[part 2 of 2: package /MICROSAR/Dem_swc/ComponentTypes]
AUTOSAR XML (schema 00046)
package /MICROSAR/Dem_swc/ComponentTypes  (continued)
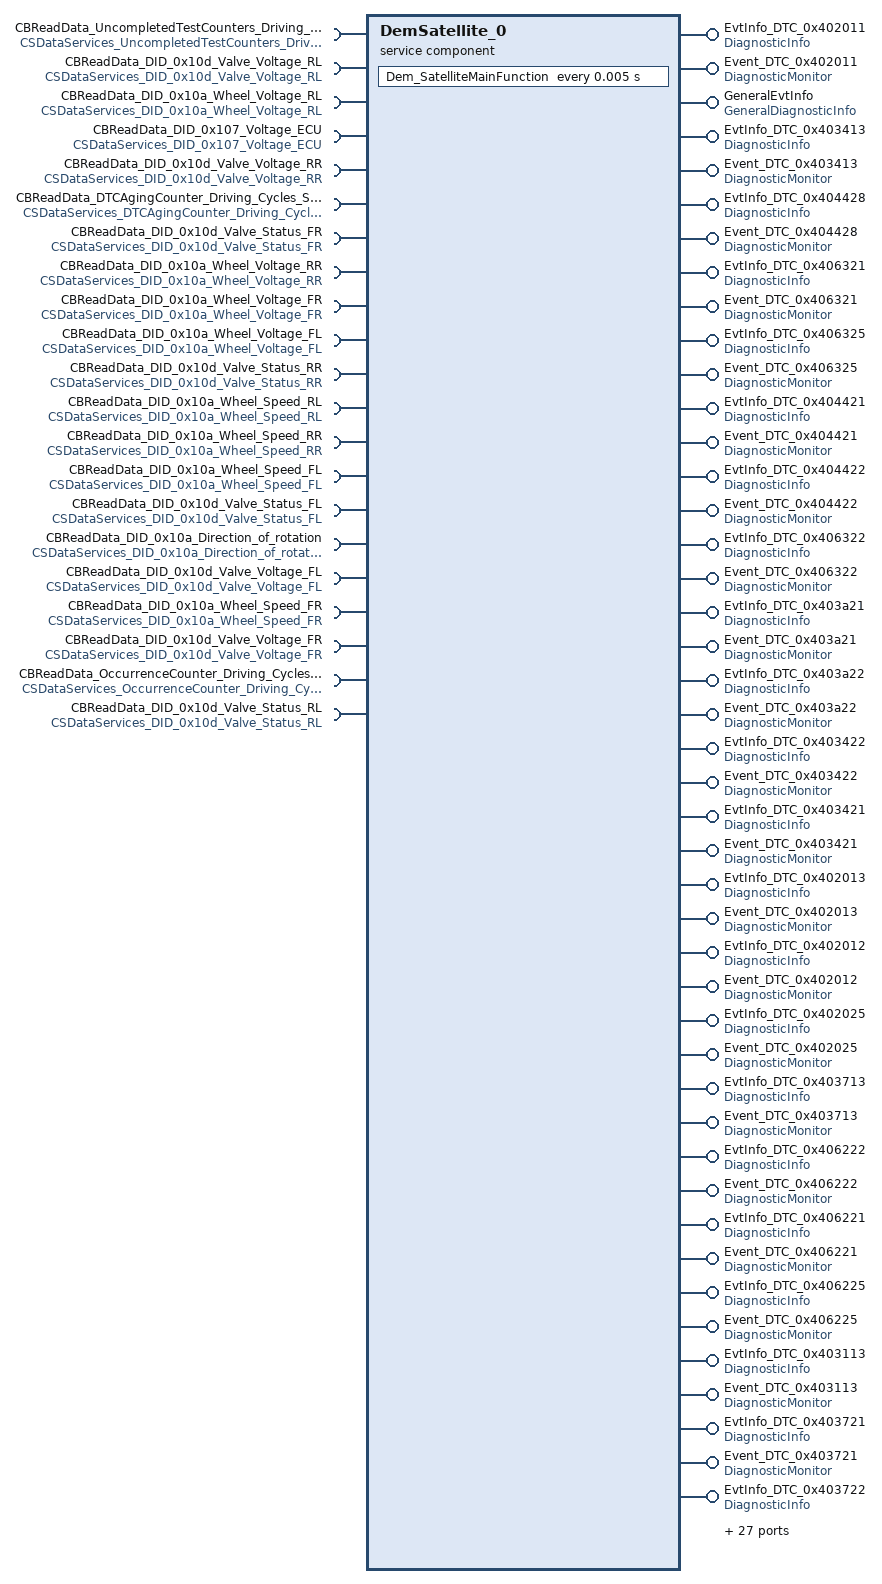
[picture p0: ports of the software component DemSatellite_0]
  service sw component type DemSatellite_0: category=SERVICE_COMPONENT
    63 x provide port:
      EvtInfo_DTC_0x402011: provided-interface=DiagnosticInfo
      Event_DTC_0x402011: provided-interface=DiagnosticMonitor
      GeneralEvtInfo: provided-interface=GeneralDiagnosticInfo
      EvtInfo_DTC_0x403413: provided-interface=DiagnosticInfo
      Event_DTC_0x403413: provided-interface=DiagnosticMonitor
      EvtInfo_DTC_0x404428: provided-interface=DiagnosticInfo
      Event_DTC_0x404428: provided-interface=DiagnosticMonitor
      EvtInfo_DTC_0x406321: provided-interface=DiagnosticInfo
      Event_DTC_0x406321: provided-interface=DiagnosticMonitor
      EvtInfo_DTC_0x406325: provided-interface=DiagnosticInfo
      Event_DTC_0x406325: provided-interface=DiagnosticMonitor
      EvtInfo_DTC_0x404421: provided-interface=DiagnosticInfo
      Event_DTC_0x404421: provided-interface=DiagnosticMonitor
      EvtInfo_DTC_0x404422: provided-interface=DiagnosticInfo
      Event_DTC_0x404422: provided-interface=DiagnosticMonitor
      EvtInfo_DTC_0x406322: provided-interface=DiagnosticInfo
      Event_DTC_0x406322: provided-interface=DiagnosticMonitor
      EvtInfo_DTC_0x403a21: provided-interface=DiagnosticInfo
      Event_DTC_0x403a21: provided-interface=DiagnosticMonitor
      EvtInfo_DTC_0x403a22: provided-interface=DiagnosticInfo
      Event_DTC_0x403a22: provided-interface=DiagnosticMonitor
      EvtInfo_DTC_0x403422: provided-interface=DiagnosticInfo
      Event_DTC_0x403422: provided-interface=DiagnosticMonitor
      EvtInfo_DTC_0x403421: provided-interface=DiagnosticInfo
      Event_DTC_0x403421: provided-interface=DiagnosticMonitor
      EvtInfo_DTC_0x402013: provided-interface=DiagnosticInfo
      Event_DTC_0x402013: provided-interface=DiagnosticMonitor
      EvtInfo_DTC_0x402012: provided-interface=DiagnosticInfo
      Event_DTC_0x402012: provided-interface=DiagnosticMonitor
      EvtInfo_DTC_0x402025: provided-interface=DiagnosticInfo
      Event_DTC_0x402025: provided-interface=DiagnosticMonitor
      EvtInfo_DTC_0x403713: provided-interface=DiagnosticInfo
      Event_DTC_0x403713: provided-interface=DiagnosticMonitor
      EvtInfo_DTC_0x406222: provided-interface=DiagnosticInfo
      Event_DTC_0x406222: provided-interface=DiagnosticMonitor
      EvtInfo_DTC_0x406221: provided-interface=DiagnosticInfo
      Event_DTC_0x406221: provided-interface=DiagnosticMonitor
      EvtInfo_DTC_0x406225: provided-interface=DiagnosticInfo
      Event_DTC_0x406225: provided-interface=DiagnosticMonitor
      EvtInfo_DTC_0x403113: provided-interface=DiagnosticInfo
      Event_DTC_0x403113: provided-interface=DiagnosticMonitor
      EvtInfo_DTC_0x403721: provided-interface=DiagnosticInfo
      Event_DTC_0x403721: provided-interface=DiagnosticMonitor
      EvtInfo_DTC_0x403722: provided-interface=DiagnosticInfo
      Event_DTC_0x403722: provided-interface=DiagnosticMonitor
      EvtInfo_DTC_0x404011: provided-interface=DiagnosticInfo
      Event_DTC_0x404011: provided-interface=DiagnosticMonitor
      EvtInfo_DTC_0x404212: provided-interface=DiagnosticInfo
      Event_DTC_0x404212: provided-interface=DiagnosticMonitor
      EvtInfo_DTC_0x404213: provided-interface=DiagnosticInfo
      Event_DTC_0x404213: provided-interface=DiagnosticMonitor
      EvtInfo_DTC_0x404012: provided-interface=DiagnosticInfo
      Event_DTC_0x404012: provided-interface=DiagnosticMonitor
      EvtInfo_DTC_0x403121: provided-interface=DiagnosticInfo
      Event_DTC_0x403121: provided-interface=DiagnosticMonitor
      EvtInfo_DTC_0x404211: provided-interface=DiagnosticInfo
      Event_DTC_0x404211: provided-interface=DiagnosticMonitor
      EvtInfo_DTC_0x404013: provided-interface=DiagnosticInfo
      Event_DTC_0x404013: provided-interface=DiagnosticMonitor
      EvtInfo_DTC_0x403122: provided-interface=DiagnosticInfo
      Event_DTC_0x403122: provided-interface=DiagnosticMonitor
      EvtInfo_DTC_0x403a13: provided-interface=DiagnosticInfo
      Event_DTC_0x403a13: provided-interface=DiagnosticMonitor
    21 x require port:
      CBReadData_UncompletedTestCounters_Driving_Cycles_Since_Last_Completed: required-interface=CSDataServices_UncompletedTestCounters_Driving_Cycles_Since_Last_Completed
      CBReadData_DID_0x10d_Valve_Voltage_RL: required-interface=CSDataServices_DID_0x10d_Valve_Voltage_RL
      CBReadData_DID_0x10a_Wheel_Voltage_RL: required-interface=CSDataServices_DID_0x10a_Wheel_Voltage_RL
      CBReadData_DID_0x107_Voltage_ECU: required-interface=CSDataServices_DID_0x107_Voltage_ECU
      CBReadData_DID_0x10d_Valve_Voltage_RR: required-interface=CSDataServices_DID_0x10d_Valve_Voltage_RR
      CBReadData_DTCAgingCounter_Driving_Cycles_Since_Last_Failed: required-interface=CSDataServices_DTCAgingCounter_Driving_Cycles_Since_Last_Failed
      CBReadData_DID_0x10d_Valve_Status_FR: required-interface=CSDataServices_DID_0x10d_Valve_Status_FR
      CBReadData_DID_0x10a_Wheel_Voltage_RR: required-interface=CSDataServices_DID_0x10a_Wheel_Voltage_RR
      CBReadData_DID_0x10a_Wheel_Voltage_FR: required-interface=CSDataServices_DID_0x10a_Wheel_Voltage_FR
      CBReadData_DID_0x10a_Wheel_Voltage_FL: required-interface=CSDataServices_DID_0x10a_Wheel_Voltage_FL
      CBReadData_DID_0x10d_Valve_Status_RR: required-interface=CSDataServices_DID_0x10d_Valve_Status_RR
      CBReadData_DID_0x10a_Wheel_Speed_RL: required-interface=CSDataServices_DID_0x10a_Wheel_Speed_RL
      CBReadData_DID_0x10a_Wheel_Speed_RR: required-interface=CSDataServices_DID_0x10a_Wheel_Speed_RR
      CBReadData_DID_0x10a_Wheel_Speed_FL: required-interface=CSDataServices_DID_0x10a_Wheel_Speed_FL
      CBReadData_DID_0x10d_Valve_Status_FL: required-interface=CSDataServices_DID_0x10d_Valve_Status_FL
      CBReadData_DID_0x10a_Direction_of_rotation: required-interface=CSDataServices_DID_0x10a_Direction_of_rotation
      CBReadData_DID_0x10d_Valve_Voltage_FL: required-interface=CSDataServices_DID_0x10d_Valve_Voltage_FL
      CBReadData_DID_0x10a_Wheel_Speed_FR: required-interface=CSDataServices_DID_0x10a_Wheel_Speed_FR
      CBReadData_DID_0x10d_Valve_Voltage_FR: required-interface=CSDataServices_DID_0x10d_Valve_Voltage_FR
      CBReadData_OccurrenceCounter_Driving_Cycles_Since_Test_Failed: required-interface=CSDataServices_OccurrenceCounter_Driving_Cycles_Since_Test_Failed
      CBReadData_DID_0x10d_Valve_Status_RL: required-interface=CSDataServices_DID_0x10d_Valve_Status_RL
    8 x provide port:
      EvtInfo_DTC_0x401003: provided-interface=DiagnosticInfo
      EvtInfo_DTC_0x401001: provided-interface=DiagnosticInfo
      Event_DTC_0x401001: provided-interface=DiagnosticMonitor
      Event_DTC_0x401003: provided-interface=DiagnosticMonitor
      EvtInfo_DTC_0x402001: provided-interface=DiagnosticInfo
      Event_DTC_0x402001: provided-interface=DiagnosticMonitor
      EvtInfo_DTC_0x403001: provided-interface=DiagnosticInfo
      Event_DTC_0x403001: provided-interface=DiagnosticMonitor
    behavior DemSatellite_0InternalBehavior: handle-termination-and-restart=NO-SUPPORT, included-data-type-set=data-type=[Dem_EventIdType, Dem_RatioIdType, Dem_EventStatusType, Dem_UdsStatusByteType, Dem_DTCFormatType, Dem_InitMonitorReasonType, Dem_OperationCycleStateType, Dem_DTCStatusMaskType, Dem_IndicatorStatusType, Dem_MaxDataValueType, Dem_DTCKindType, Dem_DTCGroupType, Dem_IumprDenomCondIdType, Dem_IumprDenomCondStatusType, Dem_DebounceResetStatusType, Dem_DebouncingStateType, Dem_IumprReadinessGroupType, Dem_DTRControlType, Dem_DTCSeverityType, Dem_MonitorStatusType]
      timing event Timer_Dem_SatelliteMainFunction: start-on-event=Dem_SatelliteMainFunction, period=0.005
      781 x operation invoked event:
        OpEventGetEventUdsStatus_GetEventUdsStatus_EvtInfo_DTC_0x402011: start-on-event=DemSatellite_0InternalBehavior/GetEventUdsStatus, operation=EvtInfo_DTC_0x402011.GetEventUdsStatus
        OpEventGetEventUdsStatus_GetEventUdsStatus_Event_DTC_0x402011: start-on-event=DemSatellite_0InternalBehavior/GetEventUdsStatus, operation=Event_DTC_0x402011.GetEventUdsStatus
        OpEventGetEventUdsStatus_GetEventUdsStatus_GeneralEvtInfo: start-on-event=DemSatellite_0InternalBehavior/GetEventUdsStatus, operation=GeneralEvtInfo.GetEventUdsStatus
        OpEventGetEventStatus_GetEventStatus_EvtInfo_DTC_0x402011: start-on-event=DemSatellite_0InternalBehavior/GetEventStatus, operation=EvtInfo_DTC_0x402011.GetEventStatus
        OpEventGetEventStatus_GetEventStatus_Event_DTC_0x402011: start-on-event=DemSatellite_0InternalBehavior/GetEventStatus, operation=Event_DTC_0x402011.GetEventStatus
        OpEventGetEventStatus_GetEventStatus_GeneralEvtInfo: start-on-event=DemSatellite_0InternalBehavior/GetEventStatus, operation=GeneralEvtInfo.GetEventStatus
        OpEventGetEventFailed_GetEventFailed_EvtInfo_DTC_0x402011: start-on-event=DemSatellite_0InternalBehavior/GetEventFailed, operation=EvtInfo_DTC_0x402011.GetEventFailed
        OpEventGetEventFailed_GetEventFailed_Event_DTC_0x402011: start-on-event=DemSatellite_0InternalBehavior/GetEventFailed, operation=Event_DTC_0x402011.GetEventFailed
        OpEventGetEventFailed_GetEventFailed_GeneralEvtInfo: start-on-event=DemSatellite_0InternalBehavior/GetEventFailed, operation=GeneralEvtInfo.GetEventFailed
        OpEventGetEventTested_GetEventTested_EvtInfo_DTC_0x402011: start-on-event=DemSatellite_0InternalBehavior/GetEventTested, operation=EvtInfo_DTC_0x402011.GetEventTested
        OpEventGetEventTested_GetEventTested_Event_DTC_0x402011: start-on-event=DemSatellite_0InternalBehavior/GetEventTested, operation=Event_DTC_0x402011.GetEventTested
        OpEventGetEventTested_GetEventTested_GeneralEvtInfo: start-on-event=DemSatellite_0InternalBehavior/GetEventTested, operation=GeneralEvtInfo.GetEventTested
        OpEventGetDTCOfEvent_GetDTCOfEvent_EvtInfo_DTC_0x402011: start-on-event=DemSatellite_0InternalBehavior/GetDTCOfEvent, operation=EvtInfo_DTC_0x402011.GetDTCOfEvent
        OpEventGetDTCOfEvent_GetDTCOfEvent_Event_DTC_0x402011: start-on-event=DemSatellite_0InternalBehavior/GetDTCOfEvent, operation=Event_DTC_0x402011.GetDTCOfEvent
        OpEventGetDTCOfEvent_GetDTCOfEvent_GeneralEvtInfo: start-on-event=DemSatellite_0InternalBehavior/GetDTCOfEvent, operation=GeneralEvtInfo.GetDTCOfEvent
        OpEventGetFaultDetectionCounter_GetFaultDetectionCounter_EvtInfo_DTC_0x402011: start-on-event=DemSatellite_0InternalBehavior/GetFaultDetectionCounter, operation=EvtInfo_DTC_0x402011.GetFaultDetectionCounter
        OpEventGetFaultDetectionCounter_GetFaultDetectionCounter_Event_DTC_0x402011: start-on-event=DemSatellite_0InternalBehavior/GetFaultDetectionCounter, operation=Event_DTC_0x402011.GetFaultDetectionCounter
        OpEventGetFaultDetectionCounter_GetFaultDetectionCounter_GeneralEvtInfo: start-on-event=DemSatellite_0InternalBehavior/GetFaultDetectionCounter, operation=GeneralEvtInfo.GetFaultDetectionCounter
        OpEventGetEventFreezeFrameDataEx_GetEventFreezeFrameDataEx_EvtInfo_DTC_0x402011: start-on-event=DemSatellite_0InternalBehavior/GetEventFreezeFrameDataEx, operation=EvtInfo_DTC_0x402011.GetEventFreezeFrameDataEx
        OpEventGetEventFreezeFrameDataEx_GetEventFreezeFrameDataEx_Event_DTC_0x402011: start-on-event=DemSatellite_0InternalBehavior/GetEventFreezeFrameDataEx, operation=Event_DTC_0x402011.GetEventFreezeFrameDataEx
        OpEventGetEventFreezeFrameDataEx_GetEventFreezeFrameDataEx_GeneralEvtInfo: start-on-event=DemSatellite_0InternalBehavior/GetEventFreezeFrameDataEx, operation=GeneralEvtInfo.GetEventFreezeFrameDataEx
        OpEventGetEventExtendedDataRecordEx_GetEventExtendedDataRecordEx_EvtInfo_DTC_0x402011: start-on-event=DemSatellite_0InternalBehavior/GetEventExtendedDataRecordEx, operation=EvtInfo_DTC_0x402011.GetEventExtendedDataRecordEx
        OpEventGetEventExtendedDataRecordEx_GetEventExtendedDataRecordEx_Event_DTC_0x402011: start-on-event=DemSatellite_0InternalBehavior/GetEventExtendedDataRecordEx, operation=Event_DTC_0x402011.GetEventExtendedDataRecordEx
        OpEventGetEventExtendedDataRecordEx_GetEventExtendedDataRecordEx_GeneralEvtInfo: start-on-event=DemSatellite_0InternalBehavior/GetEventExtendedDataRecordEx, operation=GeneralEvtInfo.GetEventExtendedDataRecordEx
        OpEventGetEventEnableCondition_GetEventEnableCondition_EvtInfo_DTC_0x402011: start-on-event=DemSatellite_0InternalBehavior/GetEventEnableCondition, operation=EvtInfo_DTC_0x402011.GetEventEnableCondition
        OpEventGetEventEnableCondition_GetEventEnableCondition_GeneralEvtInfo: start-on-event=DemSatellite_0InternalBehavior/GetEventEnableCondition, operation=GeneralEvtInfo.GetEventEnableCondition
        OpEventGetDebouncingOfEvent_GetDebouncingOfEvent_EvtInfo_DTC_0x402011: start-on-event=DemSatellite_0InternalBehavior/GetDebouncingOfEvent, operation=EvtInfo_DTC_0x402011.GetDebouncingOfEvent
        OpEventGetDebouncingOfEvent_GetDebouncingOfEvent_GeneralEvtInfo: start-on-event=DemSatellite_0InternalBehavior/GetDebouncingOfEvent, operation=GeneralEvtInfo.GetDebouncingOfEvent
        OpEventGetMonitorStatus_GetMonitorStatus_EvtInfo_DTC_0x402011: start-on-event=DemSatellite_0InternalBehavior/GetMonitorStatus, operation=EvtInfo_DTC_0x402011.GetMonitorStatus
        OpEventGetMonitorStatus_GetMonitorStatus_GeneralEvtInfo: start-on-event=DemSatellite_0InternalBehavior/GetMonitorStatus, operation=GeneralEvtInfo.GetMonitorStatus
        OpEventSetEventStatus_SetEventStatus_Event_DTC_0x402011: start-on-event=SetEventStatus, operation=Event_DTC_0x402011.SetEventStatus
        OpEventResetEventStatus_ResetEventStatus_Event_DTC_0x402011: start-on-event=ResetEventStatus, operation=Event_DTC_0x402011.ResetEventStatus
        OpEventResetEventDebounceStatus_ResetEventDebounceStatus_Event_DTC_0x402011: start-on-event=ResetEventDebounceStatus, operation=Event_DTC_0x402011.ResetEventDebounceStatus
        OpEventGetEventUdsStatus_GetEventUdsStatus_EvtInfo_DTC_0x403413: start-on-event=DemSatellite_0InternalBehavior/GetEventUdsStatus, operation=EvtInfo_DTC_0x403413.GetEventUdsStatus
        OpEventGetEventUdsStatus_GetEventUdsStatus_Event_DTC_0x403413: start-on-event=DemSatellite_0InternalBehavior/GetEventUdsStatus, operation=Event_DTC_0x403413.GetEventUdsStatus
        OpEventGetEventUdsStatus_GetEventUdsStatus_EvtInfo_DTC_0x404428: start-on-event=DemSatellite_0InternalBehavior/GetEventUdsStatus, operation=EvtInfo_DTC_0x404428.GetEventUdsStatus
        OpEventGetEventUdsStatus_GetEventUdsStatus_Event_DTC_0x404428: start-on-event=DemSatellite_0InternalBehavior/GetEventUdsStatus, operation=Event_DTC_0x404428.GetEventUdsStatus
        OpEventGetEventUdsStatus_GetEventUdsStatus_EvtInfo_DTC_0x406321: start-on-event=DemSatellite_0InternalBehavior/GetEventUdsStatus, operation=EvtInfo_DTC_0x406321.GetEventUdsStatus
        OpEventGetEventUdsStatus_GetEventUdsStatus_Event_DTC_0x406321: start-on-event=DemSatellite_0InternalBehavior/GetEventUdsStatus, operation=Event_DTC_0x406321.GetEventUdsStatus
        OpEventGetEventUdsStatus_GetEventUdsStatus_EvtInfo_DTC_0x406325: start-on-event=DemSatellite_0InternalBehavior/GetEventUdsStatus, operation=EvtInfo_DTC_0x406325.GetEventUdsStatus
        OpEventGetEventUdsStatus_GetEventUdsStatus_Event_DTC_0x406325: start-on-event=DemSatellite_0InternalBehavior/GetEventUdsStatus, operation=Event_DTC_0x406325.GetEventUdsStatus
        OpEventGetEventUdsStatus_GetEventUdsStatus_EvtInfo_DTC_0x404421: start-on-event=DemSatellite_0InternalBehavior/GetEventUdsStatus, operation=EvtInfo_DTC_0x404421.GetEventUdsStatus
        OpEventGetEventUdsStatus_GetEventUdsStatus_Event_DTC_0x404421: start-on-event=DemSatellite_0InternalBehavior/GetEventUdsStatus, operation=Event_DTC_0x404421.GetEventUdsStatus
        OpEventGetEventUdsStatus_GetEventUdsStatus_EvtInfo_DTC_0x404422: start-on-event=DemSatellite_0InternalBehavior/GetEventUdsStatus, operation=EvtInfo_DTC_0x404422.GetEventUdsStatus
        OpEventGetEventUdsStatus_GetEventUdsStatus_Event_DTC_0x404422: start-on-event=DemSatellite_0InternalBehavior/GetEventUdsStatus, operation=Event_DTC_0x404422.GetEventUdsStatus
        OpEventGetEventUdsStatus_GetEventUdsStatus_EvtInfo_DTC_0x406322: start-on-event=DemSatellite_0InternalBehavior/GetEventUdsStatus, operation=EvtInfo_DTC_0x406322.GetEventUdsStatus
        OpEventGetEventUdsStatus_GetEventUdsStatus_Event_DTC_0x406322: start-on-event=DemSatellite_0InternalBehavior/GetEventUdsStatus, operation=Event_DTC_0x406322.GetEventUdsStatus
        OpEventGetEventUdsStatus_GetEventUdsStatus_EvtInfo_DTC_0x403a21: start-on-event=DemSatellite_0InternalBehavior/GetEventUdsStatus, operation=EvtInfo_DTC_0x403a21.GetEventUdsStatus
        OpEventGetEventUdsStatus_GetEventUdsStatus_Event_DTC_0x403a21: start-on-event=DemSatellite_0InternalBehavior/GetEventUdsStatus, operation=Event_DTC_0x403a21.GetEventUdsStatus
        OpEventGetEventUdsStatus_GetEventUdsStatus_EvtInfo_DTC_0x403a22: start-on-event=DemSatellite_0InternalBehavior/GetEventUdsStatus, operation=EvtInfo_DTC_0x403a22.GetEventUdsStatus
        OpEventGetEventUdsStatus_GetEventUdsStatus_Event_DTC_0x403a22: start-on-event=DemSatellite_0InternalBehavior/GetEventUdsStatus, operation=Event_DTC_0x403a22.GetEventUdsStatus
        OpEventGetEventUdsStatus_GetEventUdsStatus_EvtInfo_DTC_0x403422: start-on-event=DemSatellite_0InternalBehavior/GetEventUdsStatus, operation=EvtInfo_DTC_0x403422.GetEventUdsStatus
        OpEventGetEventUdsStatus_GetEventUdsStatus_Event_DTC_0x403422: start-on-event=DemSatellite_0InternalBehavior/GetEventUdsStatus, operation=Event_DTC_0x403422.GetEventUdsStatus
        OpEventGetEventUdsStatus_GetEventUdsStatus_EvtInfo_DTC_0x403421: start-on-event=DemSatellite_0InternalBehavior/GetEventUdsStatus, operation=EvtInfo_DTC_0x403421.GetEventUdsStatus
        OpEventGetEventUdsStatus_GetEventUdsStatus_Event_DTC_0x403421: start-on-event=DemSatellite_0InternalBehavior/GetEventUdsStatus, operation=Event_DTC_0x403421.GetEventUdsStatus
        OpEventGetEventUdsStatus_GetEventUdsStatus_EvtInfo_DTC_0x402013: start-on-event=DemSatellite_0InternalBehavior/GetEventUdsStatus, operation=EvtInfo_DTC_0x402013.GetEventUdsStatus
        OpEventGetEventUdsStatus_GetEventUdsStatus_Event_DTC_0x402013: start-on-event=DemSatellite_0InternalBehavior/GetEventUdsStatus, operation=Event_DTC_0x402013.GetEventUdsStatus
        OpEventGetEventUdsStatus_GetEventUdsStatus_EvtInfo_DTC_0x402012: start-on-event=DemSatellite_0InternalBehavior/GetEventUdsStatus, operation=EvtInfo_DTC_0x402012.GetEventUdsStatus
        OpEventGetEventUdsStatus_GetEventUdsStatus_Event_DTC_0x402012: start-on-event=DemSatellite_0InternalBehavior/GetEventUdsStatus, operation=Event_DTC_0x402012.GetEventUdsStatus
        OpEventGetEventUdsStatus_GetEventUdsStatus_EvtInfo_DTC_0x402025: start-on-event=DemSatellite_0InternalBehavior/GetEventUdsStatus, operation=EvtInfo_DTC_0x402025.GetEventUdsStatus
        OpEventGetEventUdsStatus_GetEventUdsStatus_Event_DTC_0x402025: start-on-event=DemSatellite_0InternalBehavior/GetEventUdsStatus, operation=Event_DTC_0x402025.GetEventUdsStatus
        OpEventGetEventUdsStatus_GetEventUdsStatus_EvtInfo_DTC_0x403713: start-on-event=DemSatellite_0InternalBehavior/GetEventUdsStatus, operation=EvtInfo_DTC_0x403713.GetEventUdsStatus
        OpEventGetEventUdsStatus_GetEventUdsStatus_Event_DTC_0x403713: start-on-event=DemSatellite_0InternalBehavior/GetEventUdsStatus, operation=Event_DTC_0x403713.GetEventUdsStatus
        OpEventGetEventUdsStatus_GetEventUdsStatus_EvtInfo_DTC_0x406222: start-on-event=DemSatellite_0InternalBehavior/GetEventUdsStatus, operation=EvtInfo_DTC_0x406222.GetEventUdsStatus
        OpEventGetEventUdsStatus_GetEventUdsStatus_Event_DTC_0x406222: start-on-event=DemSatellite_0InternalBehavior/GetEventUdsStatus, operation=Event_DTC_0x406222.GetEventUdsStatus
        OpEventGetEventUdsStatus_GetEventUdsStatus_EvtInfo_DTC_0x406221: start-on-event=DemSatellite_0InternalBehavior/GetEventUdsStatus, operation=EvtInfo_DTC_0x406221.GetEventUdsStatus
        OpEventGetEventUdsStatus_GetEventUdsStatus_Event_DTC_0x406221: start-on-event=DemSatellite_0InternalBehavior/GetEventUdsStatus, operation=Event_DTC_0x406221.GetEventUdsStatus
        OpEventGetEventUdsStatus_GetEventUdsStatus_EvtInfo_DTC_0x406225: start-on-event=DemSatellite_0InternalBehavior/GetEventUdsStatus, operation=EvtInfo_DTC_0x406225.GetEventUdsStatus
        OpEventGetEventUdsStatus_GetEventUdsStatus_Event_DTC_0x406225: start-on-event=DemSatellite_0InternalBehavior/GetEventUdsStatus, operation=Event_DTC_0x406225.GetEventUdsStatus
        OpEventGetEventUdsStatus_GetEventUdsStatus_EvtInfo_DTC_0x403113: start-on-event=DemSatellite_0InternalBehavior/GetEventUdsStatus, operation=EvtInfo_DTC_0x403113.GetEventUdsStatus
        OpEventGetEventUdsStatus_GetEventUdsStatus_Event_DTC_0x403113: start-on-event=DemSatellite_0InternalBehavior/GetEventUdsStatus, operation=Event_DTC_0x403113.GetEventUdsStatus
        OpEventGetEventUdsStatus_GetEventUdsStatus_EvtInfo_DTC_0x403721: start-on-event=DemSatellite_0InternalBehavior/GetEventUdsStatus, operation=EvtInfo_DTC_0x403721.GetEventUdsStatus
        OpEventGetEventUdsStatus_GetEventUdsStatus_Event_DTC_0x403721: start-on-event=DemSatellite_0InternalBehavior/GetEventUdsStatus, operation=Event_DTC_0x403721.GetEventUdsStatus
        OpEventGetEventUdsStatus_GetEventUdsStatus_EvtInfo_DTC_0x403722: start-on-event=DemSatellite_0InternalBehavior/GetEventUdsStatus, operation=EvtInfo_DTC_0x403722.GetEventUdsStatus
        OpEventGetEventUdsStatus_GetEventUdsStatus_Event_DTC_0x403722: start-on-event=DemSatellite_0InternalBehavior/GetEventUdsStatus, operation=Event_DTC_0x403722.GetEventUdsStatus
        OpEventGetEventUdsStatus_GetEventUdsStatus_EvtInfo_DTC_0x404011: start-on-event=DemSatellite_0InternalBehavior/GetEventUdsStatus, operation=EvtInfo_DTC_0x404011.GetEventUdsStatus
        OpEventGetEventUdsStatus_GetEventUdsStatus_Event_DTC_0x404011: start-on-event=DemSatellite_0InternalBehavior/GetEventUdsStatus, operation=Event_DTC_0x404011.GetEventUdsStatus
        OpEventGetEventUdsStatus_GetEventUdsStatus_EvtInfo_DTC_0x404212: start-on-event=DemSatellite_0InternalBehavior/GetEventUdsStatus, operation=EvtInfo_DTC_0x404212.GetEventUdsStatus
        OpEventGetEventUdsStatus_GetEventUdsStatus_Event_DTC_0x404212: start-on-event=DemSatellite_0InternalBehavior/GetEventUdsStatus, operation=Event_DTC_0x404212.GetEventUdsStatus
        OpEventGetEventUdsStatus_GetEventUdsStatus_EvtInfo_DTC_0x404213: start-on-event=DemSatellite_0InternalBehavior/GetEventUdsStatus, operation=EvtInfo_DTC_0x404213.GetEventUdsStatus
        OpEventGetEventUdsStatus_GetEventUdsStatus_Event_DTC_0x404213: start-on-event=DemSatellite_0InternalBehavior/GetEventUdsStatus, operation=Event_DTC_0x404213.GetEventUdsStatus
        OpEventGetEventUdsStatus_GetEventUdsStatus_EvtInfo_DTC_0x404012: start-on-event=DemSatellite_0InternalBehavior/GetEventUdsStatus, operation=EvtInfo_DTC_0x404012.GetEventUdsStatus
        OpEventGetEventUdsStatus_GetEventUdsStatus_Event_DTC_0x404012: start-on-event=DemSatellite_0InternalBehavior/GetEventUdsStatus, operation=Event_DTC_0x404012.GetEventUdsStatus
        OpEventGetEventUdsStatus_GetEventUdsStatus_EvtInfo_DTC_0x403121: start-on-event=DemSatellite_0InternalBehavior/GetEventUdsStatus, operation=EvtInfo_DTC_0x403121.GetEventUdsStatus
        OpEventGetEventUdsStatus_GetEventUdsStatus_Event_DTC_0x403121: start-on-event=DemSatellite_0InternalBehavior/GetEventUdsStatus, operation=Event_DTC_0x403121.GetEventUdsStatus
        OpEventGetEventUdsStatus_GetEventUdsStatus_EvtInfo_DTC_0x404211: start-on-event=DemSatellite_0InternalBehavior/GetEventUdsStatus, operation=EvtInfo_DTC_0x404211.GetEventUdsStatus
        OpEventGetEventUdsStatus_GetEventUdsStatus_Event_DTC_0x404211: start-on-event=DemSatellite_0InternalBehavior/GetEventUdsStatus, operation=Event_DTC_0x404211.GetEventUdsStatus
        OpEventGetEventUdsStatus_GetEventUdsStatus_EvtInfo_DTC_0x404013: start-on-event=DemSatellite_0InternalBehavior/GetEventUdsStatus, operation=EvtInfo_DTC_0x404013.GetEventUdsStatus
        OpEventGetEventUdsStatus_GetEventUdsStatus_Event_DTC_0x404013: start-on-event=DemSatellite_0InternalBehavior/GetEventUdsStatus, operation=Event_DTC_0x404013.GetEventUdsStatus
        OpEventGetEventUdsStatus_GetEventUdsStatus_EvtInfo_DTC_0x403122: start-on-event=DemSatellite_0InternalBehavior/GetEventUdsStatus, operation=EvtInfo_DTC_0x403122.GetEventUdsStatus
        OpEventGetEventUdsStatus_GetEventUdsStatus_Event_DTC_0x403122: start-on-event=DemSatellite_0InternalBehavior/GetEventUdsStatus, operation=Event_DTC_0x403122.GetEventUdsStatus
        OpEventGetEventUdsStatus_GetEventUdsStatus_EvtInfo_DTC_0x403a13: start-on-event=DemSatellite_0InternalBehavior/GetEventUdsStatus, operation=EvtInfo_DTC_0x403a13.GetEventUdsStatus
        OpEventGetEventUdsStatus_GetEventUdsStatus_Event_DTC_0x403a13: start-on-event=DemSatellite_0InternalBehavior/GetEventUdsStatus, operation=Event_DTC_0x403a13.GetEventUdsStatus
        OpEventGetEventStatus_GetEventStatus_EvtInfo_DTC_0x403413: start-on-event=DemSatellite_0InternalBehavior/GetEventStatus, operation=EvtInfo_DTC_0x403413.GetEventStatus
        OpEventGetEventStatus_GetEventStatus_Event_DTC_0x403413: start-on-event=DemSatellite_0InternalBehavior/GetEventStatus, operation=Event_DTC_0x403413.GetEventStatus
        OpEventGetEventStatus_GetEventStatus_EvtInfo_DTC_0x404428: start-on-event=DemSatellite_0InternalBehavior/GetEventStatus, operation=EvtInfo_DTC_0x404428.GetEventStatus
        OpEventGetEventStatus_GetEventStatus_Event_DTC_0x404428: start-on-event=DemSatellite_0InternalBehavior/GetEventStatus, operation=Event_DTC_0x404428.GetEventStatus
        OpEventGetEventStatus_GetEventStatus_EvtInfo_DTC_0x406321: start-on-event=DemSatellite_0InternalBehavior/GetEventStatus, operation=EvtInfo_DTC_0x406321.GetEventStatus
        OpEventGetEventStatus_GetEventStatus_Event_DTC_0x406321: start-on-event=DemSatellite_0InternalBehavior/GetEventStatus, operation=Event_DTC_0x406321.GetEventStatus
        OpEventGetEventStatus_GetEventStatus_EvtInfo_DTC_0x406325: start-on-event=DemSatellite_0InternalBehavior/GetEventStatus, operation=EvtInfo_DTC_0x406325.GetEventStatus
        OpEventGetEventStatus_GetEventStatus_Event_DTC_0x406325: start-on-event=DemSatellite_0InternalBehavior/GetEventStatus, operation=Event_DTC_0x406325.GetEventStatus
        OpEventGetEventStatus_GetEventStatus_EvtInfo_DTC_0x404421: start-on-event=DemSatellite_0InternalBehavior/GetEventStatus, operation=EvtInfo_DTC_0x404421.GetEventStatus
        OpEventGetEventStatus_GetEventStatus_Event_DTC_0x404421: start-on-event=DemSatellite_0InternalBehavior/GetEventStatus, operation=Event_DTC_0x404421.GetEventStatus
        OpEventGetEventStatus_GetEventStatus_EvtInfo_DTC_0x404422: start-on-event=DemSatellite_0InternalBehavior/GetEventStatus, operation=EvtInfo_DTC_0x404422.GetEventStatus
        OpEventGetEventStatus_GetEventStatus_Event_DTC_0x404422: start-on-event=DemSatellite_0InternalBehavior/GetEventStatus, operation=Event_DTC_0x404422.GetEventStatus
        OpEventGetEventStatus_GetEventStatus_EvtInfo_DTC_0x406322: start-on-event=DemSatellite_0InternalBehavior/GetEventStatus, operation=EvtInfo_DTC_0x406322.GetEventStatus
        OpEventGetEventStatus_GetEventStatus_Event_DTC_0x406322: start-on-event=DemSatellite_0InternalBehavior/GetEventStatus, operation=Event_DTC_0x406322.GetEventStatus
        OpEventGetEventStatus_GetEventStatus_EvtInfo_DTC_0x403a21: start-on-event=DemSatellite_0InternalBehavior/GetEventStatus, operation=EvtInfo_DTC_0x403a21.GetEventStatus
        OpEventGetEventStatus_GetEventStatus_Event_DTC_0x403a21: start-on-event=DemSatellite_0InternalBehavior/GetEventStatus, operation=Event_DTC_0x403a21.GetEventStatus
        OpEventGetEventStatus_GetEventStatus_EvtInfo_DTC_0x403a22: start-on-event=DemSatellite_0InternalBehavior/GetEventStatus, operation=EvtInfo_DTC_0x403a22.GetEventStatus
        OpEventGetEventStatus_GetEventStatus_Event_DTC_0x403a22: start-on-event=DemSatellite_0InternalBehavior/GetEventStatus, operation=Event_DTC_0x403a22.GetEventStatus
        OpEventGetEventStatus_GetEventStatus_EvtInfo_DTC_0x403422: start-on-event=DemSatellite_0InternalBehavior/GetEventStatus, operation=EvtInfo_DTC_0x403422.GetEventStatus
        OpEventGetEventStatus_GetEventStatus_Event_DTC_0x403422: start-on-event=DemSatellite_0InternalBehavior/GetEventStatus, operation=Event_DTC_0x403422.GetEventStatus
        OpEventGetEventStatus_GetEventStatus_EvtInfo_DTC_0x403421: start-on-event=DemSatellite_0InternalBehavior/GetEventStatus, operation=EvtInfo_DTC_0x403421.GetEventStatus
        OpEventGetEventStatus_GetEventStatus_Event_DTC_0x403421: start-on-event=DemSatellite_0InternalBehavior/GetEventStatus, operation=Event_DTC_0x403421.GetEventStatus
        OpEventGetEventStatus_GetEventStatus_EvtInfo_DTC_0x402013: start-on-event=DemSatellite_0InternalBehavior/GetEventStatus, operation=EvtInfo_DTC_0x402013.GetEventStatus
        OpEventGetEventStatus_GetEventStatus_Event_DTC_0x402013: start-on-event=DemSatellite_0InternalBehavior/GetEventStatus, operation=Event_DTC_0x402013.GetEventStatus
        OpEventGetEventStatus_GetEventStatus_EvtInfo_DTC_0x402012: start-on-event=DemSatellite_0InternalBehavior/GetEventStatus, operation=EvtInfo_DTC_0x402012.GetEventStatus
        OpEventGetEventStatus_GetEventStatus_Event_DTC_0x402012: start-on-event=DemSatellite_0InternalBehavior/GetEventStatus, operation=Event_DTC_0x402012.GetEventStatus
        OpEventGetEventStatus_GetEventStatus_EvtInfo_DTC_0x402025: start-on-event=DemSatellite_0InternalBehavior/GetEventStatus, operation=EvtInfo_DTC_0x402025.GetEventStatus
        OpEventGetEventStatus_GetEventStatus_Event_DTC_0x402025: start-on-event=DemSatellite_0InternalBehavior/GetEventStatus, operation=Event_DTC_0x402025.GetEventStatus
        OpEventGetEventStatus_GetEventStatus_EvtInfo_DTC_0x403713: start-on-event=DemSatellite_0InternalBehavior/GetEventStatus, operation=EvtInfo_DTC_0x403713.GetEventStatus
        OpEventGetEventStatus_GetEventStatus_Event_DTC_0x403713: start-on-event=DemSatellite_0InternalBehavior/GetEventStatus, operation=Event_DTC_0x403713.GetEventStatus
        OpEventGetEventStatus_GetEventStatus_EvtInfo_DTC_0x406222: start-on-event=DemSatellite_0InternalBehavior/GetEventStatus, operation=EvtInfo_DTC_0x406222.GetEventStatus
        OpEventGetEventStatus_GetEventStatus_Event_DTC_0x406222: start-on-event=DemSatellite_0InternalBehavior/GetEventStatus, operation=Event_DTC_0x406222.GetEventStatus
        OpEventGetEventStatus_GetEventStatus_EvtInfo_DTC_0x406221: start-on-event=DemSatellite_0InternalBehavior/GetEventStatus, operation=EvtInfo_DTC_0x406221.GetEventStatus
        OpEventGetEventStatus_GetEventStatus_Event_DTC_0x406221: start-on-event=DemSatellite_0InternalBehavior/GetEventStatus, operation=Event_DTC_0x406221.GetEventStatus
        OpEventGetEventStatus_GetEventStatus_EvtInfo_DTC_0x406225: start-on-event=DemSatellite_0InternalBehavior/GetEventStatus, operation=EvtInfo_DTC_0x406225.GetEventStatus
        OpEventGetEventStatus_GetEventStatus_Event_DTC_0x406225: start-on-event=DemSatellite_0InternalBehavior/GetEventStatus, operation=Event_DTC_0x406225.GetEventStatus
        OpEventGetEventStatus_GetEventStatus_EvtInfo_DTC_0x403113: start-on-event=DemSatellite_0InternalBehavior/GetEventStatus, operation=EvtInfo_DTC_0x403113.GetEventStatus
        OpEventGetEventStatus_GetEventStatus_Event_DTC_0x403113: start-on-event=DemSatellite_0InternalBehavior/GetEventStatus, operation=Event_DTC_0x403113.GetEventStatus
        OpEventGetEventStatus_GetEventStatus_EvtInfo_DTC_0x403721: start-on-event=DemSatellite_0InternalBehavior/GetEventStatus, operation=EvtInfo_DTC_0x403721.GetEventStatus
        OpEventGetEventStatus_GetEventStatus_Event_DTC_0x403721: start-on-event=DemSatellite_0InternalBehavior/GetEventStatus, operation=Event_DTC_0x403721.GetEventStatus
        OpEventGetEventStatus_GetEventStatus_EvtInfo_DTC_0x403722: start-on-event=DemSatellite_0InternalBehavior/GetEventStatus, operation=EvtInfo_DTC_0x403722.GetEventStatus
        OpEventGetEventStatus_GetEventStatus_Event_DTC_0x403722: start-on-event=DemSatellite_0InternalBehavior/GetEventStatus, operation=Event_DTC_0x403722.GetEventStatus
        OpEventGetEventStatus_GetEventStatus_EvtInfo_DTC_0x404011: start-on-event=DemSatellite_0InternalBehavior/GetEventStatus, operation=EvtInfo_DTC_0x404011.GetEventStatus
        OpEventGetEventStatus_GetEventStatus_Event_DTC_0x404011: start-on-event=DemSatellite_0InternalBehavior/GetEventStatus, operation=Event_DTC_0x404011.GetEventStatus
        OpEventGetEventStatus_GetEventStatus_EvtInfo_DTC_0x404212: start-on-event=DemSatellite_0InternalBehavior/GetEventStatus, operation=EvtInfo_DTC_0x404212.GetEventStatus
        OpEventGetEventStatus_GetEventStatus_Event_DTC_0x404212: start-on-event=DemSatellite_0InternalBehavior/GetEventStatus, operation=Event_DTC_0x404212.GetEventStatus
        OpEventGetEventStatus_GetEventStatus_EvtInfo_DTC_0x404213: start-on-event=DemSatellite_0InternalBehavior/GetEventStatus, operation=EvtInfo_DTC_0x404213.GetEventStatus
        OpEventGetEventStatus_GetEventStatus_Event_DTC_0x404213: start-on-event=DemSatellite_0InternalBehavior/GetEventStatus, operation=Event_DTC_0x404213.GetEventStatus
        OpEventGetEventStatus_GetEventStatus_EvtInfo_DTC_0x404012: start-on-event=DemSatellite_0InternalBehavior/GetEventStatus, operation=EvtInfo_DTC_0x404012.GetEventStatus
        OpEventGetEventStatus_GetEventStatus_Event_DTC_0x404012: start-on-event=DemSatellite_0InternalBehavior/GetEventStatus, operation=Event_DTC_0x404012.GetEventStatus
        OpEventGetEventStatus_GetEventStatus_EvtInfo_DTC_0x403121: start-on-event=DemSatellite_0InternalBehavior/GetEventStatus, operation=EvtInfo_DTC_0x403121.GetEventStatus
        OpEventGetEventStatus_GetEventStatus_Event_DTC_0x403121: start-on-event=DemSatellite_0InternalBehavior/GetEventStatus, operation=Event_DTC_0x403121.GetEventStatus
        OpEventGetEventStatus_GetEventStatus_EvtInfo_DTC_0x404211: start-on-event=DemSatellite_0InternalBehavior/GetEventStatus, operation=EvtInfo_DTC_0x404211.GetEventStatus
        OpEventGetEventStatus_GetEventStatus_Event_DTC_0x404211: start-on-event=DemSatellite_0InternalBehavior/GetEventStatus, operation=Event_DTC_0x404211.GetEventStatus
        OpEventGetEventStatus_GetEventStatus_EvtInfo_DTC_0x404013: start-on-event=DemSatellite_0InternalBehavior/GetEventStatus, operation=EvtInfo_DTC_0x404013.GetEventStatus
        OpEventGetEventStatus_GetEventStatus_Event_DTC_0x404013: start-on-event=DemSatellite_0InternalBehavior/GetEventStatus, operation=Event_DTC_0x404013.GetEventStatus
        OpEventGetEventStatus_GetEventStatus_EvtInfo_DTC_0x403122: start-on-event=DemSatellite_0InternalBehavior/GetEventStatus, operation=EvtInfo_DTC_0x403122.GetEventStatus
        OpEventGetEventStatus_GetEventStatus_Event_DTC_0x403122: start-on-event=DemSatellite_0InternalBehavior/GetEventStatus, operation=Event_DTC_0x403122.GetEventStatus
        OpEventGetEventStatus_GetEventStatus_EvtInfo_DTC_0x403a13: start-on-event=DemSatellite_0InternalBehavior/GetEventStatus, operation=EvtInfo_DTC_0x403a13.GetEventStatus
        OpEventGetEventStatus_GetEventStatus_Event_DTC_0x403a13: start-on-event=DemSatellite_0InternalBehavior/GetEventStatus, operation=Event_DTC_0x403a13.GetEventStatus
        OpEventGetEventFailed_GetEventFailed_EvtInfo_DTC_0x403413: start-on-event=DemSatellite_0InternalBehavior/GetEventFailed, operation=EvtInfo_DTC_0x403413.GetEventFailed
        OpEventGetEventFailed_GetEventFailed_Event_DTC_0x403413: start-on-event=DemSatellite_0InternalBehavior/GetEventFailed, operation=Event_DTC_0x403413.GetEventFailed
        OpEventGetEventFailed_GetEventFailed_EvtInfo_DTC_0x404428: start-on-event=DemSatellite_0InternalBehavior/GetEventFailed, operation=EvtInfo_DTC_0x404428.GetEventFailed
        OpEventGetEventFailed_GetEventFailed_Event_DTC_0x404428: start-on-event=DemSatellite_0InternalBehavior/GetEventFailed, operation=Event_DTC_0x404428.GetEventFailed
        OpEventGetEventFailed_GetEventFailed_EvtInfo_DTC_0x406321: start-on-event=DemSatellite_0InternalBehavior/GetEventFailed, operation=EvtInfo_DTC_0x406321.GetEventFailed
        OpEventGetEventFailed_GetEventFailed_Event_DTC_0x406321: start-on-event=DemSatellite_0InternalBehavior/GetEventFailed, operation=Event_DTC_0x406321.GetEventFailed
        OpEventGetEventFailed_GetEventFailed_EvtInfo_DTC_0x406325: start-on-event=DemSatellite_0InternalBehavior/GetEventFailed, operation=EvtInfo_DTC_0x406325.GetEventFailed
        OpEventGetEventFailed_GetEventFailed_Event_DTC_0x406325: start-on-event=DemSatellite_0InternalBehavior/GetEventFailed, operation=Event_DTC_0x406325.GetEventFailed
        OpEventGetEventFailed_GetEventFailed_EvtInfo_DTC_0x404421: start-on-event=DemSatellite_0InternalBehavior/GetEventFailed, operation=EvtInfo_DTC_0x404421.GetEventFailed
        OpEventGetEventFailed_GetEventFailed_Event_DTC_0x404421: start-on-event=DemSatellite_0InternalBehavior/GetEventFailed, operation=Event_DTC_0x404421.GetEventFailed
        OpEventGetEventFailed_GetEventFailed_EvtInfo_DTC_0x404422: start-on-event=DemSatellite_0InternalBehavior/GetEventFailed, operation=EvtInfo_DTC_0x404422.GetEventFailed
        OpEventGetEventFailed_GetEventFailed_Event_DTC_0x404422: start-on-event=DemSatellite_0InternalBehavior/GetEventFailed, operation=Event_DTC_0x404422.GetEventFailed
        OpEventGetEventFailed_GetEventFailed_EvtInfo_DTC_0x406322: start-on-event=DemSatellite_0InternalBehavior/GetEventFailed, operation=EvtInfo_DTC_0x406322.GetEventFailed
        OpEventGetEventFailed_GetEventFailed_Event_DTC_0x406322: start-on-event=DemSatellite_0InternalBehavior/GetEventFailed, operation=Event_DTC_0x406322.GetEventFailed
        OpEventGetEventFailed_GetEventFailed_EvtInfo_DTC_0x403a21: start-on-event=DemSatellite_0InternalBehavior/GetEventFailed, operation=EvtInfo_DTC_0x403a21.GetEventFailed
        OpEventGetEventFailed_GetEventFailed_Event_DTC_0x403a21: start-on-event=DemSatellite_0InternalBehavior/GetEventFailed, operation=Event_DTC_0x403a21.GetEventFailed
        OpEventGetEventFailed_GetEventFailed_EvtInfo_DTC_0x403a22: start-on-event=DemSatellite_0InternalBehavior/GetEventFailed, operation=EvtInfo_DTC_0x403a22.GetEventFailed
        OpEventGetEventFailed_GetEventFailed_Event_DTC_0x403a22: start-on-event=DemSatellite_0InternalBehavior/GetEventFailed, operation=Event_DTC_0x403a22.GetEventFailed
        OpEventGetEventFailed_GetEventFailed_EvtInfo_DTC_0x403422: start-on-event=DemSatellite_0InternalBehavior/GetEventFailed, operation=EvtInfo_DTC_0x403422.GetEventFailed
        OpEventGetEventFailed_GetEventFailed_Event_DTC_0x403422: start-on-event=DemSatellite_0InternalBehavior/GetEventFailed, operation=Event_DTC_0x403422.GetEventFailed
        OpEventGetEventFailed_GetEventFailed_EvtInfo_DTC_0x403421: start-on-event=DemSatellite_0InternalBehavior/GetEventFailed, operation=EvtInfo_DTC_0x403421.GetEventFailed
        OpEventGetEventFailed_GetEventFailed_Event_DTC_0x403421: start-on-event=DemSatellite_0InternalBehavior/GetEventFailed, operation=Event_DTC_0x403421.GetEventFailed
        OpEventGetEventFailed_GetEventFailed_EvtInfo_DTC_0x402013: start-on-event=DemSatellite_0InternalBehavior/GetEventFailed, operation=EvtInfo_DTC_0x402013.GetEventFailed
        OpEventGetEventFailed_GetEventFailed_Event_DTC_0x402013: start-on-event=DemSatellite_0InternalBehavior/GetEventFailed, operation=Event_DTC_0x402013.GetEventFailed
        OpEventGetEventFailed_GetEventFailed_EvtInfo_DTC_0x402012: start-on-event=DemSatellite_0InternalBehavior/GetEventFailed, operation=EvtInfo_DTC_0x402012.GetEventFailed
        OpEventGetEventFailed_GetEventFailed_Event_DTC_0x402012: start-on-event=DemSatellite_0InternalBehavior/GetEventFailed, operation=Event_DTC_0x402012.GetEventFailed
        OpEventGetEventFailed_GetEventFailed_EvtInfo_DTC_0x402025: start-on-event=DemSatellite_0InternalBehavior/GetEventFailed, operation=EvtInfo_DTC_0x402025.GetEventFailed
        OpEventGetEventFailed_GetEventFailed_Event_DTC_0x402025: start-on-event=DemSatellite_0InternalBehavior/GetEventFailed, operation=Event_DTC_0x402025.GetEventFailed
        OpEventGetEventFailed_GetEventFailed_EvtInfo_DTC_0x403713: start-on-event=DemSatellite_0InternalBehavior/GetEventFailed, operation=EvtInfo_DTC_0x403713.GetEventFailed
        OpEventGetEventFailed_GetEventFailed_Event_DTC_0x403713: start-on-event=DemSatellite_0InternalBehavior/GetEventFailed, operation=Event_DTC_0x403713.GetEventFailed
        OpEventGetEventFailed_GetEventFailed_EvtInfo_DTC_0x406222: start-on-event=DemSatellite_0InternalBehavior/GetEventFailed, operation=EvtInfo_DTC_0x406222.GetEventFailed
        OpEventGetEventFailed_GetEventFailed_Event_DTC_0x406222: start-on-event=DemSatellite_0InternalBehavior/GetEventFailed, operation=Event_DTC_0x406222.GetEventFailed
        OpEventGetEventFailed_GetEventFailed_EvtInfo_DTC_0x406221: start-on-event=DemSatellite_0InternalBehavior/GetEventFailed, operation=EvtInfo_DTC_0x406221.GetEventFailed
        OpEventGetEventFailed_GetEventFailed_Event_DTC_0x406221: start-on-event=DemSatellite_0InternalBehavior/GetEventFailed, operation=Event_DTC_0x406221.GetEventFailed
        OpEventGetEventFailed_GetEventFailed_EvtInfo_DTC_0x406225: start-on-event=DemSatellite_0InternalBehavior/GetEventFailed, operation=EvtInfo_DTC_0x406225.GetEventFailed
        OpEventGetEventFailed_GetEventFailed_Event_DTC_0x406225: start-on-event=DemSatellite_0InternalBehavior/GetEventFailed, operation=Event_DTC_0x406225.GetEventFailed
        OpEventGetEventFailed_GetEventFailed_EvtInfo_DTC_0x403113: start-on-event=DemSatellite_0InternalBehavior/GetEventFailed, operation=EvtInfo_DTC_0x403113.GetEventFailed
        OpEventGetEventFailed_GetEventFailed_Event_DTC_0x403113: start-on-event=DemSatellite_0InternalBehavior/GetEventFailed, operation=Event_DTC_0x403113.GetEventFailed
        OpEventGetEventFailed_GetEventFailed_EvtInfo_DTC_0x403721: start-on-event=DemSatellite_0InternalBehavior/GetEventFailed, operation=EvtInfo_DTC_0x403721.GetEventFailed
        OpEventGetEventFailed_GetEventFailed_Event_DTC_0x403721: start-on-event=DemSatellite_0InternalBehavior/GetEventFailed, operation=Event_DTC_0x403721.GetEventFailed
        OpEventGetEventFailed_GetEventFailed_EvtInfo_DTC_0x403722: start-on-event=DemSatellite_0InternalBehavior/GetEventFailed, operation=EvtInfo_DTC_0x403722.GetEventFailed
        OpEventGetEventFailed_GetEventFailed_Event_DTC_0x403722: start-on-event=DemSatellite_0InternalBehavior/GetEventFailed, operation=Event_DTC_0x403722.GetEventFailed
        OpEventGetEventFailed_GetEventFailed_EvtInfo_DTC_0x404011: start-on-event=DemSatellite_0InternalBehavior/GetEventFailed, operation=EvtInfo_DTC_0x404011.GetEventFailed
        OpEventGetEventFailed_GetEventFailed_Event_DTC_0x404011: start-on-event=DemSatellite_0InternalBehavior/GetEventFailed, operation=Event_DTC_0x404011.GetEventFailed
        OpEventGetEventFailed_GetEventFailed_EvtInfo_DTC_0x404212: start-on-event=DemSatellite_0InternalBehavior/GetEventFailed, operation=EvtInfo_DTC_0x404212.GetEventFailed
        OpEventGetEventFailed_GetEventFailed_Event_DTC_0x404212: start-on-event=DemSatellite_0InternalBehavior/GetEventFailed, operation=Event_DTC_0x404212.GetEventFailed
        OpEventGetEventFailed_GetEventFailed_EvtInfo_DTC_0x404213: start-on-event=DemSatellite_0InternalBehavior/GetEventFailed, operation=EvtInfo_DTC_0x404213.GetEventFailed
        OpEventGetEventFailed_GetEventFailed_Event_DTC_0x404213: start-on-event=DemSatellite_0InternalBehavior/GetEventFailed, operation=Event_DTC_0x404213.GetEventFailed
        OpEventGetEventFailed_GetEventFailed_EvtInfo_DTC_0x404012: start-on-event=DemSatellite_0InternalBehavior/GetEventFailed, operation=EvtInfo_DTC_0x404012.GetEventFailed
        OpEventGetEventFailed_GetEventFailed_Event_DTC_0x404012: start-on-event=DemSatellite_0InternalBehavior/GetEventFailed, operation=Event_DTC_0x404012.GetEventFailed
        OpEventGetEventFailed_GetEventFailed_EvtInfo_DTC_0x403121: start-on-event=DemSatellite_0InternalBehavior/GetEventFailed, operation=EvtInfo_DTC_0x403121.GetEventFailed
        OpEventGetEventFailed_GetEventFailed_Event_DTC_0x403121: start-on-event=DemSatellite_0InternalBehavior/GetEventFailed, operation=Event_DTC_0x403121.GetEventFailed
        OpEventGetEventFailed_GetEventFailed_EvtInfo_DTC_0x404211: start-on-event=DemSatellite_0InternalBehavior/GetEventFailed, operation=EvtInfo_DTC_0x404211.GetEventFailed
        OpEventGetEventFailed_GetEventFailed_Event_DTC_0x404211: start-on-event=DemSatellite_0InternalBehavior/GetEventFailed, operation=Event_DTC_0x404211.GetEventFailed
        OpEventGetEventFailed_GetEventFailed_EvtInfo_DTC_0x404013: start-on-event=DemSatellite_0InternalBehavior/GetEventFailed, operation=EvtInfo_DTC_0x404013.GetEventFailed
        OpEventGetEventFailed_GetEventFailed_Event_DTC_0x404013: start-on-event=DemSatellite_0InternalBehavior/GetEventFailed, operation=Event_DTC_0x404013.GetEventFailed
        OpEventGetEventFailed_GetEventFailed_EvtInfo_DTC_0x403122: start-on-event=DemSatellite_0InternalBehavior/GetEventFailed, operation=EvtInfo_DTC_0x403122.GetEventFailed
        OpEventGetEventFailed_GetEventFailed_Event_DTC_0x403122: start-on-event=DemSatellite_0InternalBehavior/GetEventFailed, operation=Event_DTC_0x403122.GetEventFailed
        OpEventGetEventFailed_GetEventFailed_EvtInfo_DTC_0x403a13: start-on-event=DemSatellite_0InternalBehavior/GetEventFailed, operation=EvtInfo_DTC_0x403a13.GetEventFailed
        OpEventGetEventFailed_GetEventFailed_Event_DTC_0x403a13: start-on-event=DemSatellite_0InternalBehavior/GetEventFailed, operation=Event_DTC_0x403a13.GetEventFailed
        OpEventGetEventTested_GetEventTested_EvtInfo_DTC_0x403413: start-on-event=DemSatellite_0InternalBehavior/GetEventTested, operation=EvtInfo_DTC_0x403413.GetEventTested
        OpEventGetEventTested_GetEventTested_Event_DTC_0x403413: start-on-event=DemSatellite_0InternalBehavior/GetEventTested, operation=Event_DTC_0x403413.GetEventTested
        OpEventGetEventTested_GetEventTested_EvtInfo_DTC_0x404428: start-on-event=DemSatellite_0InternalBehavior/GetEventTested, operation=EvtInfo_DTC_0x404428.GetEventTested
        OpEventGetEventTested_GetEventTested_Event_DTC_0x404428: start-on-event=DemSatellite_0InternalBehavior/GetEventTested, operation=Event_DTC_0x404428.GetEventTested
        OpEventGetEventTested_GetEventTested_EvtInfo_DTC_0x406321: start-on-event=DemSatellite_0InternalBehavior/GetEventTested, operation=EvtInfo_DTC_0x406321.GetEventTested
        OpEventGetEventTested_GetEventTested_Event_DTC_0x406321: start-on-event=DemSatellite_0InternalBehavior/GetEventTested, operation=Event_DTC_0x406321.GetEventTested
        OpEventGetEventTested_GetEventTested_EvtInfo_DTC_0x406325: start-on-event=DemSatellite_0InternalBehavior/GetEventTested, operation=EvtInfo_DTC_0x406325.GetEventTested
        OpEventGetEventTested_GetEventTested_Event_DTC_0x406325: start-on-event=DemSatellite_0InternalBehavior/GetEventTested, operation=Event_DTC_0x406325.GetEventTested
        OpEventGetEventTested_GetEventTested_EvtInfo_DTC_0x404421: start-on-event=DemSatellite_0InternalBehavior/GetEventTested, operation=EvtInfo_DTC_0x404421.GetEventTested
        OpEventGetEventTested_GetEventTested_Event_DTC_0x404421: start-on-event=DemSatellite_0InternalBehavior/GetEventTested, operation=Event_DTC_0x404421.GetEventTested
        OpEventGetEventTested_GetEventTested_EvtInfo_DTC_0x404422: start-on-event=DemSatellite_0InternalBehavior/GetEventTested, operation=EvtInfo_DTC_0x404422.GetEventTested
        OpEventGetEventTested_GetEventTested_Event_DTC_0x404422: start-on-event=DemSatellite_0InternalBehavior/GetEventTested, operation=Event_DTC_0x404422.GetEventTested
        OpEventGetEventTested_GetEventTested_EvtInfo_DTC_0x406322: start-on-event=DemSatellite_0InternalBehavior/GetEventTested, operation=EvtInfo_DTC_0x406322.GetEventTested
        OpEventGetEventTested_GetEventTested_Event_DTC_0x406322: start-on-event=DemSatellite_0InternalBehavior/GetEventTested, operation=Event_DTC_0x406322.GetEventTested
        OpEventGetEventTested_GetEventTested_EvtInfo_DTC_0x403a21: start-on-event=DemSatellite_0InternalBehavior/GetEventTested, operation=EvtInfo_DTC_0x403a21.GetEventTested
        OpEventGetEventTested_GetEventTested_Event_DTC_0x403a21: start-on-event=DemSatellite_0InternalBehavior/GetEventTested, operation=Event_DTC_0x403a21.GetEventTested
        OpEventGetEventTested_GetEventTested_EvtInfo_DTC_0x403a22: start-on-event=DemSatellite_0InternalBehavior/GetEventTested, operation=EvtInfo_DTC_0x403a22.GetEventTested
        OpEventGetEventTested_GetEventTested_Event_DTC_0x403a22: start-on-event=DemSatellite_0InternalBehavior/GetEventTested, operation=Event_DTC_0x403a22.GetEventTested
        OpEventGetEventTested_GetEventTested_EvtInfo_DTC_0x403422: start-on-event=DemSatellite_0InternalBehavior/GetEventTested, operation=EvtInfo_DTC_0x403422.GetEventTested
        OpEventGetEventTested_GetEventTested_Event_DTC_0x403422: start-on-event=DemSatellite_0InternalBehavior/GetEventTested, operation=Event_DTC_0x403422.GetEventTested
        OpEventGetEventTested_GetEventTested_EvtInfo_DTC_0x403421: start-on-event=DemSatellite_0InternalBehavior/GetEventTested, operation=EvtInfo_DTC_0x403421.GetEventTested
        OpEventGetEventTested_GetEventTested_Event_DTC_0x403421: start-on-event=DemSatellite_0InternalBehavior/GetEventTested, operation=Event_DTC_0x403421.GetEventTested
        OpEventGetEventTested_GetEventTested_EvtInfo_DTC_0x402013: start-on-event=DemSatellite_0InternalBehavior/GetEventTested, operation=EvtInfo_DTC_0x402013.GetEventTested
        OpEventGetEventTested_GetEventTested_Event_DTC_0x402013: start-on-event=DemSatellite_0InternalBehavior/GetEventTested, operation=Event_DTC_0x402013.GetEventTested
        OpEventGetEventTested_GetEventTested_EvtInfo_DTC_0x402012: start-on-event=DemSatellite_0InternalBehavior/GetEventTested, operation=EvtInfo_DTC_0x402012.GetEventTested
        OpEventGetEventTested_GetEventTested_Event_DTC_0x402012: start-on-event=DemSatellite_0InternalBehavior/GetEventTested, operation=Event_DTC_0x402012.GetEventTested
        OpEventGetEventTested_GetEventTested_EvtInfo_DTC_0x402025: start-on-event=DemSatellite_0InternalBehavior/GetEventTested, operation=EvtInfo_DTC_0x402025.GetEventTested
        OpEventGetEventTested_GetEventTested_Event_DTC_0x402025: start-on-event=DemSatellite_0InternalBehavior/GetEventTested, operation=Event_DTC_0x402025.GetEventTested
        OpEventGetEventTested_GetEventTested_EvtInfo_DTC_0x403713: start-on-event=DemSatellite_0InternalBehavior/GetEventTested, operation=EvtInfo_DTC_0x403713.GetEventTested
        OpEventGetEventTested_GetEventTested_Event_DTC_0x403713: start-on-event=DemSatellite_0InternalBehavior/GetEventTested, operation=Event_DTC_0x403713.GetEventTested
        OpEventGetEventTested_GetEventTested_EvtInfo_DTC_0x406222: start-on-event=DemSatellite_0InternalBehavior/GetEventTested, operation=EvtInfo_DTC_0x406222.GetEventTested
        OpEventGetEventTested_GetEventTested_Event_DTC_0x406222: start-on-event=DemSatellite_0InternalBehavior/GetEventTested, operation=Event_DTC_0x406222.GetEventTested
        OpEventGetEventTested_GetEventTested_EvtInfo_DTC_0x406221: start-on-event=DemSatellite_0InternalBehavior/GetEventTested, operation=EvtInfo_DTC_0x406221.GetEventTested
        OpEventGetEventTested_GetEventTested_Event_DTC_0x406221: start-on-event=DemSatellite_0InternalBehavior/GetEventTested, operation=Event_DTC_0x406221.GetEventTested
        OpEventGetEventTested_GetEventTested_EvtInfo_DTC_0x406225: start-on-event=DemSatellite_0InternalBehavior/GetEventTested, operation=EvtInfo_DTC_0x406225.GetEventTested
        OpEventGetEventTested_GetEventTested_Event_DTC_0x406225: start-on-event=DemSatellite_0InternalBehavior/GetEventTested, operation=Event_DTC_0x406225.GetEventTested
        OpEventGetEventTested_GetEventTested_EvtInfo_DTC_0x403113: start-on-event=DemSatellite_0InternalBehavior/GetEventTested, operation=EvtInfo_DTC_0x403113.GetEventTested
        OpEventGetEventTested_GetEventTested_Event_DTC_0x403113: start-on-event=DemSatellite_0InternalBehavior/GetEventTested, operation=Event_DTC_0x403113.GetEventTested
        OpEventGetEventTested_GetEventTested_EvtInfo_DTC_0x403721: start-on-event=DemSatellite_0InternalBehavior/GetEventTested, operation=EvtInfo_DTC_0x403721.GetEventTested
        OpEventGetEventTested_GetEventTested_Event_DTC_0x403721: start-on-event=DemSatellite_0InternalBehavior/GetEventTested, operation=Event_DTC_0x403721.GetEventTested
        OpEventGetEventTested_GetEventTested_EvtInfo_DTC_0x403722: start-on-event=DemSatellite_0InternalBehavior/GetEventTested, operation=EvtInfo_DTC_0x403722.GetEventTested
        OpEventGetEventTested_GetEventTested_Event_DTC_0x403722: start-on-event=DemSatellite_0InternalBehavior/GetEventTested, operation=Event_DTC_0x403722.GetEventTested
        OpEventGetEventTested_GetEventTested_EvtInfo_DTC_0x404011: start-on-event=DemSatellite_0InternalBehavior/GetEventTested, operation=EvtInfo_DTC_0x404011.GetEventTested
        OpEventGetEventTested_GetEventTested_Event_DTC_0x404011: start-on-event=DemSatellite_0InternalBehavior/GetEventTested, operation=Event_DTC_0x404011.GetEventTested
        OpEventGetEventTested_GetEventTested_EvtInfo_DTC_0x404212: start-on-event=DemSatellite_0InternalBehavior/GetEventTested, operation=EvtInfo_DTC_0x404212.GetEventTested
        OpEventGetEventTested_GetEventTested_Event_DTC_0x404212: start-on-event=DemSatellite_0InternalBehavior/GetEventTested, operation=Event_DTC_0x404212.GetEventTested
        OpEventGetEventTested_GetEventTested_EvtInfo_DTC_0x404213: start-on-event=DemSatellite_0InternalBehavior/GetEventTested, operation=EvtInfo_DTC_0x404213.GetEventTested
        OpEventGetEventTested_GetEventTested_Event_DTC_0x404213: start-on-event=DemSatellite_0InternalBehavior/GetEventTested, operation=Event_DTC_0x404213.GetEventTested
        OpEventGetEventTested_GetEventTested_EvtInfo_DTC_0x404012: start-on-event=DemSatellite_0InternalBehavior/GetEventTested, operation=EvtInfo_DTC_0x404012.GetEventTested
        OpEventGetEventTested_GetEventTested_Event_DTC_0x404012: start-on-event=DemSatellite_0InternalBehavior/GetEventTested, operation=Event_DTC_0x404012.GetEventTested
        OpEventGetEventTested_GetEventTested_EvtInfo_DTC_0x403121: start-on-event=DemSatellite_0InternalBehavior/GetEventTested, operation=EvtInfo_DTC_0x403121.GetEventTested
        OpEventGetEventTested_GetEventTested_Event_DTC_0x403121: start-on-event=DemSatellite_0InternalBehavior/GetEventTested, operation=Event_DTC_0x403121.GetEventTested
        OpEventGetEventTested_GetEventTested_EvtInfo_DTC_0x404211: start-on-event=DemSatellite_0InternalBehavior/GetEventTested, operation=EvtInfo_DTC_0x404211.GetEventTested
        OpEventGetEventTested_GetEventTested_Event_DTC_0x404211: start-on-event=DemSatellite_0InternalBehavior/GetEventTested, operation=Event_DTC_0x404211.GetEventTested
        OpEventGetEventTested_GetEventTested_EvtInfo_DTC_0x404013: start-on-event=DemSatellite_0InternalBehavior/GetEventTested, operation=EvtInfo_DTC_0x404013.GetEventTested
        OpEventGetEventTested_GetEventTested_Event_DTC_0x404013: start-on-event=DemSatellite_0InternalBehavior/GetEventTested, operation=Event_DTC_0x404013.GetEventTested
        OpEventGetEventTested_GetEventTested_EvtInfo_DTC_0x403122: start-on-event=DemSatellite_0InternalBehavior/GetEventTested, operation=EvtInfo_DTC_0x403122.GetEventTested
        OpEventGetEventTested_GetEventTested_Event_DTC_0x403122: start-on-event=DemSatellite_0InternalBehavior/GetEventTested, operation=Event_DTC_0x403122.GetEventTested
        OpEventGetEventTested_GetEventTested_EvtInfo_DTC_0x403a13: start-on-event=DemSatellite_0InternalBehavior/GetEventTested, operation=EvtInfo_DTC_0x403a13.GetEventTested
        OpEventGetEventTested_GetEventTested_Event_DTC_0x403a13: start-on-event=DemSatellite_0InternalBehavior/GetEventTested, operation=Event_DTC_0x403a13.GetEventTested
        OpEventGetDTCOfEvent_GetDTCOfEvent_EvtInfo_DTC_0x403413: start-on-event=DemSatellite_0InternalBehavior/GetDTCOfEvent, operation=EvtInfo_DTC_0x403413.GetDTCOfEvent
        OpEventGetDTCOfEvent_GetDTCOfEvent_Event_DTC_0x403413: start-on-event=DemSatellite_0InternalBehavior/GetDTCOfEvent, operation=Event_DTC_0x403413.GetDTCOfEvent
        OpEventGetDTCOfEvent_GetDTCOfEvent_EvtInfo_DTC_0x404428: start-on-event=DemSatellite_0InternalBehavior/GetDTCOfEvent, operation=EvtInfo_DTC_0x404428.GetDTCOfEvent
        OpEventGetDTCOfEvent_GetDTCOfEvent_Event_DTC_0x404428: start-on-event=DemSatellite_0InternalBehavior/GetDTCOfEvent, operation=Event_DTC_0x404428.GetDTCOfEvent
        OpEventGetDTCOfEvent_GetDTCOfEvent_EvtInfo_DTC_0x406321: start-on-event=DemSatellite_0InternalBehavior/GetDTCOfEvent, operation=EvtInfo_DTC_0x406321.GetDTCOfEvent
        OpEventGetDTCOfEvent_GetDTCOfEvent_Event_DTC_0x406321: start-on-event=DemSatellite_0InternalBehavior/GetDTCOfEvent, operation=Event_DTC_0x406321.GetDTCOfEvent
        OpEventGetDTCOfEvent_GetDTCOfEvent_EvtInfo_DTC_0x406325: start-on-event=DemSatellite_0InternalBehavior/GetDTCOfEvent, operation=EvtInfo_DTC_0x406325.GetDTCOfEvent
        OpEventGetDTCOfEvent_GetDTCOfEvent_Event_DTC_0x406325: start-on-event=DemSatellite_0InternalBehavior/GetDTCOfEvent, operation=Event_DTC_0x406325.GetDTCOfEvent
        OpEventGetDTCOfEvent_GetDTCOfEvent_EvtInfo_DTC_0x404421: start-on-event=DemSatellite_0InternalBehavior/GetDTCOfEvent, operation=EvtInfo_DTC_0x404421.GetDTCOfEvent
        OpEventGetDTCOfEvent_GetDTCOfEvent_Event_DTC_0x404421: start-on-event=DemSatellite_0InternalBehavior/GetDTCOfEvent, operation=Event_DTC_0x404421.GetDTCOfEvent
        OpEventGetDTCOfEvent_GetDTCOfEvent_EvtInfo_DTC_0x404422: start-on-event=DemSatellite_0InternalBehavior/GetDTCOfEvent, operation=EvtInfo_DTC_0x404422.GetDTCOfEvent
        OpEventGetDTCOfEvent_GetDTCOfEvent_Event_DTC_0x404422: start-on-event=DemSatellite_0InternalBehavior/GetDTCOfEvent, operation=Event_DTC_0x404422.GetDTCOfEvent
        OpEventGetDTCOfEvent_GetDTCOfEvent_EvtInfo_DTC_0x406322: start-on-event=DemSatellite_0InternalBehavior/GetDTCOfEvent, operation=EvtInfo_DTC_0x406322.GetDTCOfEvent
        OpEventGetDTCOfEvent_GetDTCOfEvent_Event_DTC_0x406322: start-on-event=DemSatellite_0InternalBehavior/GetDTCOfEvent, operation=Event_DTC_0x406322.GetDTCOfEvent
        OpEventGetDTCOfEvent_GetDTCOfEvent_EvtInfo_DTC_0x403a21: start-on-event=DemSatellite_0InternalBehavior/GetDTCOfEvent, operation=EvtInfo_DTC_0x403a21.GetDTCOfEvent
        OpEventGetDTCOfEvent_GetDTCOfEvent_Event_DTC_0x403a21: start-on-event=DemSatellite_0InternalBehavior/GetDTCOfEvent, operation=Event_DTC_0x403a21.GetDTCOfEvent
        OpEventGetDTCOfEvent_GetDTCOfEvent_EvtInfo_DTC_0x403a22: start-on-event=DemSatellite_0InternalBehavior/GetDTCOfEvent, operation=EvtInfo_DTC_0x403a22.GetDTCOfEvent
        OpEventGetDTCOfEvent_GetDTCOfEvent_Event_DTC_0x403a22: start-on-event=DemSatellite_0InternalBehavior/GetDTCOfEvent, operation=Event_DTC_0x403a22.GetDTCOfEvent
        OpEventGetDTCOfEvent_GetDTCOfEvent_EvtInfo_DTC_0x403422: start-on-event=DemSatellite_0InternalBehavior/GetDTCOfEvent, operation=EvtInfo_DTC_0x403422.GetDTCOfEvent
        OpEventGetDTCOfEvent_GetDTCOfEvent_Event_DTC_0x403422: start-on-event=DemSatellite_0InternalBehavior/GetDTCOfEvent, operation=Event_DTC_0x403422.GetDTCOfEvent
        OpEventGetDTCOfEvent_GetDTCOfEvent_EvtInfo_DTC_0x403421: start-on-event=DemSatellite_0InternalBehavior/GetDTCOfEvent, operation=EvtInfo_DTC_0x403421.GetDTCOfEvent
        OpEventGetDTCOfEvent_GetDTCOfEvent_Event_DTC_0x403421: start-on-event=DemSatellite_0InternalBehavior/GetDTCOfEvent, operation=Event_DTC_0x403421.GetDTCOfEvent
        OpEventGetDTCOfEvent_GetDTCOfEvent_EvtInfo_DTC_0x402013: start-on-event=DemSatellite_0InternalBehavior/GetDTCOfEvent, operation=EvtInfo_DTC_0x402013.GetDTCOfEvent
        OpEventGetDTCOfEvent_GetDTCOfEvent_Event_DTC_0x402013: start-on-event=DemSatellite_0InternalBehavior/GetDTCOfEvent, operation=Event_DTC_0x402013.GetDTCOfEvent
        OpEventGetDTCOfEvent_GetDTCOfEvent_EvtInfo_DTC_0x402012: start-on-event=DemSatellite_0InternalBehavior/GetDTCOfEvent, operation=EvtInfo_DTC_0x402012.GetDTCOfEvent
        OpEventGetDTCOfEvent_GetDTCOfEvent_Event_DTC_0x402012: start-on-event=DemSatellite_0InternalBehavior/GetDTCOfEvent, operation=Event_DTC_0x402012.GetDTCOfEvent
        OpEventGetDTCOfEvent_GetDTCOfEvent_EvtInfo_DTC_0x402025: start-on-event=DemSatellite_0InternalBehavior/GetDTCOfEvent, operation=EvtInfo_DTC_0x402025.GetDTCOfEvent
        OpEventGetDTCOfEvent_GetDTCOfEvent_Event_DTC_0x402025: start-on-event=DemSatellite_0InternalBehavior/GetDTCOfEvent, operation=Event_DTC_0x402025.GetDTCOfEvent
        OpEventGetDTCOfEvent_GetDTCOfEvent_EvtInfo_DTC_0x403713: start-on-event=DemSatellite_0InternalBehavior/GetDTCOfEvent, operation=EvtInfo_DTC_0x403713.GetDTCOfEvent
        OpEventGetDTCOfEvent_GetDTCOfEvent_Event_DTC_0x403713: start-on-event=DemSatellite_0InternalBehavior/GetDTCOfEvent, operation=Event_DTC_0x403713.GetDTCOfEvent
        OpEventGetDTCOfEvent_GetDTCOfEvent_EvtInfo_DTC_0x406222: start-on-event=DemSatellite_0InternalBehavior/GetDTCOfEvent, operation=EvtInfo_DTC_0x406222.GetDTCOfEvent
        OpEventGetDTCOfEvent_GetDTCOfEvent_Event_DTC_0x406222: start-on-event=DemSatellite_0InternalBehavior/GetDTCOfEvent, operation=Event_DTC_0x406222.GetDTCOfEvent
        OpEventGetDTCOfEvent_GetDTCOfEvent_EvtInfo_DTC_0x406221: start-on-event=DemSatellite_0InternalBehavior/GetDTCOfEvent, operation=EvtInfo_DTC_0x406221.GetDTCOfEvent
        OpEventGetDTCOfEvent_GetDTCOfEvent_Event_DTC_0x406221: start-on-event=DemSatellite_0InternalBehavior/GetDTCOfEvent, operation=Event_DTC_0x406221.GetDTCOfEvent
        OpEventGetDTCOfEvent_GetDTCOfEvent_EvtInfo_DTC_0x406225: start-on-event=DemSatellite_0InternalBehavior/GetDTCOfEvent, operation=EvtInfo_DTC_0x406225.GetDTCOfEvent
        OpEventGetDTCOfEvent_GetDTCOfEvent_Event_DTC_0x406225: start-on-event=DemSatellite_0InternalBehavior/GetDTCOfEvent, operation=Event_DTC_0x406225.GetDTCOfEvent
        OpEventGetDTCOfEvent_GetDTCOfEvent_EvtInfo_DTC_0x403113: start-on-event=DemSatellite_0InternalBehavior/GetDTCOfEvent, operation=EvtInfo_DTC_0x403113.GetDTCOfEvent
        OpEventGetDTCOfEvent_GetDTCOfEvent_Event_DTC_0x403113: start-on-event=DemSatellite_0InternalBehavior/GetDTCOfEvent, operation=Event_DTC_0x403113.GetDTCOfEvent
        OpEventGetDTCOfEvent_GetDTCOfEvent_EvtInfo_DTC_0x403721: start-on-event=DemSatellite_0InternalBehavior/GetDTCOfEvent, operation=EvtInfo_DTC_0x403721.GetDTCOfEvent
        OpEventGetDTCOfEvent_GetDTCOfEvent_Event_DTC_0x403721: start-on-event=DemSatellite_0InternalBehavior/GetDTCOfEvent, operation=Event_DTC_0x403721.GetDTCOfEvent
        OpEventGetDTCOfEvent_GetDTCOfEvent_EvtInfo_DTC_0x403722: start-on-event=DemSatellite_0InternalBehavior/GetDTCOfEvent, operation=EvtInfo_DTC_0x403722.GetDTCOfEvent
        OpEventGetDTCOfEvent_GetDTCOfEvent_Event_DTC_0x403722: start-on-event=DemSatellite_0InternalBehavior/GetDTCOfEvent, operation=Event_DTC_0x403722.GetDTCOfEvent
        OpEventGetDTCOfEvent_GetDTCOfEvent_EvtInfo_DTC_0x404011: start-on-event=DemSatellite_0InternalBehavior/GetDTCOfEvent, operation=EvtInfo_DTC_0x404011.GetDTCOfEvent
        OpEventGetDTCOfEvent_GetDTCOfEvent_Event_DTC_0x404011: start-on-event=DemSatellite_0InternalBehavior/GetDTCOfEvent, operation=Event_DTC_0x404011.GetDTCOfEvent
        OpEventGetDTCOfEvent_GetDTCOfEvent_EvtInfo_DTC_0x404212: start-on-event=DemSatellite_0InternalBehavior/GetDTCOfEvent, operation=EvtInfo_DTC_0x404212.GetDTCOfEvent
        OpEventGetDTCOfEvent_GetDTCOfEvent_Event_DTC_0x404212: start-on-event=DemSatellite_0InternalBehavior/GetDTCOfEvent, operation=Event_DTC_0x404212.GetDTCOfEvent
        OpEventGetDTCOfEvent_GetDTCOfEvent_EvtInfo_DTC_0x404213: start-on-event=DemSatellite_0InternalBehavior/GetDTCOfEvent, operation=EvtInfo_DTC_0x404213.GetDTCOfEvent
        OpEventGetDTCOfEvent_GetDTCOfEvent_Event_DTC_0x404213: start-on-event=DemSatellite_0InternalBehavior/GetDTCOfEvent, operation=Event_DTC_0x404213.GetDTCOfEvent
        OpEventGetDTCOfEvent_GetDTCOfEvent_EvtInfo_DTC_0x404012: start-on-event=DemSatellite_0InternalBehavior/GetDTCOfEvent, operation=EvtInfo_DTC_0x404012.GetDTCOfEvent
        OpEventGetDTCOfEvent_GetDTCOfEvent_Event_DTC_0x404012: start-on-event=DemSatellite_0InternalBehavior/GetDTCOfEvent, operation=Event_DTC_0x404012.GetDTCOfEvent
        OpEventGetDTCOfEvent_GetDTCOfEvent_EvtInfo_DTC_0x403121: start-on-event=DemSatellite_0InternalBehavior/GetDTCOfEvent, operation=EvtInfo_DTC_0x403121.GetDTCOfEvent
        OpEventGetDTCOfEvent_GetDTCOfEvent_Event_DTC_0x403121: start-on-event=DemSatellite_0InternalBehavior/GetDTCOfEvent, operation=Event_DTC_0x403121.GetDTCOfEvent
        OpEventGetDTCOfEvent_GetDTCOfEvent_EvtInfo_DTC_0x404211: start-on-event=DemSatellite_0InternalBehavior/GetDTCOfEvent, operation=EvtInfo_DTC_0x404211.GetDTCOfEvent
        OpEventGetDTCOfEvent_GetDTCOfEvent_Event_DTC_0x404211: start-on-event=DemSatellite_0InternalBehavior/GetDTCOfEvent, operation=Event_DTC_0x404211.GetDTCOfEvent
        OpEventGetDTCOfEvent_GetDTCOfEvent_EvtInfo_DTC_0x404013: start-on-event=DemSatellite_0InternalBehavior/GetDTCOfEvent, operation=EvtInfo_DTC_0x404013.GetDTCOfEvent
        OpEventGetDTCOfEvent_GetDTCOfEvent_Event_DTC_0x404013: start-on-event=DemSatellite_0InternalBehavior/GetDTCOfEvent, operation=Event_DTC_0x404013.GetDTCOfEvent
        OpEventGetDTCOfEvent_GetDTCOfEvent_EvtInfo_DTC_0x403122: start-on-event=DemSatellite_0InternalBehavior/GetDTCOfEvent, operation=EvtInfo_DTC_0x403122.GetDTCOfEvent
        OpEventGetDTCOfEvent_GetDTCOfEvent_Event_DTC_0x403122: start-on-event=DemSatellite_0InternalBehavior/GetDTCOfEvent, operation=Event_DTC_0x403122.GetDTCOfEvent
        OpEventGetDTCOfEvent_GetDTCOfEvent_EvtInfo_DTC_0x403a13: start-on-event=DemSatellite_0InternalBehavior/GetDTCOfEvent, operation=EvtInfo_DTC_0x403a13.GetDTCOfEvent
        OpEventGetDTCOfEvent_GetDTCOfEvent_Event_DTC_0x403a13: start-on-event=DemSatellite_0InternalBehavior/GetDTCOfEvent, operation=Event_DTC_0x403a13.GetDTCOfEvent
        OpEventGetFaultDetectionCounter_GetFaultDetectionCounter_EvtInfo_DTC_0x403413: start-on-event=DemSatellite_0InternalBehavior/GetFaultDetectionCounter, operation=EvtInfo_DTC_0x403413.GetFaultDetectionCounter
        OpEventGetFaultDetectionCounter_GetFaultDetectionCounter_Event_DTC_0x403413: start-on-event=DemSatellite_0InternalBehavior/GetFaultDetectionCounter, operation=Event_DTC_0x403413.GetFaultDetectionCounter
        OpEventGetFaultDetectionCounter_GetFaultDetectionCounter_EvtInfo_DTC_0x404428: start-on-event=DemSatellite_0InternalBehavior/GetFaultDetectionCounter, operation=EvtInfo_DTC_0x404428.GetFaultDetectionCounter
        OpEventGetFaultDetectionCounter_GetFaultDetectionCounter_Event_DTC_0x404428: start-on-event=DemSatellite_0InternalBehavior/GetFaultDetectionCounter, operation=Event_DTC_0x404428.GetFaultDetectionCounter
        OpEventGetFaultDetectionCounter_GetFaultDetectionCounter_EvtInfo_DTC_0x406321: start-on-event=DemSatellite_0InternalBehavior/GetFaultDetectionCounter, operation=EvtInfo_DTC_0x406321.GetFaultDetectionCounter
        OpEventGetFaultDetectionCounter_GetFaultDetectionCounter_Event_DTC_0x406321: start-on-event=DemSatellite_0InternalBehavior/GetFaultDetectionCounter, operation=Event_DTC_0x406321.GetFaultDetectionCounter
        OpEventGetFaultDetectionCounter_GetFaultDetectionCounter_EvtInfo_DTC_0x406325: start-on-event=DemSatellite_0InternalBehavior/GetFaultDetectionCounter, operation=EvtInfo_DTC_0x406325.GetFaultDetectionCounter
        OpEventGetFaultDetectionCounter_GetFaultDetectionCounter_Event_DTC_0x406325: start-on-event=DemSatellite_0InternalBehavior/GetFaultDetectionCounter, operation=Event_DTC_0x406325.GetFaultDetectionCounter
        OpEventGetFaultDetectionCounter_GetFaultDetectionCounter_EvtInfo_DTC_0x404421: start-on-event=DemSatellite_0InternalBehavior/GetFaultDetectionCounter, operation=EvtInfo_DTC_0x404421.GetFaultDetectionCounter
        OpEventGetFaultDetectionCounter_GetFaultDetectionCounter_Event_DTC_0x404421: start-on-event=DemSatellite_0InternalBehavior/GetFaultDetectionCounter, operation=Event_DTC_0x404421.GetFaultDetectionCounter
        OpEventGetFaultDetectionCounter_GetFaultDetectionCounter_EvtInfo_DTC_0x404422: start-on-event=DemSatellite_0InternalBehavior/GetFaultDetectionCounter, operation=EvtInfo_DTC_0x404422.GetFaultDetectionCounter
        OpEventGetFaultDetectionCounter_GetFaultDetectionCounter_Event_DTC_0x404422: start-on-event=DemSatellite_0InternalBehavior/GetFaultDetectionCounter, operation=Event_DTC_0x404422.GetFaultDetectionCounter
        OpEventGetFaultDetectionCounter_GetFaultDetectionCounter_EvtInfo_DTC_0x406322: start-on-event=DemSatellite_0InternalBehavior/GetFaultDetectionCounter, operation=EvtInfo_DTC_0x406322.GetFaultDetectionCounter
        OpEventGetFaultDetectionCounter_GetFaultDetectionCounter_Event_DTC_0x406322: start-on-event=DemSatellite_0InternalBehavior/GetFaultDetectionCounter, operation=Event_DTC_0x406322.GetFaultDetectionCounter
        OpEventGetFaultDetectionCounter_GetFaultDetectionCounter_EvtInfo_DTC_0x403a21: start-on-event=DemSatellite_0InternalBehavior/GetFaultDetectionCounter, operation=EvtInfo_DTC_0x403a21.GetFaultDetectionCounter
        OpEventGetFaultDetectionCounter_GetFaultDetectionCounter_Event_DTC_0x403a21: start-on-event=DemSatellite_0InternalBehavior/GetFaultDetectionCounter, operation=Event_DTC_0x403a21.GetFaultDetectionCounter
        OpEventGetFaultDetectionCounter_GetFaultDetectionCounter_EvtInfo_DTC_0x403a22: start-on-event=DemSatellite_0InternalBehavior/GetFaultDetectionCounter, operation=EvtInfo_DTC_0x403a22.GetFaultDetectionCounter
        OpEventGetFaultDetectionCounter_GetFaultDetectionCounter_Event_DTC_0x403a22: start-on-event=DemSatellite_0InternalBehavior/GetFaultDetectionCounter, operation=Event_DTC_0x403a22.GetFaultDetectionCounter
        OpEventGetFaultDetectionCounter_GetFaultDetectionCounter_EvtInfo_DTC_0x403422: start-on-event=DemSatellite_0InternalBehavior/GetFaultDetectionCounter, operation=EvtInfo_DTC_0x403422.GetFaultDetectionCounter
        OpEventGetFaultDetectionCounter_GetFaultDetectionCounter_Event_DTC_0x403422: start-on-event=DemSatellite_0InternalBehavior/GetFaultDetectionCounter, operation=Event_DTC_0x403422.GetFaultDetectionCounter
        OpEventGetFaultDetectionCounter_GetFaultDetectionCounter_EvtInfo_DTC_0x403421: start-on-event=DemSatellite_0InternalBehavior/GetFaultDetectionCounter, operation=EvtInfo_DTC_0x403421.GetFaultDetectionCounter
        OpEventGetFaultDetectionCounter_GetFaultDetectionCounter_Event_DTC_0x403421: start-on-event=DemSatellite_0InternalBehavior/GetFaultDetectionCounter, operation=Event_DTC_0x403421.GetFaultDetectionCounter
        OpEventGetFaultDetectionCounter_GetFaultDetectionCounter_EvtInfo_DTC_0x402013: start-on-event=DemSatellite_0InternalBehavior/GetFaultDetectionCounter, operation=EvtInfo_DTC_0x402013.GetFaultDetectionCounter
        OpEventGetFaultDetectionCounter_GetFaultDetectionCounter_Event_DTC_0x402013: start-on-event=DemSatellite_0InternalBehavior/GetFaultDetectionCounter, operation=Event_DTC_0x402013.GetFaultDetectionCounter
        OpEventGetFaultDetectionCounter_GetFaultDetectionCounter_EvtInfo_DTC_0x402012: start-on-event=DemSatellite_0InternalBehavior/GetFaultDetectionCounter, operation=EvtInfo_DTC_0x402012.GetFaultDetectionCounter
        OpEventGetFaultDetectionCounter_GetFaultDetectionCounter_Event_DTC_0x402012: start-on-event=DemSatellite_0InternalBehavior/GetFaultDetectionCounter, operation=Event_DTC_0x402012.GetFaultDetectionCounter
        OpEventGetFaultDetectionCounter_GetFaultDetectionCounter_EvtInfo_DTC_0x402025: start-on-event=DemSatellite_0InternalBehavior/GetFaultDetectionCounter, operation=EvtInfo_DTC_0x402025.GetFaultDetectionCounter
        OpEventGetFaultDetectionCounter_GetFaultDetectionCounter_Event_DTC_0x402025: start-on-event=DemSatellite_0InternalBehavior/GetFaultDetectionCounter, operation=Event_DTC_0x402025.GetFaultDetectionCounter
        OpEventGetFaultDetectionCounter_GetFaultDetectionCounter_EvtInfo_DTC_0x403713: start-on-event=DemSatellite_0InternalBehavior/GetFaultDetectionCounter, operation=EvtInfo_DTC_0x403713.GetFaultDetectionCounter
        OpEventGetFaultDetectionCounter_GetFaultDetectionCounter_Event_DTC_0x403713: start-on-event=DemSatellite_0InternalBehavior/GetFaultDetectionCounter, operation=Event_DTC_0x403713.GetFaultDetectionCounter
        OpEventGetFaultDetectionCounter_GetFaultDetectionCounter_EvtInfo_DTC_0x406222: start-on-event=DemSatellite_0InternalBehavior/GetFaultDetectionCounter, operation=EvtInfo_DTC_0x406222.GetFaultDetectionCounter
        OpEventGetFaultDetectionCounter_GetFaultDetectionCounter_Event_DTC_0x406222: start-on-event=DemSatellite_0InternalBehavior/GetFaultDetectionCounter, operation=Event_DTC_0x406222.GetFaultDetectionCounter
        OpEventGetFaultDetectionCounter_GetFaultDetectionCounter_EvtInfo_DTC_0x406221: start-on-event=DemSatellite_0InternalBehavior/GetFaultDetectionCounter, operation=EvtInfo_DTC_0x406221.GetFaultDetectionCounter
        OpEventGetFaultDetectionCounter_GetFaultDetectionCounter_Event_DTC_0x406221: start-on-event=DemSatellite_0InternalBehavior/GetFaultDetectionCounter, operation=Event_DTC_0x406221.GetFaultDetectionCounter
        OpEventGetFaultDetectionCounter_GetFaultDetectionCounter_EvtInfo_DTC_0x406225: start-on-event=DemSatellite_0InternalBehavior/GetFaultDetectionCounter, operation=EvtInfo_DTC_0x406225.GetFaultDetectionCounter
        OpEventGetFaultDetectionCounter_GetFaultDetectionCounter_Event_DTC_0x406225: start-on-event=DemSatellite_0InternalBehavior/GetFaultDetectionCounter, operation=Event_DTC_0x406225.GetFaultDetectionCounter
        OpEventGetFaultDetectionCounter_GetFaultDetectionCounter_EvtInfo_DTC_0x403113: start-on-event=DemSatellite_0InternalBehavior/GetFaultDetectionCounter, operation=EvtInfo_DTC_0x403113.GetFaultDetectionCounter
        OpEventGetFaultDetectionCounter_GetFaultDetectionCounter_Event_DTC_0x403113: start-on-event=DemSatellite_0InternalBehavior/GetFaultDetectionCounter, operation=Event_DTC_0x403113.GetFaultDetectionCounter
        OpEventGetFaultDetectionCounter_GetFaultDetectionCounter_EvtInfo_DTC_0x403721: start-on-event=DemSatellite_0InternalBehavior/GetFaultDetectionCounter, operation=EvtInfo_DTC_0x403721.GetFaultDetectionCounter
        OpEventGetFaultDetectionCounter_GetFaultDetectionCounter_Event_DTC_0x403721: start-on-event=DemSatellite_0InternalBehavior/GetFaultDetectionCounter, operation=Event_DTC_0x403721.GetFaultDetectionCounter
        OpEventGetFaultDetectionCounter_GetFaultDetectionCounter_EvtInfo_DTC_0x403722: start-on-event=DemSatellite_0InternalBehavior/GetFaultDetectionCounter, operation=EvtInfo_DTC_0x403722.GetFaultDetectionCounter
        OpEventGetFaultDetectionCounter_GetFaultDetectionCounter_Event_DTC_0x403722: start-on-event=DemSatellite_0InternalBehavior/GetFaultDetectionCounter, operation=Event_DTC_0x403722.GetFaultDetectionCounter
        OpEventGetFaultDetectionCounter_GetFaultDetectionCounter_EvtInfo_DTC_0x404011: start-on-event=DemSatellite_0InternalBehavior/GetFaultDetectionCounter, operation=EvtInfo_DTC_0x404011.GetFaultDetectionCounter
        OpEventGetFaultDetectionCounter_GetFaultDetectionCounter_Event_DTC_0x404011: start-on-event=DemSatellite_0InternalBehavior/GetFaultDetectionCounter, operation=Event_DTC_0x404011.GetFaultDetectionCounter
        OpEventGetFaultDetectionCounter_GetFaultDetectionCounter_EvtInfo_DTC_0x404212: start-on-event=DemSatellite_0InternalBehavior/GetFaultDetectionCounter, operation=EvtInfo_DTC_0x404212.GetFaultDetectionCounter
        OpEventGetFaultDetectionCounter_GetFaultDetectionCounter_Event_DTC_0x404212: start-on-event=DemSatellite_0InternalBehavior/GetFaultDetectionCounter, operation=Event_DTC_0x404212.GetFaultDetectionCounter
        OpEventGetFaultDetectionCounter_GetFaultDetectionCounter_EvtInfo_DTC_0x404213: start-on-event=DemSatellite_0InternalBehavior/GetFaultDetectionCounter, operation=EvtInfo_DTC_0x404213.GetFaultDetectionCounter
        OpEventGetFaultDetectionCounter_GetFaultDetectionCounter_Event_DTC_0x404213: start-on-event=DemSatellite_0InternalBehavior/GetFaultDetectionCounter, operation=Event_DTC_0x404213.GetFaultDetectionCounter
        OpEventGetFaultDetectionCounter_GetFaultDetectionCounter_EvtInfo_DTC_0x404012: start-on-event=DemSatellite_0InternalBehavior/GetFaultDetectionCounter, operation=EvtInfo_DTC_0x404012.GetFaultDetectionCounter
        OpEventGetFaultDetectionCounter_GetFaultDetectionCounter_Event_DTC_0x404012: start-on-event=DemSatellite_0InternalBehavior/GetFaultDetectionCounter, operation=Event_DTC_0x404012.GetFaultDetectionCounter
        OpEventGetFaultDetectionCounter_GetFaultDetectionCounter_EvtInfo_DTC_0x403121: start-on-event=DemSatellite_0InternalBehavior/GetFaultDetectionCounter, operation=EvtInfo_DTC_0x403121.GetFaultDetectionCounter
        OpEventGetFaultDetectionCounter_GetFaultDetectionCounter_Event_DTC_0x403121: start-on-event=DemSatellite_0InternalBehavior/GetFaultDetectionCounter, operation=Event_DTC_0x403121.GetFaultDetectionCounter
        OpEventGetFaultDetectionCounter_GetFaultDetectionCounter_EvtInfo_DTC_0x404211: start-on-event=DemSatellite_0InternalBehavior/GetFaultDetectionCounter, operation=EvtInfo_DTC_0x404211.GetFaultDetectionCounter
        OpEventGetFaultDetectionCounter_GetFaultDetectionCounter_Event_DTC_0x404211: start-on-event=DemSatellite_0InternalBehavior/GetFaultDetectionCounter, operation=Event_DTC_0x404211.GetFaultDetectionCounter
        OpEventGetFaultDetectionCounter_GetFaultDetectionCounter_EvtInfo_DTC_0x404013: start-on-event=DemSatellite_0InternalBehavior/GetFaultDetectionCounter, operation=EvtInfo_DTC_0x404013.GetFaultDetectionCounter
        OpEventGetFaultDetectionCounter_GetFaultDetectionCounter_Event_DTC_0x404013: start-on-event=DemSatellite_0InternalBehavior/GetFaultDetectionCounter, operation=Event_DTC_0x404013.GetFaultDetectionCounter
        OpEventGetFaultDetectionCounter_GetFaultDetectionCounter_EvtInfo_DTC_0x403122: start-on-event=DemSatellite_0InternalBehavior/GetFaultDetectionCounter, operation=EvtInfo_DTC_0x403122.GetFaultDetectionCounter
        OpEventGetFaultDetectionCounter_GetFaultDetectionCounter_Event_DTC_0x403122: start-on-event=DemSatellite_0InternalBehavior/GetFaultDetectionCounter, operation=Event_DTC_0x403122.GetFaultDetectionCounter
        OpEventGetFaultDetectionCounter_GetFaultDetectionCounter_EvtInfo_DTC_0x403a13: start-on-event=DemSatellite_0InternalBehavior/GetFaultDetectionCounter, operation=EvtInfo_DTC_0x403a13.GetFaultDetectionCounter
        OpEventGetFaultDetectionCounter_GetFaultDetectionCounter_Event_DTC_0x403a13: start-on-event=DemSatellite_0InternalBehavior/GetFaultDetectionCounter, operation=Event_DTC_0x403a13.GetFaultDetectionCounter
        OpEventGetEventFreezeFrameDataEx_GetEventFreezeFrameDataEx_EvtInfo_DTC_0x403413: start-on-event=DemSatellite_0InternalBehavior/GetEventFreezeFrameDataEx, operation=EvtInfo_DTC_0x403413.GetEventFreezeFrameDataEx
        OpEventGetEventFreezeFrameDataEx_GetEventFreezeFrameDataEx_Event_DTC_0x403413: start-on-event=DemSatellite_0InternalBehavior/GetEventFreezeFrameDataEx, operation=Event_DTC_0x403413.GetEventFreezeFrameDataEx
        OpEventGetEventFreezeFrameDataEx_GetEventFreezeFrameDataEx_EvtInfo_DTC_0x404428: start-on-event=DemSatellite_0InternalBehavior/GetEventFreezeFrameDataEx, operation=EvtInfo_DTC_0x404428.GetEventFreezeFrameDataEx
        OpEventGetEventFreezeFrameDataEx_GetEventFreezeFrameDataEx_Event_DTC_0x404428: start-on-event=DemSatellite_0InternalBehavior/GetEventFreezeFrameDataEx, operation=Event_DTC_0x404428.GetEventFreezeFrameDataEx
        OpEventGetEventFreezeFrameDataEx_GetEventFreezeFrameDataEx_EvtInfo_DTC_0x406321: start-on-event=DemSatellite_0InternalBehavior/GetEventFreezeFrameDataEx, operation=EvtInfo_DTC_0x406321.GetEventFreezeFrameDataEx
        OpEventGetEventFreezeFrameDataEx_GetEventFreezeFrameDataEx_Event_DTC_0x406321: start-on-event=DemSatellite_0InternalBehavior/GetEventFreezeFrameDataEx, operation=Event_DTC_0x406321.GetEventFreezeFrameDataEx
        OpEventGetEventFreezeFrameDataEx_GetEventFreezeFrameDataEx_EvtInfo_DTC_0x406325: start-on-event=DemSatellite_0InternalBehavior/GetEventFreezeFrameDataEx, operation=EvtInfo_DTC_0x406325.GetEventFreezeFrameDataEx
        OpEventGetEventFreezeFrameDataEx_GetEventFreezeFrameDataEx_Event_DTC_0x406325: start-on-event=DemSatellite_0InternalBehavior/GetEventFreezeFrameDataEx, operation=Event_DTC_0x406325.GetEventFreezeFrameDataEx
        OpEventGetEventFreezeFrameDataEx_GetEventFreezeFrameDataEx_EvtInfo_DTC_0x404421: start-on-event=DemSatellite_0InternalBehavior/GetEventFreezeFrameDataEx, operation=EvtInfo_DTC_0x404421.GetEventFreezeFrameDataEx
        OpEventGetEventFreezeFrameDataEx_GetEventFreezeFrameDataEx_Event_DTC_0x404421: start-on-event=DemSatellite_0InternalBehavior/GetEventFreezeFrameDataEx, operation=Event_DTC_0x404421.GetEventFreezeFrameDataEx
        OpEventGetEventFreezeFrameDataEx_GetEventFreezeFrameDataEx_EvtInfo_DTC_0x404422: start-on-event=DemSatellite_0InternalBehavior/GetEventFreezeFrameDataEx, operation=EvtInfo_DTC_0x404422.GetEventFreezeFrameDataEx
        OpEventGetEventFreezeFrameDataEx_GetEventFreezeFrameDataEx_Event_DTC_0x404422: start-on-event=DemSatellite_0InternalBehavior/GetEventFreezeFrameDataEx, operation=Event_DTC_0x404422.GetEventFreezeFrameDataEx
        OpEventGetEventFreezeFrameDataEx_GetEventFreezeFrameDataEx_EvtInfo_DTC_0x406322: start-on-event=DemSatellite_0InternalBehavior/GetEventFreezeFrameDataEx, operation=EvtInfo_DTC_0x406322.GetEventFreezeFrameDataEx
        OpEventGetEventFreezeFrameDataEx_GetEventFreezeFrameDataEx_Event_DTC_0x406322: start-on-event=DemSatellite_0InternalBehavior/GetEventFreezeFrameDataEx, operation=Event_DTC_0x406322.GetEventFreezeFrameDataEx
        OpEventGetEventFreezeFrameDataEx_GetEventFreezeFrameDataEx_EvtInfo_DTC_0x403a21: start-on-event=DemSatellite_0InternalBehavior/GetEventFreezeFrameDataEx, operation=EvtInfo_DTC_0x403a21.GetEventFreezeFrameDataEx
        OpEventGetEventFreezeFrameDataEx_GetEventFreezeFrameDataEx_Event_DTC_0x403a21: start-on-event=DemSatellite_0InternalBehavior/GetEventFreezeFrameDataEx, operation=Event_DTC_0x403a21.GetEventFreezeFrameDataEx
        OpEventGetEventFreezeFrameDataEx_GetEventFreezeFrameDataEx_EvtInfo_DTC_0x403a22: start-on-event=DemSatellite_0InternalBehavior/GetEventFreezeFrameDataEx, operation=EvtInfo_DTC_0x403a22.GetEventFreezeFrameDataEx
        OpEventGetEventFreezeFrameDataEx_GetEventFreezeFrameDataEx_Event_DTC_0x403a22: start-on-event=DemSatellite_0InternalBehavior/GetEventFreezeFrameDataEx, operation=Event_DTC_0x403a22.GetEventFreezeFrameDataEx
        OpEventGetEventFreezeFrameDataEx_GetEventFreezeFrameDataEx_EvtInfo_DTC_0x403422: start-on-event=DemSatellite_0InternalBehavior/GetEventFreezeFrameDataEx, operation=EvtInfo_DTC_0x403422.GetEventFreezeFrameDataEx
        OpEventGetEventFreezeFrameDataEx_GetEventFreezeFrameDataEx_Event_DTC_0x403422: start-on-event=DemSatellite_0InternalBehavior/GetEventFreezeFrameDataEx, operation=Event_DTC_0x403422.GetEventFreezeFrameDataEx
        OpEventGetEventFreezeFrameDataEx_GetEventFreezeFrameDataEx_EvtInfo_DTC_0x403421: start-on-event=DemSatellite_0InternalBehavior/GetEventFreezeFrameDataEx, operation=EvtInfo_DTC_0x403421.GetEventFreezeFrameDataEx
        OpEventGetEventFreezeFrameDataEx_GetEventFreezeFrameDataEx_Event_DTC_0x403421: start-on-event=DemSatellite_0InternalBehavior/GetEventFreezeFrameDataEx, operation=Event_DTC_0x403421.GetEventFreezeFrameDataEx
        OpEventGetEventFreezeFrameDataEx_GetEventFreezeFrameDataEx_EvtInfo_DTC_0x402013: start-on-event=DemSatellite_0InternalBehavior/GetEventFreezeFrameDataEx, operation=EvtInfo_DTC_0x402013.GetEventFreezeFrameDataEx
        OpEventGetEventFreezeFrameDataEx_GetEventFreezeFrameDataEx_Event_DTC_0x402013: start-on-event=DemSatellite_0InternalBehavior/GetEventFreezeFrameDataEx, operation=Event_DTC_0x402013.GetEventFreezeFrameDataEx
        OpEventGetEventFreezeFrameDataEx_GetEventFreezeFrameDataEx_EvtInfo_DTC_0x402012: start-on-event=DemSatellite_0InternalBehavior/GetEventFreezeFrameDataEx, operation=EvtInfo_DTC_0x402012.GetEventFreezeFrameDataEx
        OpEventGetEventFreezeFrameDataEx_GetEventFreezeFrameDataEx_Event_DTC_0x402012: start-on-event=DemSatellite_0InternalBehavior/GetEventFreezeFrameDataEx, operation=Event_DTC_0x402012.GetEventFreezeFrameDataEx
        OpEventGetEventFreezeFrameDataEx_GetEventFreezeFrameDataEx_EvtInfo_DTC_0x402025: start-on-event=DemSatellite_0InternalBehavior/GetEventFreezeFrameDataEx, operation=EvtInfo_DTC_0x402025.GetEventFreezeFrameDataEx
        OpEventGetEventFreezeFrameDataEx_GetEventFreezeFrameDataEx_Event_DTC_0x402025: start-on-event=DemSatellite_0InternalBehavior/GetEventFreezeFrameDataEx, operation=Event_DTC_0x402025.GetEventFreezeFrameDataEx
        OpEventGetEventFreezeFrameDataEx_GetEventFreezeFrameDataEx_EvtInfo_DTC_0x403713: start-on-event=DemSatellite_0InternalBehavior/GetEventFreezeFrameDataEx, operation=EvtInfo_DTC_0x403713.GetEventFreezeFrameDataEx
        OpEventGetEventFreezeFrameDataEx_GetEventFreezeFrameDataEx_Event_DTC_0x403713: start-on-event=DemSatellite_0InternalBehavior/GetEventFreezeFrameDataEx, operation=Event_DTC_0x403713.GetEventFreezeFrameDataEx
        OpEventGetEventFreezeFrameDataEx_GetEventFreezeFrameDataEx_EvtInfo_DTC_0x406222: start-on-event=DemSatellite_0InternalBehavior/GetEventFreezeFrameDataEx, operation=EvtInfo_DTC_0x406222.GetEventFreezeFrameDataEx
        OpEventGetEventFreezeFrameDataEx_GetEventFreezeFrameDataEx_Event_DTC_0x406222: start-on-event=DemSatellite_0InternalBehavior/GetEventFreezeFrameDataEx, operation=Event_DTC_0x406222.GetEventFreezeFrameDataEx
        OpEventGetEventFreezeFrameDataEx_GetEventFreezeFrameDataEx_EvtInfo_DTC_0x406221: start-on-event=DemSatellite_0InternalBehavior/GetEventFreezeFrameDataEx, operation=EvtInfo_DTC_0x406221.GetEventFreezeFrameDataEx
        OpEventGetEventFreezeFrameDataEx_GetEventFreezeFrameDataEx_Event_DTC_0x406221: start-on-event=DemSatellite_0InternalBehavior/GetEventFreezeFrameDataEx, operation=Event_DTC_0x406221.GetEventFreezeFrameDataEx
        OpEventGetEventFreezeFrameDataEx_GetEventFreezeFrameDataEx_EvtInfo_DTC_0x406225: start-on-event=DemSatellite_0InternalBehavior/GetEventFreezeFrameDataEx, operation=EvtInfo_DTC_0x406225.GetEventFreezeFrameDataEx
        OpEventGetEventFreezeFrameDataEx_GetEventFreezeFrameDataEx_Event_DTC_0x406225: start-on-event=DemSatellite_0InternalBehavior/GetEventFreezeFrameDataEx, operation=Event_DTC_0x406225.GetEventFreezeFrameDataEx
        OpEventGetEventFreezeFrameDataEx_GetEventFreezeFrameDataEx_EvtInfo_DTC_0x403113: start-on-event=DemSatellite_0InternalBehavior/GetEventFreezeFrameDataEx, operation=EvtInfo_DTC_0x403113.GetEventFreezeFrameDataEx
        OpEventGetEventFreezeFrameDataEx_GetEventFreezeFrameDataEx_Event_DTC_0x403113: start-on-event=DemSatellite_0InternalBehavior/GetEventFreezeFrameDataEx, operation=Event_DTC_0x403113.GetEventFreezeFrameDataEx
        OpEventGetEventFreezeFrameDataEx_GetEventFreezeFrameDataEx_EvtInfo_DTC_0x403721: start-on-event=DemSatellite_0InternalBehavior/GetEventFreezeFrameDataEx, operation=EvtInfo_DTC_0x403721.GetEventFreezeFrameDataEx
        OpEventGetEventFreezeFrameDataEx_GetEventFreezeFrameDataEx_Event_DTC_0x403721: start-on-event=DemSatellite_0InternalBehavior/GetEventFreezeFrameDataEx, operation=Event_DTC_0x403721.GetEventFreezeFrameDataEx
        OpEventGetEventFreezeFrameDataEx_GetEventFreezeFrameDataEx_EvtInfo_DTC_0x403722: start-on-event=DemSatellite_0InternalBehavior/GetEventFreezeFrameDataEx, operation=EvtInfo_DTC_0x403722.GetEventFreezeFrameDataEx
        OpEventGetEventFreezeFrameDataEx_GetEventFreezeFrameDataEx_Event_DTC_0x403722: start-on-event=DemSatellite_0InternalBehavior/GetEventFreezeFrameDataEx, operation=Event_DTC_0x403722.GetEventFreezeFrameDataEx
        OpEventGetEventFreezeFrameDataEx_GetEventFreezeFrameDataEx_EvtInfo_DTC_0x404011: start-on-event=DemSatellite_0InternalBehavior/GetEventFreezeFrameDataEx, operation=EvtInfo_DTC_0x404011.GetEventFreezeFrameDataEx
        OpEventGetEventFreezeFrameDataEx_GetEventFreezeFrameDataEx_Event_DTC_0x404011: start-on-event=DemSatellite_0InternalBehavior/GetEventFreezeFrameDataEx, operation=Event_DTC_0x404011.GetEventFreezeFrameDataEx
        OpEventGetEventFreezeFrameDataEx_GetEventFreezeFrameDataEx_EvtInfo_DTC_0x404212: start-on-event=DemSatellite_0InternalBehavior/GetEventFreezeFrameDataEx, operation=EvtInfo_DTC_0x404212.GetEventFreezeFrameDataEx
        OpEventGetEventFreezeFrameDataEx_GetEventFreezeFrameDataEx_Event_DTC_0x404212: start-on-event=DemSatellite_0InternalBehavior/GetEventFreezeFrameDataEx, operation=Event_DTC_0x404212.GetEventFreezeFrameDataEx
        OpEventGetEventFreezeFrameDataEx_GetEventFreezeFrameDataEx_EvtInfo_DTC_0x404213: start-on-event=DemSatellite_0InternalBehavior/GetEventFreezeFrameDataEx, operation=EvtInfo_DTC_0x404213.GetEventFreezeFrameDataEx
        OpEventGetEventFreezeFrameDataEx_GetEventFreezeFrameDataEx_Event_DTC_0x404213: start-on-event=DemSatellite_0InternalBehavior/GetEventFreezeFrameDataEx, operation=Event_DTC_0x404213.GetEventFreezeFrameDataEx
        OpEventGetEventFreezeFrameDataEx_GetEventFreezeFrameDataEx_EvtInfo_DTC_0x404012: start-on-event=DemSatellite_0InternalBehavior/GetEventFreezeFrameDataEx, operation=EvtInfo_DTC_0x404012.GetEventFreezeFrameDataEx
        OpEventGetEventFreezeFrameDataEx_GetEventFreezeFrameDataEx_Event_DTC_0x404012: start-on-event=DemSatellite_0InternalBehavior/GetEventFreezeFrameDataEx, operation=Event_DTC_0x404012.GetEventFreezeFrameDataEx
        OpEventGetEventFreezeFrameDataEx_GetEventFreezeFrameDataEx_EvtInfo_DTC_0x403121: start-on-event=DemSatellite_0InternalBehavior/GetEventFreezeFrameDataEx, operation=EvtInfo_DTC_0x403121.GetEventFreezeFrameDataEx
        OpEventGetEventFreezeFrameDataEx_GetEventFreezeFrameDataEx_Event_DTC_0x403121: start-on-event=DemSatellite_0InternalBehavior/GetEventFreezeFrameDataEx, operation=Event_DTC_0x403121.GetEventFreezeFrameDataEx
        OpEventGetEventFreezeFrameDataEx_GetEventFreezeFrameDataEx_EvtInfo_DTC_0x404211: start-on-event=DemSatellite_0InternalBehavior/GetEventFreezeFrameDataEx, operation=EvtInfo_DTC_0x404211.GetEventFreezeFrameDataEx
        OpEventGetEventFreezeFrameDataEx_GetEventFreezeFrameDataEx_Event_DTC_0x404211: start-on-event=DemSatellite_0InternalBehavior/GetEventFreezeFrameDataEx, operation=Event_DTC_0x404211.GetEventFreezeFrameDataEx
        OpEventGetEventFreezeFrameDataEx_GetEventFreezeFrameDataEx_EvtInfo_DTC_0x404013: start-on-event=DemSatellite_0InternalBehavior/GetEventFreezeFrameDataEx, operation=EvtInfo_DTC_0x404013.GetEventFreezeFrameDataEx
        OpEventGetEventFreezeFrameDataEx_GetEventFreezeFrameDataEx_Event_DTC_0x404013: start-on-event=DemSatellite_0InternalBehavior/GetEventFreezeFrameDataEx, operation=Event_DTC_0x404013.GetEventFreezeFrameDataEx
        OpEventGetEventFreezeFrameDataEx_GetEventFreezeFrameDataEx_EvtInfo_DTC_0x403122: start-on-event=DemSatellite_0InternalBehavior/GetEventFreezeFrameDataEx, operation=EvtInfo_DTC_0x403122.GetEventFreezeFrameDataEx
        OpEventGetEventFreezeFrameDataEx_GetEventFreezeFrameDataEx_Event_DTC_0x403122: start-on-event=DemSatellite_0InternalBehavior/GetEventFreezeFrameDataEx, operation=Event_DTC_0x403122.GetEventFreezeFrameDataEx
        OpEventGetEventFreezeFrameDataEx_GetEventFreezeFrameDataEx_EvtInfo_DTC_0x403a13: start-on-event=DemSatellite_0InternalBehavior/GetEventFreezeFrameDataEx, operation=EvtInfo_DTC_0x403a13.GetEventFreezeFrameDataEx
        OpEventGetEventFreezeFrameDataEx_GetEventFreezeFrameDataEx_Event_DTC_0x403a13: start-on-event=DemSatellite_0InternalBehavior/GetEventFreezeFrameDataEx, operation=Event_DTC_0x403a13.GetEventFreezeFrameDataEx
        OpEventGetEventExtendedDataRecordEx_GetEventExtendedDataRecordEx_EvtInfo_DTC_0x403413: start-on-event=DemSatellite_0InternalBehavior/GetEventExtendedDataRecordEx, operation=EvtInfo_DTC_0x403413.GetEventExtendedDataRecordEx
        OpEventGetEventExtendedDataRecordEx_GetEventExtendedDataRecordEx_Event_DTC_0x403413: start-on-event=DemSatellite_0InternalBehavior/GetEventExtendedDataRecordEx, operation=Event_DTC_0x403413.GetEventExtendedDataRecordEx
        OpEventGetEventExtendedDataRecordEx_GetEventExtendedDataRecordEx_EvtInfo_DTC_0x404428: start-on-event=DemSatellite_0InternalBehavior/GetEventExtendedDataRecordEx, operation=EvtInfo_DTC_0x404428.GetEventExtendedDataRecordEx
        OpEventGetEventExtendedDataRecordEx_GetEventExtendedDataRecordEx_Event_DTC_0x404428: start-on-event=DemSatellite_0InternalBehavior/GetEventExtendedDataRecordEx, operation=Event_DTC_0x404428.GetEventExtendedDataRecordEx
        OpEventGetEventExtendedDataRecordEx_GetEventExtendedDataRecordEx_EvtInfo_DTC_0x406321: start-on-event=DemSatellite_0InternalBehavior/GetEventExtendedDataRecordEx, operation=EvtInfo_DTC_0x406321.GetEventExtendedDataRecordEx
        OpEventGetEventExtendedDataRecordEx_GetEventExtendedDataRecordEx_Event_DTC_0x406321: start-on-event=DemSatellite_0InternalBehavior/GetEventExtendedDataRecordEx, operation=Event_DTC_0x406321.GetEventExtendedDataRecordEx
        OpEventGetEventExtendedDataRecordEx_GetEventExtendedDataRecordEx_EvtInfo_DTC_0x406325: start-on-event=DemSatellite_0InternalBehavior/GetEventExtendedDataRecordEx, operation=EvtInfo_DTC_0x406325.GetEventExtendedDataRecordEx
        OpEventGetEventExtendedDataRecordEx_GetEventExtendedDataRecordEx_Event_DTC_0x406325: start-on-event=DemSatellite_0InternalBehavior/GetEventExtendedDataRecordEx, operation=Event_DTC_0x406325.GetEventExtendedDataRecordEx
        OpEventGetEventExtendedDataRecordEx_GetEventExtendedDataRecordEx_EvtInfo_DTC_0x404421: start-on-event=DemSatellite_0InternalBehavior/GetEventExtendedDataRecordEx, operation=EvtInfo_DTC_0x404421.GetEventExtendedDataRecordEx
        OpEventGetEventExtendedDataRecordEx_GetEventExtendedDataRecordEx_Event_DTC_0x404421: start-on-event=DemSatellite_0InternalBehavior/GetEventExtendedDataRecordEx, operation=Event_DTC_0x404421.GetEventExtendedDataRecordEx
        OpEventGetEventExtendedDataRecordEx_GetEventExtendedDataRecordEx_EvtInfo_DTC_0x404422: start-on-event=DemSatellite_0InternalBehavior/GetEventExtendedDataRecordEx, operation=EvtInfo_DTC_0x404422.GetEventExtendedDataRecordEx
        OpEventGetEventExtendedDataRecordEx_GetEventExtendedDataRecordEx_Event_DTC_0x404422: start-on-event=DemSatellite_0InternalBehavior/GetEventExtendedDataRecordEx, operation=Event_DTC_0x404422.GetEventExtendedDataRecordEx
        OpEventGetEventExtendedDataRecordEx_GetEventExtendedDataRecordEx_EvtInfo_DTC_0x406322: start-on-event=DemSatellite_0InternalBehavior/GetEventExtendedDataRecordEx, operation=EvtInfo_DTC_0x406322.GetEventExtendedDataRecordEx
        OpEventGetEventExtendedDataRecordEx_GetEventExtendedDataRecordEx_Event_DTC_0x406322: start-on-event=DemSatellite_0InternalBehavior/GetEventExtendedDataRecordEx, operation=Event_DTC_0x406322.GetEventExtendedDataRecordEx
        OpEventGetEventExtendedDataRecordEx_GetEventExtendedDataRecordEx_EvtInfo_DTC_0x403a21: start-on-event=DemSatellite_0InternalBehavior/GetEventExtendedDataRecordEx, operation=EvtInfo_DTC_0x403a21.GetEventExtendedDataRecordEx
        OpEventGetEventExtendedDataRecordEx_GetEventExtendedDataRecordEx_Event_DTC_0x403a21: start-on-event=DemSatellite_0InternalBehavior/GetEventExtendedDataRecordEx, operation=Event_DTC_0x403a21.GetEventExtendedDataRecordEx
        OpEventGetEventExtendedDataRecordEx_GetEventExtendedDataRecordEx_EvtInfo_DTC_0x403a22: start-on-event=DemSatellite_0InternalBehavior/GetEventExtendedDataRecordEx, operation=EvtInfo_DTC_0x403a22.GetEventExtendedDataRecordEx
        OpEventGetEventExtendedDataRecordEx_GetEventExtendedDataRecordEx_Event_DTC_0x403a22: start-on-event=DemSatellite_0InternalBehavior/GetEventExtendedDataRecordEx, operation=Event_DTC_0x403a22.GetEventExtendedDataRecordEx
        OpEventGetEventExtendedDataRecordEx_GetEventExtendedDataRecordEx_EvtInfo_DTC_0x403422: start-on-event=DemSatellite_0InternalBehavior/GetEventExtendedDataRecordEx, operation=EvtInfo_DTC_0x403422.GetEventExtendedDataRecordEx
        OpEventGetEventExtendedDataRecordEx_GetEventExtendedDataRecordEx_Event_DTC_0x403422: start-on-event=DemSatellite_0InternalBehavior/GetEventExtendedDataRecordEx, operation=Event_DTC_0x403422.GetEventExtendedDataRecordEx
        OpEventGetEventExtendedDataRecordEx_GetEventExtendedDataRecordEx_EvtInfo_DTC_0x403421: start-on-event=DemSatellite_0InternalBehavior/GetEventExtendedDataRecordEx, operation=EvtInfo_DTC_0x403421.GetEventExtendedDataRecordEx
        OpEventGetEventExtendedDataRecordEx_GetEventExtendedDataRecordEx_Event_DTC_0x403421: start-on-event=DemSatellite_0InternalBehavior/GetEventExtendedDataRecordEx, operation=Event_DTC_0x403421.GetEventExtendedDataRecordEx
        OpEventGetEventExtendedDataRecordEx_GetEventExtendedDataRecordEx_EvtInfo_DTC_0x402013: start-on-event=DemSatellite_0InternalBehavior/GetEventExtendedDataRecordEx, operation=EvtInfo_DTC_0x402013.GetEventExtendedDataRecordEx
        OpEventGetEventExtendedDataRecordEx_GetEventExtendedDataRecordEx_Event_DTC_0x402013: start-on-event=DemSatellite_0InternalBehavior/GetEventExtendedDataRecordEx, operation=Event_DTC_0x402013.GetEventExtendedDataRecordEx
        OpEventGetEventExtendedDataRecordEx_GetEventExtendedDataRecordEx_EvtInfo_DTC_0x402012: start-on-event=DemSatellite_0InternalBehavior/GetEventExtendedDataRecordEx, operation=EvtInfo_DTC_0x402012.GetEventExtendedDataRecordEx
        OpEventGetEventExtendedDataRecordEx_GetEventExtendedDataRecordEx_Event_DTC_0x402012: start-on-event=DemSatellite_0InternalBehavior/GetEventExtendedDataRecordEx, operation=Event_DTC_0x402012.GetEventExtendedDataRecordEx
        OpEventGetEventExtendedDataRecordEx_GetEventExtendedDataRecordEx_EvtInfo_DTC_0x402025: start-on-event=DemSatellite_0InternalBehavior/GetEventExtendedDataRecordEx, operation=EvtInfo_DTC_0x402025.GetEventExtendedDataRecordEx
        OpEventGetEventExtendedDataRecordEx_GetEventExtendedDataRecordEx_Event_DTC_0x402025: start-on-event=DemSatellite_0InternalBehavior/GetEventExtendedDataRecordEx, operation=Event_DTC_0x402025.GetEventExtendedDataRecordEx
        OpEventGetEventExtendedDataRecordEx_GetEventExtendedDataRecordEx_EvtInfo_DTC_0x403713: start-on-event=DemSatellite_0InternalBehavior/GetEventExtendedDataRecordEx, operation=EvtInfo_DTC_0x403713.GetEventExtendedDataRecordEx
        OpEventGetEventExtendedDataRecordEx_GetEventExtendedDataRecordEx_Event_DTC_0x403713: start-on-event=DemSatellite_0InternalBehavior/GetEventExtendedDataRecordEx, operation=Event_DTC_0x403713.GetEventExtendedDataRecordEx
        OpEventGetEventExtendedDataRecordEx_GetEventExtendedDataRecordEx_EvtInfo_DTC_0x406222: start-on-event=DemSatellite_0InternalBehavior/GetEventExtendedDataRecordEx, operation=EvtInfo_DTC_0x406222.GetEventExtendedDataRecordEx
        OpEventGetEventExtendedDataRecordEx_GetEventExtendedDataRecordEx_Event_DTC_0x406222: start-on-event=DemSatellite_0InternalBehavior/GetEventExtendedDataRecordEx, operation=Event_DTC_0x406222.GetEventExtendedDataRecordEx
        OpEventGetEventExtendedDataRecordEx_GetEventExtendedDataRecordEx_EvtInfo_DTC_0x406221: start-on-event=DemSatellite_0InternalBehavior/GetEventExtendedDataRecordEx, operation=EvtInfo_DTC_0x406221.GetEventExtendedDataRecordEx
        OpEventGetEventExtendedDataRecordEx_GetEventExtendedDataRecordEx_Event_DTC_0x406221: start-on-event=DemSatellite_0InternalBehavior/GetEventExtendedDataRecordEx, operation=Event_DTC_0x406221.GetEventExtendedDataRecordEx
        OpEventGetEventExtendedDataRecordEx_GetEventExtendedDataRecordEx_EvtInfo_DTC_0x406225: start-on-event=DemSatellite_0InternalBehavior/GetEventExtendedDataRecordEx, operation=EvtInfo_DTC_0x406225.GetEventExtendedDataRecordEx
        OpEventGetEventExtendedDataRecordEx_GetEventExtendedDataRecordEx_Event_DTC_0x406225: start-on-event=DemSatellite_0InternalBehavior/GetEventExtendedDataRecordEx, operation=Event_DTC_0x406225.GetEventExtendedDataRecordEx
        OpEventGetEventExtendedDataRecordEx_GetEventExtendedDataRecordEx_EvtInfo_DTC_0x403113: start-on-event=DemSatellite_0InternalBehavior/GetEventExtendedDataRecordEx, operation=EvtInfo_DTC_0x403113.GetEventExtendedDataRecordEx
        OpEventGetEventExtendedDataRecordEx_GetEventExtendedDataRecordEx_Event_DTC_0x403113: start-on-event=DemSatellite_0InternalBehavior/GetEventExtendedDataRecordEx, operation=Event_DTC_0x403113.GetEventExtendedDataRecordEx
        OpEventGetEventExtendedDataRecordEx_GetEventExtendedDataRecordEx_EvtInfo_DTC_0x403721: start-on-event=DemSatellite_0InternalBehavior/GetEventExtendedDataRecordEx, operation=EvtInfo_DTC_0x403721.GetEventExtendedDataRecordEx
        OpEventGetEventExtendedDataRecordEx_GetEventExtendedDataRecordEx_Event_DTC_0x403721: start-on-event=DemSatellite_0InternalBehavior/GetEventExtendedDataRecordEx, operation=Event_DTC_0x403721.GetEventExtendedDataRecordEx
        OpEventGetEventExtendedDataRecordEx_GetEventExtendedDataRecordEx_EvtInfo_DTC_0x403722: start-on-event=DemSatellite_0InternalBehavior/GetEventExtendedDataRecordEx, operation=EvtInfo_DTC_0x403722.GetEventExtendedDataRecordEx
        OpEventGetEventExtendedDataRecordEx_GetEventExtendedDataRecordEx_Event_DTC_0x403722: start-on-event=DemSatellite_0InternalBehavior/GetEventExtendedDataRecordEx, operation=Event_DTC_0x403722.GetEventExtendedDataRecordEx
        OpEventGetEventExtendedDataRecordEx_GetEventExtendedDataRecordEx_EvtInfo_DTC_0x404011: start-on-event=DemSatellite_0InternalBehavior/GetEventExtendedDataRecordEx, operation=EvtInfo_DTC_0x404011.GetEventExtendedDataRecordEx
        OpEventGetEventExtendedDataRecordEx_GetEventExtendedDataRecordEx_Event_DTC_0x404011: start-on-event=DemSatellite_0InternalBehavior/GetEventExtendedDataRecordEx, operation=Event_DTC_0x404011.GetEventExtendedDataRecordEx
        OpEventGetEventExtendedDataRecordEx_GetEventExtendedDataRecordEx_EvtInfo_DTC_0x404212: start-on-event=DemSatellite_0InternalBehavior/GetEventExtendedDataRecordEx, operation=EvtInfo_DTC_0x404212.GetEventExtendedDataRecordEx
        OpEventGetEventExtendedDataRecordEx_GetEventExtendedDataRecordEx_Event_DTC_0x404212: start-on-event=DemSatellite_0InternalBehavior/GetEventExtendedDataRecordEx, operation=Event_DTC_0x404212.GetEventExtendedDataRecordEx
        OpEventGetEventExtendedDataRecordEx_GetEventExtendedDataRecordEx_EvtInfo_DTC_0x404213: start-on-event=DemSatellite_0InternalBehavior/GetEventExtendedDataRecordEx, operation=EvtInfo_DTC_0x404213.GetEventExtendedDataRecordEx
        OpEventGetEventExtendedDataRecordEx_GetEventExtendedDataRecordEx_Event_DTC_0x404213: start-on-event=DemSatellite_0InternalBehavior/GetEventExtendedDataRecordEx, operation=Event_DTC_0x404213.GetEventExtendedDataRecordEx
        OpEventGetEventExtendedDataRecordEx_GetEventExtendedDataRecordEx_EvtInfo_DTC_0x404012: start-on-event=DemSatellite_0InternalBehavior/GetEventExtendedDataRecordEx, operation=EvtInfo_DTC_0x404012.GetEventExtendedDataRecordEx
        OpEventGetEventExtendedDataRecordEx_GetEventExtendedDataRecordEx_Event_DTC_0x404012: start-on-event=DemSatellite_0InternalBehavior/GetEventExtendedDataRecordEx, operation=Event_DTC_0x404012.GetEventExtendedDataRecordEx
        OpEventGetEventExtendedDataRecordEx_GetEventExtendedDataRecordEx_EvtInfo_DTC_0x403121: start-on-event=DemSatellite_0InternalBehavior/GetEventExtendedDataRecordEx, operation=EvtInfo_DTC_0x403121.GetEventExtendedDataRecordEx
        OpEventGetEventExtendedDataRecordEx_GetEventExtendedDataRecordEx_Event_DTC_0x403121: start-on-event=DemSatellite_0InternalBehavior/GetEventExtendedDataRecordEx, operation=Event_DTC_0x403121.GetEventExtendedDataRecordEx
        OpEventGetEventExtendedDataRecordEx_GetEventExtendedDataRecordEx_EvtInfo_DTC_0x404211: start-on-event=DemSatellite_0InternalBehavior/GetEventExtendedDataRecordEx, operation=EvtInfo_DTC_0x404211.GetEventExtendedDataRecordEx
        OpEventGetEventExtendedDataRecordEx_GetEventExtendedDataRecordEx_Event_DTC_0x404211: start-on-event=DemSatellite_0InternalBehavior/GetEventExtendedDataRecordEx, operation=Event_DTC_0x404211.GetEventExtendedDataRecordEx
        OpEventGetEventExtendedDataRecordEx_GetEventExtendedDataRecordEx_EvtInfo_DTC_0x404013: start-on-event=DemSatellite_0InternalBehavior/GetEventExtendedDataRecordEx, operation=EvtInfo_DTC_0x404013.GetEventExtendedDataRecordEx
        OpEventGetEventExtendedDataRecordEx_GetEventExtendedDataRecordEx_Event_DTC_0x404013: start-on-event=DemSatellite_0InternalBehavior/GetEventExtendedDataRecordEx, operation=Event_DTC_0x404013.GetEventExtendedDataRecordEx
        OpEventGetEventExtendedDataRecordEx_GetEventExtendedDataRecordEx_EvtInfo_DTC_0x403122: start-on-event=DemSatellite_0InternalBehavior/GetEventExtendedDataRecordEx, operation=EvtInfo_DTC_0x403122.GetEventExtendedDataRecordEx
        OpEventGetEventExtendedDataRecordEx_GetEventExtendedDataRecordEx_Event_DTC_0x403122: start-on-event=DemSatellite_0InternalBehavior/GetEventExtendedDataRecordEx, operation=Event_DTC_0x403122.GetEventExtendedDataRecordEx
        OpEventGetEventExtendedDataRecordEx_GetEventExtendedDataRecordEx_EvtInfo_DTC_0x403a13: start-on-event=DemSatellite_0InternalBehavior/GetEventExtendedDataRecordEx, operation=EvtInfo_DTC_0x403a13.GetEventExtendedDataRecordEx
        OpEventGetEventExtendedDataRecordEx_GetEventExtendedDataRecordEx_Event_DTC_0x403a13: start-on-event=DemSatellite_0InternalBehavior/GetEventExtendedDataRecordEx, operation=Event_DTC_0x403a13.GetEventExtendedDataRecordEx
        OpEventGetEventEnableCondition_GetEventEnableCondition_EvtInfo_DTC_0x403413: start-on-event=DemSatellite_0InternalBehavior/GetEventEnableCondition, operation=EvtInfo_DTC_0x403413.GetEventEnableCondition
        OpEventGetEventEnableCondition_GetEventEnableCondition_EvtInfo_DTC_0x404428: start-on-event=DemSatellite_0InternalBehavior/GetEventEnableCondition, operation=EvtInfo_DTC_0x404428.GetEventEnableCondition
        OpEventGetEventEnableCondition_GetEventEnableCondition_EvtInfo_DTC_0x406321: start-on-event=DemSatellite_0InternalBehavior/GetEventEnableCondition, operation=EvtInfo_DTC_0x406321.GetEventEnableCondition
        OpEventGetEventEnableCondition_GetEventEnableCondition_EvtInfo_DTC_0x406325: start-on-event=DemSatellite_0InternalBehavior/GetEventEnableCondition, operation=EvtInfo_DTC_0x406325.GetEventEnableCondition
        OpEventGetEventEnableCondition_GetEventEnableCondition_EvtInfo_DTC_0x404421: start-on-event=DemSatellite_0InternalBehavior/GetEventEnableCondition, operation=EvtInfo_DTC_0x404421.GetEventEnableCondition
        OpEventGetEventEnableCondition_GetEventEnableCondition_EvtInfo_DTC_0x404422: start-on-event=DemSatellite_0InternalBehavior/GetEventEnableCondition, operation=EvtInfo_DTC_0x404422.GetEventEnableCondition
        OpEventGetEventEnableCondition_GetEventEnableCondition_EvtInfo_DTC_0x406322: start-on-event=DemSatellite_0InternalBehavior/GetEventEnableCondition, operation=EvtInfo_DTC_0x406322.GetEventEnableCondition
        OpEventGetEventEnableCondition_GetEventEnableCondition_EvtInfo_DTC_0x403a21: start-on-event=DemSatellite_0InternalBehavior/GetEventEnableCondition, operation=EvtInfo_DTC_0x403a21.GetEventEnableCondition
        OpEventGetEventEnableCondition_GetEventEnableCondition_EvtInfo_DTC_0x403a22: start-on-event=DemSatellite_0InternalBehavior/GetEventEnableCondition, operation=EvtInfo_DTC_0x403a22.GetEventEnableCondition
        OpEventGetEventEnableCondition_GetEventEnableCondition_EvtInfo_DTC_0x403422: start-on-event=DemSatellite_0InternalBehavior/GetEventEnableCondition, operation=EvtInfo_DTC_0x403422.GetEventEnableCondition
        OpEventGetEventEnableCondition_GetEventEnableCondition_EvtInfo_DTC_0x403421: start-on-event=DemSatellite_0InternalBehavior/GetEventEnableCondition, operation=EvtInfo_DTC_0x403421.GetEventEnableCondition
        OpEventGetEventEnableCondition_GetEventEnableCondition_EvtInfo_DTC_0x402013: start-on-event=DemSatellite_0InternalBehavior/GetEventEnableCondition, operation=EvtInfo_DTC_0x402013.GetEventEnableCondition
        OpEventGetEventEnableCondition_GetEventEnableCondition_EvtInfo_DTC_0x402012: start-on-event=DemSatellite_0InternalBehavior/GetEventEnableCondition, operation=EvtInfo_DTC_0x402012.GetEventEnableCondition
        OpEventGetEventEnableCondition_GetEventEnableCondition_EvtInfo_DTC_0x402025: start-on-event=DemSatellite_0InternalBehavior/GetEventEnableCondition, operation=EvtInfo_DTC_0x402025.GetEventEnableCondition
        OpEventGetEventEnableCondition_GetEventEnableCondition_EvtInfo_DTC_0x403713: start-on-event=DemSatellite_0InternalBehavior/GetEventEnableCondition, operation=EvtInfo_DTC_0x403713.GetEventEnableCondition
        OpEventGetEventEnableCondition_GetEventEnableCondition_EvtInfo_DTC_0x406222: start-on-event=DemSatellite_0InternalBehavior/GetEventEnableCondition, operation=EvtInfo_DTC_0x406222.GetEventEnableCondition
        OpEventGetEventEnableCondition_GetEventEnableCondition_EvtInfo_DTC_0x406221: start-on-event=DemSatellite_0InternalBehavior/GetEventEnableCondition, operation=EvtInfo_DTC_0x406221.GetEventEnableCondition
        OpEventGetEventEnableCondition_GetEventEnableCondition_EvtInfo_DTC_0x406225: start-on-event=DemSatellite_0InternalBehavior/GetEventEnableCondition, operation=EvtInfo_DTC_0x406225.GetEventEnableCondition
        OpEventGetEventEnableCondition_GetEventEnableCondition_EvtInfo_DTC_0x403113: start-on-event=DemSatellite_0InternalBehavior/GetEventEnableCondition, operation=EvtInfo_DTC_0x403113.GetEventEnableCondition
        OpEventGetEventEnableCondition_GetEventEnableCondition_EvtInfo_DTC_0x403721: start-on-event=DemSatellite_0InternalBehavior/GetEventEnableCondition, operation=EvtInfo_DTC_0x403721.GetEventEnableCondition
        OpEventGetEventEnableCondition_GetEventEnableCondition_EvtInfo_DTC_0x403722: start-on-event=DemSatellite_0InternalBehavior/GetEventEnableCondition, operation=EvtInfo_DTC_0x403722.GetEventEnableCondition
        OpEventGetEventEnableCondition_GetEventEnableCondition_EvtInfo_DTC_0x404011: start-on-event=DemSatellite_0InternalBehavior/GetEventEnableCondition, operation=EvtInfo_DTC_0x404011.GetEventEnableCondition
        OpEventGetEventEnableCondition_GetEventEnableCondition_EvtInfo_DTC_0x404212: start-on-event=DemSatellite_0InternalBehavior/GetEventEnableCondition, operation=EvtInfo_DTC_0x404212.GetEventEnableCondition
        OpEventGetEventEnableCondition_GetEventEnableCondition_EvtInfo_DTC_0x404213: start-on-event=DemSatellite_0InternalBehavior/GetEventEnableCondition, operation=EvtInfo_DTC_0x404213.GetEventEnableCondition
        OpEventGetEventEnableCondition_GetEventEnableCondition_EvtInfo_DTC_0x404012: start-on-event=DemSatellite_0InternalBehavior/GetEventEnableCondition, operation=EvtInfo_DTC_0x404012.GetEventEnableCondition
        OpEventGetEventEnableCondition_GetEventEnableCondition_EvtInfo_DTC_0x403121: start-on-event=DemSatellite_0InternalBehavior/GetEventEnableCondition, operation=EvtInfo_DTC_0x403121.GetEventEnableCondition
        OpEventGetEventEnableCondition_GetEventEnableCondition_EvtInfo_DTC_0x404211: start-on-event=DemSatellite_0InternalBehavior/GetEventEnableCondition, operation=EvtInfo_DTC_0x404211.GetEventEnableCondition
        OpEventGetEventEnableCondition_GetEventEnableCondition_EvtInfo_DTC_0x404013: start-on-event=DemSatellite_0InternalBehavior/GetEventEnableCondition, operation=EvtInfo_DTC_0x404013.GetEventEnableCondition
        OpEventGetEventEnableCondition_GetEventEnableCondition_EvtInfo_DTC_0x403122: start-on-event=DemSatellite_0InternalBehavior/GetEventEnableCondition, operation=EvtInfo_DTC_0x403122.GetEventEnableCondition
        OpEventGetEventEnableCondition_GetEventEnableCondition_EvtInfo_DTC_0x403a13: start-on-event=DemSatellite_0InternalBehavior/GetEventEnableCondition, operation=EvtInfo_DTC_0x403a13.GetEventEnableCondition
        OpEventGetDebouncingOfEvent_GetDebouncingOfEvent_EvtInfo_DTC_0x403413: start-on-event=DemSatellite_0InternalBehavior/GetDebouncingOfEvent, operation=EvtInfo_DTC_0x403413.GetDebouncingOfEvent
        OpEventGetDebouncingOfEvent_GetDebouncingOfEvent_EvtInfo_DTC_0x404428: start-on-event=DemSatellite_0InternalBehavior/GetDebouncingOfEvent, operation=EvtInfo_DTC_0x404428.GetDebouncingOfEvent
        OpEventGetDebouncingOfEvent_GetDebouncingOfEvent_EvtInfo_DTC_0x406321: start-on-event=DemSatellite_0InternalBehavior/GetDebouncingOfEvent, operation=EvtInfo_DTC_0x406321.GetDebouncingOfEvent
        OpEventGetDebouncingOfEvent_GetDebouncingOfEvent_EvtInfo_DTC_0x406325: start-on-event=DemSatellite_0InternalBehavior/GetDebouncingOfEvent, operation=EvtInfo_DTC_0x406325.GetDebouncingOfEvent
        OpEventGetDebouncingOfEvent_GetDebouncingOfEvent_EvtInfo_DTC_0x404421: start-on-event=DemSatellite_0InternalBehavior/GetDebouncingOfEvent, operation=EvtInfo_DTC_0x404421.GetDebouncingOfEvent
        OpEventGetDebouncingOfEvent_GetDebouncingOfEvent_EvtInfo_DTC_0x404422: start-on-event=DemSatellite_0InternalBehavior/GetDebouncingOfEvent, operation=EvtInfo_DTC_0x404422.GetDebouncingOfEvent
        OpEventGetDebouncingOfEvent_GetDebouncingOfEvent_EvtInfo_DTC_0x406322: start-on-event=DemSatellite_0InternalBehavior/GetDebouncingOfEvent, operation=EvtInfo_DTC_0x406322.GetDebouncingOfEvent
        OpEventGetDebouncingOfEvent_GetDebouncingOfEvent_EvtInfo_DTC_0x403a21: start-on-event=DemSatellite_0InternalBehavior/GetDebouncingOfEvent, operation=EvtInfo_DTC_0x403a21.GetDebouncingOfEvent
        OpEventGetDebouncingOfEvent_GetDebouncingOfEvent_EvtInfo_DTC_0x403a22: start-on-event=DemSatellite_0InternalBehavior/GetDebouncingOfEvent, operation=EvtInfo_DTC_0x403a22.GetDebouncingOfEvent
        OpEventGetDebouncingOfEvent_GetDebouncingOfEvent_EvtInfo_DTC_0x403422: start-on-event=DemSatellite_0InternalBehavior/GetDebouncingOfEvent, operation=EvtInfo_DTC_0x403422.GetDebouncingOfEvent
        OpEventGetDebouncingOfEvent_GetDebouncingOfEvent_EvtInfo_DTC_0x403421: start-on-event=DemSatellite_0InternalBehavior/GetDebouncingOfEvent, operation=EvtInfo_DTC_0x403421.GetDebouncingOfEvent
        OpEventGetDebouncingOfEvent_GetDebouncingOfEvent_EvtInfo_DTC_0x402013: start-on-event=DemSatellite_0InternalBehavior/GetDebouncingOfEvent, operation=EvtInfo_DTC_0x402013.GetDebouncingOfEvent
        OpEventGetDebouncingOfEvent_GetDebouncingOfEvent_EvtInfo_DTC_0x402012: start-on-event=DemSatellite_0InternalBehavior/GetDebouncingOfEvent, operation=EvtInfo_DTC_0x402012.GetDebouncingOfEvent
        OpEventGetDebouncingOfEvent_GetDebouncingOfEvent_EvtInfo_DTC_0x402025: start-on-event=DemSatellite_0InternalBehavior/GetDebouncingOfEvent, operation=EvtInfo_DTC_0x402025.GetDebouncingOfEvent
        OpEventGetDebouncingOfEvent_GetDebouncingOfEvent_EvtInfo_DTC_0x403713: start-on-event=DemSatellite_0InternalBehavior/GetDebouncingOfEvent, operation=EvtInfo_DTC_0x403713.GetDebouncingOfEvent
        OpEventGetDebouncingOfEvent_GetDebouncingOfEvent_EvtInfo_DTC_0x406222: start-on-event=DemSatellite_0InternalBehavior/GetDebouncingOfEvent, operation=EvtInfo_DTC_0x406222.GetDebouncingOfEvent
        OpEventGetDebouncingOfEvent_GetDebouncingOfEvent_EvtInfo_DTC_0x406221: start-on-event=DemSatellite_0InternalBehavior/GetDebouncingOfEvent, operation=EvtInfo_DTC_0x406221.GetDebouncingOfEvent
        OpEventGetDebouncingOfEvent_GetDebouncingOfEvent_EvtInfo_DTC_0x406225: start-on-event=DemSatellite_0InternalBehavior/GetDebouncingOfEvent, operation=EvtInfo_DTC_0x406225.GetDebouncingOfEvent
        OpEventGetDebouncingOfEvent_GetDebouncingOfEvent_EvtInfo_DTC_0x403113: start-on-event=DemSatellite_0InternalBehavior/GetDebouncingOfEvent, operation=EvtInfo_DTC_0x403113.GetDebouncingOfEvent
        OpEventGetDebouncingOfEvent_GetDebouncingOfEvent_EvtInfo_DTC_0x403721: start-on-event=DemSatellite_0InternalBehavior/GetDebouncingOfEvent, operation=EvtInfo_DTC_0x403721.GetDebouncingOfEvent
        OpEventGetDebouncingOfEvent_GetDebouncingOfEvent_EvtInfo_DTC_0x403722: start-on-event=DemSatellite_0InternalBehavior/GetDebouncingOfEvent, operation=EvtInfo_DTC_0x403722.GetDebouncingOfEvent
        OpEventGetDebouncingOfEvent_GetDebouncingOfEvent_EvtInfo_DTC_0x404011: start-on-event=DemSatellite_0InternalBehavior/GetDebouncingOfEvent, operation=EvtInfo_DTC_0x404011.GetDebouncingOfEvent
        OpEventGetDebouncingOfEvent_GetDebouncingOfEvent_EvtInfo_DTC_0x404212: start-on-event=DemSatellite_0InternalBehavior/GetDebouncingOfEvent, operation=EvtInfo_DTC_0x404212.GetDebouncingOfEvent
        OpEventGetDebouncingOfEvent_GetDebouncingOfEvent_EvtInfo_DTC_0x404213: start-on-event=DemSatellite_0InternalBehavior/GetDebouncingOfEvent, operation=EvtInfo_DTC_0x404213.GetDebouncingOfEvent
        OpEventGetDebouncingOfEvent_GetDebouncingOfEvent_EvtInfo_DTC_0x404012: start-on-event=DemSatellite_0InternalBehavior/GetDebouncingOfEvent, operation=EvtInfo_DTC_0x404012.GetDebouncingOfEvent
        OpEventGetDebouncingOfEvent_GetDebouncingOfEvent_EvtInfo_DTC_0x403121: start-on-event=DemSatellite_0InternalBehavior/GetDebouncingOfEvent, operation=EvtInfo_DTC_0x403121.GetDebouncingOfEvent
        OpEventGetDebouncingOfEvent_GetDebouncingOfEvent_EvtInfo_DTC_0x404211: start-on-event=DemSatellite_0InternalBehavior/GetDebouncingOfEvent, operation=EvtInfo_DTC_0x404211.GetDebouncingOfEvent
        OpEventGetDebouncingOfEvent_GetDebouncingOfEvent_EvtInfo_DTC_0x404013: start-on-event=DemSatellite_0InternalBehavior/GetDebouncingOfEvent, operation=EvtInfo_DTC_0x404013.GetDebouncingOfEvent
        OpEventGetDebouncingOfEvent_GetDebouncingOfEvent_EvtInfo_DTC_0x403122: start-on-event=DemSatellite_0InternalBehavior/GetDebouncingOfEvent, operation=EvtInfo_DTC_0x403122.GetDebouncingOfEvent
        OpEventGetDebouncingOfEvent_GetDebouncingOfEvent_EvtInfo_DTC_0x403a13: start-on-event=DemSatellite_0InternalBehavior/GetDebouncingOfEvent, operation=EvtInfo_DTC_0x403a13.GetDebouncingOfEvent
        OpEventGetMonitorStatus_GetMonitorStatus_EvtInfo_DTC_0x403413: start-on-event=DemSatellite_0InternalBehavior/GetMonitorStatus, operation=EvtInfo_DTC_0x403413.GetMonitorStatus
        OpEventGetMonitorStatus_GetMonitorStatus_EvtInfo_DTC_0x404428: start-on-event=DemSatellite_0InternalBehavior/GetMonitorStatus, operation=EvtInfo_DTC_0x404428.GetMonitorStatus
        OpEventGetMonitorStatus_GetMonitorStatus_EvtInfo_DTC_0x406321: start-on-event=DemSatellite_0InternalBehavior/GetMonitorStatus, operation=EvtInfo_DTC_0x406321.GetMonitorStatus
        OpEventGetMonitorStatus_GetMonitorStatus_EvtInfo_DTC_0x406325: start-on-event=DemSatellite_0InternalBehavior/GetMonitorStatus, operation=EvtInfo_DTC_0x406325.GetMonitorStatus
        OpEventGetMonitorStatus_GetMonitorStatus_EvtInfo_DTC_0x404421: start-on-event=DemSatellite_0InternalBehavior/GetMonitorStatus, operation=EvtInfo_DTC_0x404421.GetMonitorStatus
        OpEventGetMonitorStatus_GetMonitorStatus_EvtInfo_DTC_0x404422: start-on-event=DemSatellite_0InternalBehavior/GetMonitorStatus, operation=EvtInfo_DTC_0x404422.GetMonitorStatus
        OpEventGetMonitorStatus_GetMonitorStatus_EvtInfo_DTC_0x406322: start-on-event=DemSatellite_0InternalBehavior/GetMonitorStatus, operation=EvtInfo_DTC_0x406322.GetMonitorStatus
        OpEventGetMonitorStatus_GetMonitorStatus_EvtInfo_DTC_0x403a21: start-on-event=DemSatellite_0InternalBehavior/GetMonitorStatus, operation=EvtInfo_DTC_0x403a21.GetMonitorStatus
        OpEventGetMonitorStatus_GetMonitorStatus_EvtInfo_DTC_0x403a22: start-on-event=DemSatellite_0InternalBehavior/GetMonitorStatus, operation=EvtInfo_DTC_0x403a22.GetMonitorStatus
        OpEventGetMonitorStatus_GetMonitorStatus_EvtInfo_DTC_0x403422: start-on-event=DemSatellite_0InternalBehavior/GetMonitorStatus, operation=EvtInfo_DTC_0x403422.GetMonitorStatus
        OpEventGetMonitorStatus_GetMonitorStatus_EvtInfo_DTC_0x403421: start-on-event=DemSatellite_0InternalBehavior/GetMonitorStatus, operation=EvtInfo_DTC_0x403421.GetMonitorStatus
        OpEventGetMonitorStatus_GetMonitorStatus_EvtInfo_DTC_0x402013: start-on-event=DemSatellite_0InternalBehavior/GetMonitorStatus, operation=EvtInfo_DTC_0x402013.GetMonitorStatus
        OpEventGetMonitorStatus_GetMonitorStatus_EvtInfo_DTC_0x402012: start-on-event=DemSatellite_0InternalBehavior/GetMonitorStatus, operation=EvtInfo_DTC_0x402012.GetMonitorStatus
        OpEventGetMonitorStatus_GetMonitorStatus_EvtInfo_DTC_0x402025: start-on-event=DemSatellite_0InternalBehavior/GetMonitorStatus, operation=EvtInfo_DTC_0x402025.GetMonitorStatus
        OpEventGetMonitorStatus_GetMonitorStatus_EvtInfo_DTC_0x403713: start-on-event=DemSatellite_0InternalBehavior/GetMonitorStatus, operation=EvtInfo_DTC_0x403713.GetMonitorStatus
        OpEventGetMonitorStatus_GetMonitorStatus_EvtInfo_DTC_0x406222: start-on-event=DemSatellite_0InternalBehavior/GetMonitorStatus, operation=EvtInfo_DTC_0x406222.GetMonitorStatus
        OpEventGetMonitorStatus_GetMonitorStatus_EvtInfo_DTC_0x406221: start-on-event=DemSatellite_0InternalBehavior/GetMonitorStatus, operation=EvtInfo_DTC_0x406221.GetMonitorStatus
        OpEventGetMonitorStatus_GetMonitorStatus_EvtInfo_DTC_0x406225: start-on-event=DemSatellite_0InternalBehavior/GetMonitorStatus, operation=EvtInfo_DTC_0x406225.GetMonitorStatus
        OpEventGetMonitorStatus_GetMonitorStatus_EvtInfo_DTC_0x403113: start-on-event=DemSatellite_0InternalBehavior/GetMonitorStatus, operation=EvtInfo_DTC_0x403113.GetMonitorStatus
        OpEventGetMonitorStatus_GetMonitorStatus_EvtInfo_DTC_0x403721: start-on-event=DemSatellite_0InternalBehavior/GetMonitorStatus, operation=EvtInfo_DTC_0x403721.GetMonitorStatus
        OpEventGetMonitorStatus_GetMonitorStatus_EvtInfo_DTC_0x403722: start-on-event=DemSatellite_0InternalBehavior/GetMonitorStatus, operation=EvtInfo_DTC_0x403722.GetMonitorStatus
        OpEventGetMonitorStatus_GetMonitorStatus_EvtInfo_DTC_0x404011: start-on-event=DemSatellite_0InternalBehavior/GetMonitorStatus, operation=EvtInfo_DTC_0x404011.GetMonitorStatus
        OpEventGetMonitorStatus_GetMonitorStatus_EvtInfo_DTC_0x404212: start-on-event=DemSatellite_0InternalBehavior/GetMonitorStatus, operation=EvtInfo_DTC_0x404212.GetMonitorStatus
        OpEventGetMonitorStatus_GetMonitorStatus_EvtInfo_DTC_0x404213: start-on-event=DemSatellite_0InternalBehavior/GetMonitorStatus, operation=EvtInfo_DTC_0x404213.GetMonitorStatus
        OpEventGetMonitorStatus_GetMonitorStatus_EvtInfo_DTC_0x404012: start-on-event=DemSatellite_0InternalBehavior/GetMonitorStatus, operation=EvtInfo_DTC_0x404012.GetMonitorStatus
        OpEventGetMonitorStatus_GetMonitorStatus_EvtInfo_DTC_0x403121: start-on-event=DemSatellite_0InternalBehavior/GetMonitorStatus, operation=EvtInfo_DTC_0x403121.GetMonitorStatus
        OpEventGetMonitorStatus_GetMonitorStatus_EvtInfo_DTC_0x404211: start-on-event=DemSatellite_0InternalBehavior/GetMonitorStatus, operation=EvtInfo_DTC_0x404211.GetMonitorStatus
        OpEventGetMonitorStatus_GetMonitorStatus_EvtInfo_DTC_0x404013: start-on-event=DemSatellite_0InternalBehavior/GetMonitorStatus, operation=EvtInfo_DTC_0x404013.GetMonitorStatus
        OpEventGetMonitorStatus_GetMonitorStatus_EvtInfo_DTC_0x403122: start-on-event=DemSatellite_0InternalBehavior/GetMonitorStatus, operation=EvtInfo_DTC_0x403122.GetMonitorStatus
        OpEventGetMonitorStatus_GetMonitorStatus_EvtInfo_DTC_0x403a13: start-on-event=DemSatellite_0InternalBehavior/GetMonitorStatus, operation=EvtInfo_DTC_0x403a13.GetMonitorStatus
        OpEventSetEventStatus_SetEventStatus_Event_DTC_0x403413: start-on-event=SetEventStatus, operation=Event_DTC_0x403413.SetEventStatus
        OpEventSetEventStatus_SetEventStatus_Event_DTC_0x404428: start-on-event=SetEventStatus, operation=Event_DTC_0x404428.SetEventStatus
        OpEventSetEventStatus_SetEventStatus_Event_DTC_0x406321: start-on-event=SetEventStatus, operation=Event_DTC_0x406321.SetEventStatus
        OpEventSetEventStatus_SetEventStatus_Event_DTC_0x406325: start-on-event=SetEventStatus, operation=Event_DTC_0x406325.SetEventStatus
        OpEventSetEventStatus_SetEventStatus_Event_DTC_0x404421: start-on-event=SetEventStatus, operation=Event_DTC_0x404421.SetEventStatus
        OpEventSetEventStatus_SetEventStatus_Event_DTC_0x404422: start-on-event=SetEventStatus, operation=Event_DTC_0x404422.SetEventStatus
        OpEventSetEventStatus_SetEventStatus_Event_DTC_0x406322: start-on-event=SetEventStatus, operation=Event_DTC_0x406322.SetEventStatus
        OpEventSetEventStatus_SetEventStatus_Event_DTC_0x403a21: start-on-event=SetEventStatus, operation=Event_DTC_0x403a21.SetEventStatus
        OpEventSetEventStatus_SetEventStatus_Event_DTC_0x403a22: start-on-event=SetEventStatus, operation=Event_DTC_0x403a22.SetEventStatus
        OpEventSetEventStatus_SetEventStatus_Event_DTC_0x403422: start-on-event=SetEventStatus, operation=Event_DTC_0x403422.SetEventStatus
        OpEventSetEventStatus_SetEventStatus_Event_DTC_0x403421: start-on-event=SetEventStatus, operation=Event_DTC_0x403421.SetEventStatus
        OpEventSetEventStatus_SetEventStatus_Event_DTC_0x402013: start-on-event=SetEventStatus, operation=Event_DTC_0x402013.SetEventStatus
        OpEventSetEventStatus_SetEventStatus_Event_DTC_0x402012: start-on-event=SetEventStatus, operation=Event_DTC_0x402012.SetEventStatus
        OpEventSetEventStatus_SetEventStatus_Event_DTC_0x402025: start-on-event=SetEventStatus, operation=Event_DTC_0x402025.SetEventStatus
        OpEventSetEventStatus_SetEventStatus_Event_DTC_0x403713: start-on-event=SetEventStatus, operation=Event_DTC_0x403713.SetEventStatus
        OpEventSetEventStatus_SetEventStatus_Event_DTC_0x406222: start-on-event=SetEventStatus, operation=Event_DTC_0x406222.SetEventStatus
        OpEventSetEventStatus_SetEventStatus_Event_DTC_0x406221: start-on-event=SetEventStatus, operation=Event_DTC_0x406221.SetEventStatus
        OpEventSetEventStatus_SetEventStatus_Event_DTC_0x406225: start-on-event=SetEventStatus, operation=Event_DTC_0x406225.SetEventStatus
        OpEventSetEventStatus_SetEventStatus_Event_DTC_0x403113: start-on-event=SetEventStatus, operation=Event_DTC_0x403113.SetEventStatus
        OpEventSetEventStatus_SetEventStatus_Event_DTC_0x403721: start-on-event=SetEventStatus, operation=Event_DTC_0x403721.SetEventStatus
        OpEventSetEventStatus_SetEventStatus_Event_DTC_0x403722: start-on-event=SetEventStatus, operation=Event_DTC_0x403722.SetEventStatus
        OpEventSetEventStatus_SetEventStatus_Event_DTC_0x404011: start-on-event=SetEventStatus, operation=Event_DTC_0x404011.SetEventStatus
        OpEventSetEventStatus_SetEventStatus_Event_DTC_0x404212: start-on-event=SetEventStatus, operation=Event_DTC_0x404212.SetEventStatus
        OpEventSetEventStatus_SetEventStatus_Event_DTC_0x404213: start-on-event=SetEventStatus, operation=Event_DTC_0x404213.SetEventStatus
        OpEventSetEventStatus_SetEventStatus_Event_DTC_0x404012: start-on-event=SetEventStatus, operation=Event_DTC_0x404012.SetEventStatus
        OpEventSetEventStatus_SetEventStatus_Event_DTC_0x403121: start-on-event=SetEventStatus, operation=Event_DTC_0x403121.SetEventStatus
        OpEventSetEventStatus_SetEventStatus_Event_DTC_0x404211: start-on-event=SetEventStatus, operation=Event_DTC_0x404211.SetEventStatus
        OpEventSetEventStatus_SetEventStatus_Event_DTC_0x404013: start-on-event=SetEventStatus, operation=Event_DTC_0x404013.SetEventStatus
        OpEventSetEventStatus_SetEventStatus_Event_DTC_0x403122: start-on-event=SetEventStatus, operation=Event_DTC_0x403122.SetEventStatus
        OpEventSetEventStatus_SetEventStatus_Event_DTC_0x403a13: start-on-event=SetEventStatus, operation=Event_DTC_0x403a13.SetEventStatus
        OpEventResetEventStatus_ResetEventStatus_Event_DTC_0x403413: start-on-event=ResetEventStatus, operation=Event_DTC_0x403413.ResetEventStatus
        OpEventResetEventStatus_ResetEventStatus_Event_DTC_0x404428: start-on-event=ResetEventStatus, operation=Event_DTC_0x404428.ResetEventStatus
        OpEventResetEventStatus_ResetEventStatus_Event_DTC_0x406321: start-on-event=ResetEventStatus, operation=Event_DTC_0x406321.ResetEventStatus
        OpEventResetEventStatus_ResetEventStatus_Event_DTC_0x406325: start-on-event=ResetEventStatus, operation=Event_DTC_0x406325.ResetEventStatus
        OpEventResetEventStatus_ResetEventStatus_Event_DTC_0x404421: start-on-event=ResetEventStatus, operation=Event_DTC_0x404421.ResetEventStatus
        OpEventResetEventStatus_ResetEventStatus_Event_DTC_0x404422: start-on-event=ResetEventStatus, operation=Event_DTC_0x404422.ResetEventStatus
        OpEventResetEventStatus_ResetEventStatus_Event_DTC_0x406322: start-on-event=ResetEventStatus, operation=Event_DTC_0x406322.ResetEventStatus
        OpEventResetEventStatus_ResetEventStatus_Event_DTC_0x403a21: start-on-event=ResetEventStatus, operation=Event_DTC_0x403a21.ResetEventStatus
        OpEventResetEventStatus_ResetEventStatus_Event_DTC_0x403a22: start-on-event=ResetEventStatus, operation=Event_DTC_0x403a22.ResetEventStatus
        OpEventResetEventStatus_ResetEventStatus_Event_DTC_0x403422: start-on-event=ResetEventStatus, operation=Event_DTC_0x403422.ResetEventStatus
        OpEventResetEventStatus_ResetEventStatus_Event_DTC_0x403421: start-on-event=ResetEventStatus, operation=Event_DTC_0x403421.ResetEventStatus
        OpEventResetEventStatus_ResetEventStatus_Event_DTC_0x402013: start-on-event=ResetEventStatus, operation=Event_DTC_0x402013.ResetEventStatus
        OpEventResetEventStatus_ResetEventStatus_Event_DTC_0x402012: start-on-event=ResetEventStatus, operation=Event_DTC_0x402012.ResetEventStatus
        OpEventResetEventStatus_ResetEventStatus_Event_DTC_0x402025: start-on-event=ResetEventStatus, operation=Event_DTC_0x402025.ResetEventStatus
        OpEventResetEventStatus_ResetEventStatus_Event_DTC_0x403713: start-on-event=ResetEventStatus, operation=Event_DTC_0x403713.ResetEventStatus
        OpEventResetEventStatus_ResetEventStatus_Event_DTC_0x406222: start-on-event=ResetEventStatus, operation=Event_DTC_0x406222.ResetEventStatus
        OpEventResetEventStatus_ResetEventStatus_Event_DTC_0x406221: start-on-event=ResetEventStatus, operation=Event_DTC_0x406221.ResetEventStatus
        OpEventResetEventStatus_ResetEventStatus_Event_DTC_0x406225: start-on-event=ResetEventStatus, operation=Event_DTC_0x406225.ResetEventStatus
        OpEventResetEventStatus_ResetEventStatus_Event_DTC_0x403113: start-on-event=ResetEventStatus, operation=Event_DTC_0x403113.ResetEventStatus
        OpEventResetEventStatus_ResetEventStatus_Event_DTC_0x403721: start-on-event=ResetEventStatus, operation=Event_DTC_0x403721.ResetEventStatus
        OpEventResetEventStatus_ResetEventStatus_Event_DTC_0x403722: start-on-event=ResetEventStatus, operation=Event_DTC_0x403722.ResetEventStatus
        OpEventResetEventStatus_ResetEventStatus_Event_DTC_0x404011: start-on-event=ResetEventStatus, operation=Event_DTC_0x404011.ResetEventStatus
        OpEventResetEventStatus_ResetEventStatus_Event_DTC_0x404212: start-on-event=ResetEventStatus, operation=Event_DTC_0x404212.ResetEventStatus
        OpEventResetEventStatus_ResetEventStatus_Event_DTC_0x404213: start-on-event=ResetEventStatus, operation=Event_DTC_0x404213.ResetEventStatus
        OpEventResetEventStatus_ResetEventStatus_Event_DTC_0x404012: start-on-event=ResetEventStatus, operation=Event_DTC_0x404012.ResetEventStatus
        OpEventResetEventStatus_ResetEventStatus_Event_DTC_0x403121: start-on-event=ResetEventStatus, operation=Event_DTC_0x403121.ResetEventStatus
        OpEventResetEventStatus_ResetEventStatus_Event_DTC_0x404211: start-on-event=ResetEventStatus, operation=Event_DTC_0x404211.ResetEventStatus
        OpEventResetEventStatus_ResetEventStatus_Event_DTC_0x404013: start-on-event=ResetEventStatus, operation=Event_DTC_0x404013.ResetEventStatus
        OpEventResetEventStatus_ResetEventStatus_Event_DTC_0x403122: start-on-event=ResetEventStatus, operation=Event_DTC_0x403122.ResetEventStatus
        OpEventResetEventStatus_ResetEventStatus_Event_DTC_0x403a13: start-on-event=ResetEventStatus, operation=Event_DTC_0x403a13.ResetEventStatus
        OpEventResetEventDebounceStatus_ResetEventDebounceStatus_Event_DTC_0x403413: start-on-event=ResetEventDebounceStatus, operation=Event_DTC_0x403413.ResetEventDebounceStatus
        OpEventResetEventDebounceStatus_ResetEventDebounceStatus_Event_DTC_0x404428: start-on-event=ResetEventDebounceStatus, operation=Event_DTC_0x404428.ResetEventDebounceStatus
        OpEventResetEventDebounceStatus_ResetEventDebounceStatus_Event_DTC_0x406321: start-on-event=ResetEventDebounceStatus, operation=Event_DTC_0x406321.ResetEventDebounceStatus
        OpEventResetEventDebounceStatus_ResetEventDebounceStatus_Event_DTC_0x406325: start-on-event=ResetEventDebounceStatus, operation=Event_DTC_0x406325.ResetEventDebounceStatus
        OpEventResetEventDebounceStatus_ResetEventDebounceStatus_Event_DTC_0x404421: start-on-event=ResetEventDebounceStatus, operation=Event_DTC_0x404421.ResetEventDebounceStatus
        OpEventResetEventDebounceStatus_ResetEventDebounceStatus_Event_DTC_0x404422: start-on-event=ResetEventDebounceStatus, operation=Event_DTC_0x404422.ResetEventDebounceStatus
        OpEventResetEventDebounceStatus_ResetEventDebounceStatus_Event_DTC_0x406322: start-on-event=ResetEventDebounceStatus, operation=Event_DTC_0x406322.ResetEventDebounceStatus
        OpEventResetEventDebounceStatus_ResetEventDebounceStatus_Event_DTC_0x403a21: start-on-event=ResetEventDebounceStatus, operation=Event_DTC_0x403a21.ResetEventDebounceStatus
        OpEventResetEventDebounceStatus_ResetEventDebounceStatus_Event_DTC_0x403a22: start-on-event=ResetEventDebounceStatus, operation=Event_DTC_0x403a22.ResetEventDebounceStatus
        OpEventResetEventDebounceStatus_ResetEventDebounceStatus_Event_DTC_0x403422: start-on-event=ResetEventDebounceStatus, operation=Event_DTC_0x403422.ResetEventDebounceStatus
        OpEventResetEventDebounceStatus_ResetEventDebounceStatus_Event_DTC_0x403421: start-on-event=ResetEventDebounceStatus, operation=Event_DTC_0x403421.ResetEventDebounceStatus
        OpEventResetEventDebounceStatus_ResetEventDebounceStatus_Event_DTC_0x402013: start-on-event=ResetEventDebounceStatus, operation=Event_DTC_0x402013.ResetEventDebounceStatus
        OpEventResetEventDebounceStatus_ResetEventDebounceStatus_Event_DTC_0x402012: start-on-event=ResetEventDebounceStatus, operation=Event_DTC_0x402012.ResetEventDebounceStatus
        OpEventResetEventDebounceStatus_ResetEventDebounceStatus_Event_DTC_0x402025: start-on-event=ResetEventDebounceStatus, operation=Event_DTC_0x402025.ResetEventDebounceStatus
        OpEventResetEventDebounceStatus_ResetEventDebounceStatus_Event_DTC_0x403713: start-on-event=ResetEventDebounceStatus, operation=Event_DTC_0x403713.ResetEventDebounceStatus
        OpEventResetEventDebounceStatus_ResetEventDebounceStatus_Event_DTC_0x406222: start-on-event=ResetEventDebounceStatus, operation=Event_DTC_0x406222.ResetEventDebounceStatus
        OpEventResetEventDebounceStatus_ResetEventDebounceStatus_Event_DTC_0x406221: start-on-event=ResetEventDebounceStatus, operation=Event_DTC_0x406221.ResetEventDebounceStatus
        OpEventResetEventDebounceStatus_ResetEventDebounceStatus_Event_DTC_0x406225: start-on-event=ResetEventDebounceStatus, operation=Event_DTC_0x406225.ResetEventDebounceStatus
        OpEventResetEventDebounceStatus_ResetEventDebounceStatus_Event_DTC_0x403113: start-on-event=ResetEventDebounceStatus, operation=Event_DTC_0x403113.ResetEventDebounceStatus
        OpEventResetEventDebounceStatus_ResetEventDebounceStatus_Event_DTC_0x403721: start-on-event=ResetEventDebounceStatus, operation=Event_DTC_0x403721.ResetEventDebounceStatus
        OpEventResetEventDebounceStatus_ResetEventDebounceStatus_Event_DTC_0x403722: start-on-event=ResetEventDebounceStatus, operation=Event_DTC_0x403722.ResetEventDebounceStatus
        OpEventResetEventDebounceStatus_ResetEventDebounceStatus_Event_DTC_0x404011: start-on-event=ResetEventDebounceStatus, operation=Event_DTC_0x404011.ResetEventDebounceStatus
        OpEventResetEventDebounceStatus_ResetEventDebounceStatus_Event_DTC_0x404212: start-on-event=ResetEventDebounceStatus, operation=Event_DTC_0x404212.ResetEventDebounceStatus
        OpEventResetEventDebounceStatus_ResetEventDebounceStatus_Event_DTC_0x404213: start-on-event=ResetEventDebounceStatus, operation=Event_DTC_0x404213.ResetEventDebounceStatus
        OpEventResetEventDebounceStatus_ResetEventDebounceStatus_Event_DTC_0x404012: start-on-event=ResetEventDebounceStatus, operation=Event_DTC_0x404012.ResetEventDebounceStatus
        OpEventResetEventDebounceStatus_ResetEventDebounceStatus_Event_DTC_0x403121: start-on-event=ResetEventDebounceStatus, operation=Event_DTC_0x403121.ResetEventDebounceStatus
        OpEventResetEventDebounceStatus_ResetEventDebounceStatus_Event_DTC_0x404211: start-on-event=ResetEventDebounceStatus, operation=Event_DTC_0x404211.ResetEventDebounceStatus
        OpEventResetEventDebounceStatus_ResetEventDebounceStatus_Event_DTC_0x404013: start-on-event=ResetEventDebounceStatus, operation=Event_DTC_0x404013.ResetEventDebounceStatus
        OpEventResetEventDebounceStatus_ResetEventDebounceStatus_Event_DTC_0x403122: start-on-event=ResetEventDebounceStatus, operation=Event_DTC_0x403122.ResetEventDebounceStatus
        OpEventResetEventDebounceStatus_ResetEventDebounceStatus_Event_DTC_0x403a13: start-on-event=ResetEventDebounceStatus, operation=Event_DTC_0x403a13.ResetEventDebounceStatus
        OpEventGetEventUdsStatus_GetEventUdsStatus_EvtInfo_DTC_0x401003: start-on-event=DemSatellite_0InternalBehavior/GetEventUdsStatus, operation=EvtInfo_DTC_0x401003.GetEventUdsStatus
        OpEventGetEventUdsStatus_GetEventUdsStatus_EvtInfo_DTC_0x401001: start-on-event=DemSatellite_0InternalBehavior/GetEventUdsStatus, operation=EvtInfo_DTC_0x401001.GetEventUdsStatus
        OpEventGetEventUdsStatus_GetEventUdsStatus_Event_DTC_0x401001: start-on-event=DemSatellite_0InternalBehavior/GetEventUdsStatus, operation=Event_DTC_0x401001.GetEventUdsStatus
        OpEventGetEventStatus_GetEventStatus_EvtInfo_DTC_0x401003: start-on-event=DemSatellite_0InternalBehavior/GetEventStatus, operation=EvtInfo_DTC_0x401003.GetEventStatus
        OpEventGetEventStatus_GetEventStatus_EvtInfo_DTC_0x401001: start-on-event=DemSatellite_0InternalBehavior/GetEventStatus, operation=EvtInfo_DTC_0x401001.GetEventStatus
        OpEventGetEventStatus_GetEventStatus_Event_DTC_0x401001: start-on-event=DemSatellite_0InternalBehavior/GetEventStatus, operation=Event_DTC_0x401001.GetEventStatus
        OpEventGetEventFailed_GetEventFailed_EvtInfo_DTC_0x401003: start-on-event=DemSatellite_0InternalBehavior/GetEventFailed, operation=EvtInfo_DTC_0x401003.GetEventFailed
        OpEventGetEventFailed_GetEventFailed_EvtInfo_DTC_0x401001: start-on-event=DemSatellite_0InternalBehavior/GetEventFailed, operation=EvtInfo_DTC_0x401001.GetEventFailed
        OpEventGetEventFailed_GetEventFailed_Event_DTC_0x401001: start-on-event=DemSatellite_0InternalBehavior/GetEventFailed, operation=Event_DTC_0x401001.GetEventFailed
        OpEventGetEventTested_GetEventTested_EvtInfo_DTC_0x401003: start-on-event=DemSatellite_0InternalBehavior/GetEventTested, operation=EvtInfo_DTC_0x401003.GetEventTested
        OpEventGetEventTested_GetEventTested_EvtInfo_DTC_0x401001: start-on-event=DemSatellite_0InternalBehavior/GetEventTested, operation=EvtInfo_DTC_0x401001.GetEventTested
        OpEventGetEventTested_GetEventTested_Event_DTC_0x401001: start-on-event=DemSatellite_0InternalBehavior/GetEventTested, operation=Event_DTC_0x401001.GetEventTested
        OpEventGetDTCOfEvent_GetDTCOfEvent_EvtInfo_DTC_0x401003: start-on-event=DemSatellite_0InternalBehavior/GetDTCOfEvent, operation=EvtInfo_DTC_0x401003.GetDTCOfEvent
        OpEventGetDTCOfEvent_GetDTCOfEvent_EvtInfo_DTC_0x401001: start-on-event=DemSatellite_0InternalBehavior/GetDTCOfEvent, operation=EvtInfo_DTC_0x401001.GetDTCOfEvent
        OpEventGetDTCOfEvent_GetDTCOfEvent_Event_DTC_0x401001: start-on-event=DemSatellite_0InternalBehavior/GetDTCOfEvent, operation=Event_DTC_0x401001.GetDTCOfEvent
        OpEventGetFaultDetectionCounter_GetFaultDetectionCounter_EvtInfo_DTC_0x401003: start-on-event=DemSatellite_0InternalBehavior/GetFaultDetectionCounter, operation=EvtInfo_DTC_0x401003.GetFaultDetectionCounter
        OpEventGetFaultDetectionCounter_GetFaultDetectionCounter_EvtInfo_DTC_0x401001: start-on-event=DemSatellite_0InternalBehavior/GetFaultDetectionCounter, operation=EvtInfo_DTC_0x401001.GetFaultDetectionCounter
        OpEventGetFaultDetectionCounter_GetFaultDetectionCounter_Event_DTC_0x401001: start-on-event=DemSatellite_0InternalBehavior/GetFaultDetectionCounter, operation=Event_DTC_0x401001.GetFaultDetectionCounter
        OpEventGetEventFreezeFrameDataEx_GetEventFreezeFrameDataEx_EvtInfo_DTC_0x401003: start-on-event=DemSatellite_0InternalBehavior/GetEventFreezeFrameDataEx, operation=EvtInfo_DTC_0x401003.GetEventFreezeFrameDataEx
        OpEventGetEventFreezeFrameDataEx_GetEventFreezeFrameDataEx_EvtInfo_DTC_0x401001: start-on-event=DemSatellite_0InternalBehavior/GetEventFreezeFrameDataEx, operation=EvtInfo_DTC_0x401001.GetEventFreezeFrameDataEx
        OpEventGetEventFreezeFrameDataEx_GetEventFreezeFrameDataEx_Event_DTC_0x401001: start-on-event=DemSatellite_0InternalBehavior/GetEventFreezeFrameDataEx, operation=Event_DTC_0x401001.GetEventFreezeFrameDataEx
        OpEventGetEventExtendedDataRecordEx_GetEventExtendedDataRecordEx_EvtInfo_DTC_0x401003: start-on-event=DemSatellite_0InternalBehavior/GetEventExtendedDataRecordEx, operation=EvtInfo_DTC_0x401003.GetEventExtendedDataRecordEx
        OpEventGetEventExtendedDataRecordEx_GetEventExtendedDataRecordEx_EvtInfo_DTC_0x401001: start-on-event=DemSatellite_0InternalBehavior/GetEventExtendedDataRecordEx, operation=EvtInfo_DTC_0x401001.GetEventExtendedDataRecordEx
        OpEventGetEventExtendedDataRecordEx_GetEventExtendedDataRecordEx_Event_DTC_0x401001: start-on-event=DemSatellite_0InternalBehavior/GetEventExtendedDataRecordEx, operation=Event_DTC_0x401001.GetEventExtendedDataRecordEx
        OpEventGetEventEnableCondition_GetEventEnableCondition_EvtInfo_DTC_0x401003: start-on-event=DemSatellite_0InternalBehavior/GetEventEnableCondition, operation=EvtInfo_DTC_0x401003.GetEventEnableCondition
        OpEventGetEventEnableCondition_GetEventEnableCondition_EvtInfo_DTC_0x401001: start-on-event=DemSatellite_0InternalBehavior/GetEventEnableCondition, operation=EvtInfo_DTC_0x401001.GetEventEnableCondition
        OpEventGetDebouncingOfEvent_GetDebouncingOfEvent_EvtInfo_DTC_0x401003: start-on-event=DemSatellite_0InternalBehavior/GetDebouncingOfEvent, operation=EvtInfo_DTC_0x401003.GetDebouncingOfEvent
        OpEventGetDebouncingOfEvent_GetDebouncingOfEvent_EvtInfo_DTC_0x401001: start-on-event=DemSatellite_0InternalBehavior/GetDebouncingOfEvent, operation=EvtInfo_DTC_0x401001.GetDebouncingOfEvent
        OpEventGetMonitorStatus_GetMonitorStatus_EvtInfo_DTC_0x401003: start-on-event=DemSatellite_0InternalBehavior/GetMonitorStatus, operation=EvtInfo_DTC_0x401003.GetMonitorStatus
        OpEventGetMonitorStatus_GetMonitorStatus_EvtInfo_DTC_0x401001: start-on-event=DemSatellite_0InternalBehavior/GetMonitorStatus, operation=EvtInfo_DTC_0x401001.GetMonitorStatus
        OpEventSetEventStatus_SetEventStatus_Event_DTC_0x401001: start-on-event=SetEventStatus, operation=Event_DTC_0x401001.SetEventStatus
        OpEventResetEventStatus_ResetEventStatus_Event_DTC_0x401001: start-on-event=ResetEventStatus, operation=Event_DTC_0x401001.ResetEventStatus
        OpEventResetEventDebounceStatus_ResetEventDebounceStatus_Event_DTC_0x401001: start-on-event=ResetEventDebounceStatus, operation=Event_DTC_0x401001.ResetEventDebounceStatus
        OpEventGetEventUdsStatus_GetEventUdsStatus_Event_DTC_0x401003: start-on-event=DemSatellite_0InternalBehavior/GetEventUdsStatus, operation=Event_DTC_0x401003.GetEventUdsStatus
        OpEventGetEventStatus_GetEventStatus_Event_DTC_0x401003: start-on-event=DemSatellite_0InternalBehavior/GetEventStatus, operation=Event_DTC_0x401003.GetEventStatus
        OpEventGetEventFailed_GetEventFailed_Event_DTC_0x401003: start-on-event=DemSatellite_0InternalBehavior/GetEventFailed, operation=Event_DTC_0x401003.GetEventFailed
        OpEventGetEventTested_GetEventTested_Event_DTC_0x401003: start-on-event=DemSatellite_0InternalBehavior/GetEventTested, operation=Event_DTC_0x401003.GetEventTested
        OpEventGetDTCOfEvent_GetDTCOfEvent_Event_DTC_0x401003: start-on-event=DemSatellite_0InternalBehavior/GetDTCOfEvent, operation=Event_DTC_0x401003.GetDTCOfEvent
        OpEventGetFaultDetectionCounter_GetFaultDetectionCounter_Event_DTC_0x401003: start-on-event=DemSatellite_0InternalBehavior/GetFaultDetectionCounter, operation=Event_DTC_0x401003.GetFaultDetectionCounter
        OpEventGetEventFreezeFrameDataEx_GetEventFreezeFrameDataEx_Event_DTC_0x401003: start-on-event=DemSatellite_0InternalBehavior/GetEventFreezeFrameDataEx, operation=Event_DTC_0x401003.GetEventFreezeFrameDataEx
        OpEventGetEventExtendedDataRecordEx_GetEventExtendedDataRecordEx_Event_DTC_0x401003: start-on-event=DemSatellite_0InternalBehavior/GetEventExtendedDataRecordEx, operation=Event_DTC_0x401003.GetEventExtendedDataRecordEx
        OpEventSetEventStatus_SetEventStatus_Event_DTC_0x401003: start-on-event=SetEventStatus, operation=Event_DTC_0x401003.SetEventStatus
        OpEventResetEventStatus_ResetEventStatus_Event_DTC_0x401003: start-on-event=ResetEventStatus, operation=Event_DTC_0x401003.ResetEventStatus
        OpEventResetEventDebounceStatus_ResetEventDebounceStatus_Event_DTC_0x401003: start-on-event=ResetEventDebounceStatus, operation=Event_DTC_0x401003.ResetEventDebounceStatus
        OpEventGetEventUdsStatus_GetEventUdsStatus_EvtInfo_DTC_0x402001: start-on-event=DemSatellite_0InternalBehavior/GetEventUdsStatus, operation=EvtInfo_DTC_0x402001.GetEventUdsStatus
        OpEventGetEventUdsStatus_GetEventUdsStatus_Event_DTC_0x402001: start-on-event=DemSatellite_0InternalBehavior/GetEventUdsStatus, operation=Event_DTC_0x402001.GetEventUdsStatus
        OpEventGetEventUdsStatus_GetEventUdsStatus_EvtInfo_DTC_0x403001: start-on-event=DemSatellite_0InternalBehavior/GetEventUdsStatus, operation=EvtInfo_DTC_0x403001.GetEventUdsStatus
        OpEventGetEventUdsStatus_GetEventUdsStatus_Event_DTC_0x403001: start-on-event=DemSatellite_0InternalBehavior/GetEventUdsStatus, operation=Event_DTC_0x403001.GetEventUdsStatus
        OpEventGetEventStatus_GetEventStatus_EvtInfo_DTC_0x402001: start-on-event=DemSatellite_0InternalBehavior/GetEventStatus, operation=EvtInfo_DTC_0x402001.GetEventStatus
        OpEventGetEventStatus_GetEventStatus_Event_DTC_0x402001: start-on-event=DemSatellite_0InternalBehavior/GetEventStatus, operation=Event_DTC_0x402001.GetEventStatus
        OpEventGetEventStatus_GetEventStatus_EvtInfo_DTC_0x403001: start-on-event=DemSatellite_0InternalBehavior/GetEventStatus, operation=EvtInfo_DTC_0x403001.GetEventStatus
        OpEventGetEventStatus_GetEventStatus_Event_DTC_0x403001: start-on-event=DemSatellite_0InternalBehavior/GetEventStatus, operation=Event_DTC_0x403001.GetEventStatus
        OpEventGetEventFailed_GetEventFailed_EvtInfo_DTC_0x402001: start-on-event=DemSatellite_0InternalBehavior/GetEventFailed, operation=EvtInfo_DTC_0x402001.GetEventFailed
        OpEventGetEventFailed_GetEventFailed_Event_DTC_0x402001: start-on-event=DemSatellite_0InternalBehavior/GetEventFailed, operation=Event_DTC_0x402001.GetEventFailed
        OpEventGetEventFailed_GetEventFailed_EvtInfo_DTC_0x403001: start-on-event=DemSatellite_0InternalBehavior/GetEventFailed, operation=EvtInfo_DTC_0x403001.GetEventFailed
        OpEventGetEventFailed_GetEventFailed_Event_DTC_0x403001: start-on-event=DemSatellite_0InternalBehavior/GetEventFailed, operation=Event_DTC_0x403001.GetEventFailed
        OpEventGetEventTested_GetEventTested_EvtInfo_DTC_0x402001: start-on-event=DemSatellite_0InternalBehavior/GetEventTested, operation=EvtInfo_DTC_0x402001.GetEventTested
        OpEventGetEventTested_GetEventTested_Event_DTC_0x402001: start-on-event=DemSatellite_0InternalBehavior/GetEventTested, operation=Event_DTC_0x402001.GetEventTested
        OpEventGetEventTested_GetEventTested_EvtInfo_DTC_0x403001: start-on-event=DemSatellite_0InternalBehavior/GetEventTested, operation=EvtInfo_DTC_0x403001.GetEventTested
        OpEventGetEventTested_GetEventTested_Event_DTC_0x403001: start-on-event=DemSatellite_0InternalBehavior/GetEventTested, operation=Event_DTC_0x403001.GetEventTested
        OpEventGetDTCOfEvent_GetDTCOfEvent_EvtInfo_DTC_0x402001: start-on-event=DemSatellite_0InternalBehavior/GetDTCOfEvent, operation=EvtInfo_DTC_0x402001.GetDTCOfEvent
        OpEventGetDTCOfEvent_GetDTCOfEvent_Event_DTC_0x402001: start-on-event=DemSatellite_0InternalBehavior/GetDTCOfEvent, operation=Event_DTC_0x402001.GetDTCOfEvent
        OpEventGetDTCOfEvent_GetDTCOfEvent_EvtInfo_DTC_0x403001: start-on-event=DemSatellite_0InternalBehavior/GetDTCOfEvent, operation=EvtInfo_DTC_0x403001.GetDTCOfEvent
        OpEventGetDTCOfEvent_GetDTCOfEvent_Event_DTC_0x403001: start-on-event=DemSatellite_0InternalBehavior/GetDTCOfEvent, operation=Event_DTC_0x403001.GetDTCOfEvent
        OpEventGetFaultDetectionCounter_GetFaultDetectionCounter_EvtInfo_DTC_0x402001: start-on-event=DemSatellite_0InternalBehavior/GetFaultDetectionCounter, operation=EvtInfo_DTC_0x402001.GetFaultDetectionCounter
        OpEventGetFaultDetectionCounter_GetFaultDetectionCounter_Event_DTC_0x402001: start-on-event=DemSatellite_0InternalBehavior/GetFaultDetectionCounter, operation=Event_DTC_0x402001.GetFaultDetectionCounter
        OpEventGetFaultDetectionCounter_GetFaultDetectionCounter_EvtInfo_DTC_0x403001: start-on-event=DemSatellite_0InternalBehavior/GetFaultDetectionCounter, operation=EvtInfo_DTC_0x403001.GetFaultDetectionCounter
        OpEventGetFaultDetectionCounter_GetFaultDetectionCounter_Event_DTC_0x403001: start-on-event=DemSatellite_0InternalBehavior/GetFaultDetectionCounter, operation=Event_DTC_0x403001.GetFaultDetectionCounter
        OpEventGetEventFreezeFrameDataEx_GetEventFreezeFrameDataEx_EvtInfo_DTC_0x402001: start-on-event=DemSatellite_0InternalBehavior/GetEventFreezeFrameDataEx, operation=EvtInfo_DTC_0x402001.GetEventFreezeFrameDataEx
        OpEventGetEventFreezeFrameDataEx_GetEventFreezeFrameDataEx_Event_DTC_0x402001: start-on-event=DemSatellite_0InternalBehavior/GetEventFreezeFrameDataEx, operation=Event_DTC_0x402001.GetEventFreezeFrameDataEx
        OpEventGetEventFreezeFrameDataEx_GetEventFreezeFrameDataEx_EvtInfo_DTC_0x403001: start-on-event=DemSatellite_0InternalBehavior/GetEventFreezeFrameDataEx, operation=EvtInfo_DTC_0x403001.GetEventFreezeFrameDataEx
        OpEventGetEventFreezeFrameDataEx_GetEventFreezeFrameDataEx_Event_DTC_0x403001: start-on-event=DemSatellite_0InternalBehavior/GetEventFreezeFrameDataEx, operation=Event_DTC_0x403001.GetEventFreezeFrameDataEx
        OpEventGetEventExtendedDataRecordEx_GetEventExtendedDataRecordEx_EvtInfo_DTC_0x402001: start-on-event=DemSatellite_0InternalBehavior/GetEventExtendedDataRecordEx, operation=EvtInfo_DTC_0x402001.GetEventExtendedDataRecordEx
        OpEventGetEventExtendedDataRecordEx_GetEventExtendedDataRecordEx_Event_DTC_0x402001: start-on-event=DemSatellite_0InternalBehavior/GetEventExtendedDataRecordEx, operation=Event_DTC_0x402001.GetEventExtendedDataRecordEx
        OpEventGetEventExtendedDataRecordEx_GetEventExtendedDataRecordEx_EvtInfo_DTC_0x403001: start-on-event=DemSatellite_0InternalBehavior/GetEventExtendedDataRecordEx, operation=EvtInfo_DTC_0x403001.GetEventExtendedDataRecordEx
        OpEventGetEventExtendedDataRecordEx_GetEventExtendedDataRecordEx_Event_DTC_0x403001: start-on-event=DemSatellite_0InternalBehavior/GetEventExtendedDataRecordEx, operation=Event_DTC_0x403001.GetEventExtendedDataRecordEx
        OpEventGetEventEnableCondition_GetEventEnableCondition_EvtInfo_DTC_0x402001: start-on-event=DemSatellite_0InternalBehavior/GetEventEnableCondition, operation=EvtInfo_DTC_0x402001.GetEventEnableCondition
        OpEventGetEventEnableCondition_GetEventEnableCondition_EvtInfo_DTC_0x403001: start-on-event=DemSatellite_0InternalBehavior/GetEventEnableCondition, operation=EvtInfo_DTC_0x403001.GetEventEnableCondition
        OpEventGetDebouncingOfEvent_GetDebouncingOfEvent_EvtInfo_DTC_0x402001: start-on-event=DemSatellite_0InternalBehavior/GetDebouncingOfEvent, operation=EvtInfo_DTC_0x402001.GetDebouncingOfEvent
        OpEventGetDebouncingOfEvent_GetDebouncingOfEvent_EvtInfo_DTC_0x403001: start-on-event=DemSatellite_0InternalBehavior/GetDebouncingOfEvent, operation=EvtInfo_DTC_0x403001.GetDebouncingOfEvent
        OpEventGetMonitorStatus_GetMonitorStatus_EvtInfo_DTC_0x402001: start-on-event=DemSatellite_0InternalBehavior/GetMonitorStatus, operation=EvtInfo_DTC_0x402001.GetMonitorStatus
        OpEventGetMonitorStatus_GetMonitorStatus_EvtInfo_DTC_0x403001: start-on-event=DemSatellite_0InternalBehavior/GetMonitorStatus, operation=EvtInfo_DTC_0x403001.GetMonitorStatus
        OpEventSetEventStatus_SetEventStatus_Event_DTC_0x402001: start-on-event=SetEventStatus, operation=Event_DTC_0x402001.SetEventStatus
        OpEventSetEventStatus_SetEventStatus_Event_DTC_0x403001: start-on-event=SetEventStatus, operation=Event_DTC_0x403001.SetEventStatus
        OpEventResetEventStatus_ResetEventStatus_Event_DTC_0x402001: start-on-event=ResetEventStatus, operation=Event_DTC_0x402001.ResetEventStatus
        OpEventResetEventStatus_ResetEventStatus_Event_DTC_0x403001: start-on-event=ResetEventStatus, operation=Event_DTC_0x403001.ResetEventStatus
        OpEventResetEventDebounceStatus_ResetEventDebounceStatus_Event_DTC_0x402001: start-on-event=ResetEventDebounceStatus, operation=Event_DTC_0x402001.ResetEventDebounceStatus
        OpEventResetEventDebounceStatus_ResetEventDebounceStatus_Event_DTC_0x403001: start-on-event=ResetEventDebounceStatus, operation=Event_DTC_0x403001.ResetEventDebounceStatus
      port-api-options:
        {enable-take-address=true, indirect-api=false, port-defined-argument-value{value=1, value-type=Dem_EventIdType}, port=EvtInfo_DTC_0x402011}
        {enable-take-address=true, indirect-api=false, port-defined-argument-value{value=1, value-type=Dem_EventIdType}, port=Event_DTC_0x402011}
        enable-take-address=true, indirect-api=false, port=DemSatellite_0/GeneralEvtInfo
        {enable-take-address=true, indirect-api=false, port-defined-argument-value{value=11, value-type=Dem_EventIdType}, port=EvtInfo_DTC_0x403413}
        {enable-take-address=true, indirect-api=false, port-defined-argument-value{value=11, value-type=Dem_EventIdType}, port=Event_DTC_0x403413}
        {enable-take-address=true, indirect-api=false, port-defined-argument-value{value=25, value-type=Dem_EventIdType}, port=EvtInfo_DTC_0x404428}
        {enable-take-address=true, indirect-api=false, port-defined-argument-value{value=25, value-type=Dem_EventIdType}, port=Event_DTC_0x404428}
        {enable-take-address=true, indirect-api=false, port-defined-argument-value{value=29, value-type=Dem_EventIdType}, port=EvtInfo_DTC_0x406321}
        {enable-take-address=true, indirect-api=false, port-defined-argument-value{value=29, value-type=Dem_EventIdType}, port=Event_DTC_0x406321}
        {enable-take-address=true, indirect-api=false, port-defined-argument-value{value=31, value-type=Dem_EventIdType}, port=EvtInfo_DTC_0x406325}
        {enable-take-address=true, indirect-api=false, port-defined-argument-value{value=31, value-type=Dem_EventIdType}, port=Event_DTC_0x406325}
        {enable-take-address=true, indirect-api=false, port-defined-argument-value{value=23, value-type=Dem_EventIdType}, port=EvtInfo_DTC_0x404421}
        {enable-take-address=true, indirect-api=false, port-defined-argument-value{value=23, value-type=Dem_EventIdType}, port=Event_DTC_0x404421}
        {enable-take-address=true, indirect-api=false, port-defined-argument-value{value=24, value-type=Dem_EventIdType}, port=EvtInfo_DTC_0x404422}
        {enable-take-address=true, indirect-api=false, port-defined-argument-value{value=24, value-type=Dem_EventIdType}, port=Event_DTC_0x404422}
        {enable-take-address=true, indirect-api=false, port-defined-argument-value{value=30, value-type=Dem_EventIdType}, port=EvtInfo_DTC_0x406322}
        {enable-take-address=true, indirect-api=false, port-defined-argument-value{value=30, value-type=Dem_EventIdType}, port=Event_DTC_0x406322}
        {enable-take-address=true, indirect-api=false, port-defined-argument-value{value=3, value-type=Dem_EventIdType}, port=EvtInfo_DTC_0x403a21}
        {enable-take-address=true, indirect-api=false, port-defined-argument-value{value=3, value-type=Dem_EventIdType}, port=Event_DTC_0x403a21}
        {enable-take-address=true, indirect-api=false, port-defined-argument-value{value=4, value-type=Dem_EventIdType}, port=EvtInfo_DTC_0x403a22}
        {enable-take-address=true, indirect-api=false, port-defined-argument-value{value=4, value-type=Dem_EventIdType}, port=Event_DTC_0x403a22}
        {enable-take-address=true, indirect-api=false, port-defined-argument-value{value=13, value-type=Dem_EventIdType}, port=EvtInfo_DTC_0x403422}
        {enable-take-address=true, indirect-api=false, port-defined-argument-value{value=13, value-type=Dem_EventIdType}, port=Event_DTC_0x403422}
        {enable-take-address=true, indirect-api=false, port-defined-argument-value{value=12, value-type=Dem_EventIdType}, port=EvtInfo_DTC_0x403421}
        {enable-take-address=true, indirect-api=false, port-defined-argument-value{value=12, value-type=Dem_EventIdType}, port=Event_DTC_0x403421}
        {enable-take-address=true, indirect-api=false, port-defined-argument-value{value=6, value-type=Dem_EventIdType}, port=EvtInfo_DTC_0x402013}
        {enable-take-address=true, indirect-api=false, port-defined-argument-value{value=6, value-type=Dem_EventIdType}, port=Event_DTC_0x402013}
        {enable-take-address=true, indirect-api=false, port-defined-argument-value{value=5, value-type=Dem_EventIdType}, port=EvtInfo_DTC_0x402012}
        {enable-take-address=true, indirect-api=false, port-defined-argument-value{value=5, value-type=Dem_EventIdType}, port=Event_DTC_0x402012}
        {enable-take-address=true, indirect-api=false, port-defined-argument-value{value=7, value-type=Dem_EventIdType}, port=EvtInfo_DTC_0x402025}
        {enable-take-address=true, indirect-api=false, port-defined-argument-value{value=7, value-type=Dem_EventIdType}, port=Event_DTC_0x402025}
        {enable-take-address=true, indirect-api=false, port-defined-argument-value{value=14, value-type=Dem_EventIdType}, port=EvtInfo_DTC_0x403713}
        {enable-take-address=true, indirect-api=false, port-defined-argument-value{value=14, value-type=Dem_EventIdType}, port=Event_DTC_0x403713}
        {enable-take-address=true, indirect-api=false, port-defined-argument-value{value=27, value-type=Dem_EventIdType}, port=EvtInfo_DTC_0x406222}
        {enable-take-address=true, indirect-api=false, port-defined-argument-value{value=27, value-type=Dem_EventIdType}, port=Event_DTC_0x406222}
        {enable-take-address=true, indirect-api=false, port-defined-argument-value{value=26, value-type=Dem_EventIdType}, port=EvtInfo_DTC_0x406221}
        {enable-take-address=true, indirect-api=false, port-defined-argument-value{value=26, value-type=Dem_EventIdType}, port=Event_DTC_0x406221}
        {enable-take-address=true, indirect-api=false, port-defined-argument-value{value=28, value-type=Dem_EventIdType}, port=EvtInfo_DTC_0x406225}
        {enable-take-address=true, indirect-api=false, port-defined-argument-value{value=28, value-type=Dem_EventIdType}, port=Event_DTC_0x406225}
        {enable-take-address=true, indirect-api=false, port-defined-argument-value{value=8, value-type=Dem_EventIdType}, port=EvtInfo_DTC_0x403113}
        {enable-take-address=true, indirect-api=false, port-defined-argument-value{value=8, value-type=Dem_EventIdType}, port=Event_DTC_0x403113}
        {enable-take-address=true, indirect-api=false, port-defined-argument-value{value=15, value-type=Dem_EventIdType}, port=EvtInfo_DTC_0x403721}
        {enable-take-address=true, indirect-api=false, port-defined-argument-value{value=15, value-type=Dem_EventIdType}, port=Event_DTC_0x403721}
        {enable-take-address=true, indirect-api=false, port-defined-argument-value{value=16, value-type=Dem_EventIdType}, port=EvtInfo_DTC_0x403722}
        {enable-take-address=true, indirect-api=false, port-defined-argument-value{value=16, value-type=Dem_EventIdType}, port=Event_DTC_0x403722}
        {enable-take-address=true, indirect-api=false, port-defined-argument-value{value=17, value-type=Dem_EventIdType}, port=EvtInfo_DTC_0x404011}
        {enable-take-address=true, indirect-api=false, port-defined-argument-value{value=17, value-type=Dem_EventIdType}, port=Event_DTC_0x404011}
        {enable-take-address=true, indirect-api=false, port-defined-argument-value{value=21, value-type=Dem_EventIdType}, port=EvtInfo_DTC_0x404212}
        {enable-take-address=true, indirect-api=false, port-defined-argument-value{value=21, value-type=Dem_EventIdType}, port=Event_DTC_0x404212}
        {enable-take-address=true, indirect-api=false, port-defined-argument-value{value=22, value-type=Dem_EventIdType}, port=EvtInfo_DTC_0x404213}
        {enable-take-address=true, indirect-api=false, port-defined-argument-value{value=22, value-type=Dem_EventIdType}, port=Event_DTC_0x404213}
        {enable-take-address=true, indirect-api=false, port-defined-argument-value{value=18, value-type=Dem_EventIdType}, port=EvtInfo_DTC_0x404012}
        {enable-take-address=true, indirect-api=false, port-defined-argument-value{value=18, value-type=Dem_EventIdType}, port=Event_DTC_0x404012}
        {enable-take-address=true, indirect-api=false, port-defined-argument-value{value=9, value-type=Dem_EventIdType}, port=EvtInfo_DTC_0x403121}
        {enable-take-address=true, indirect-api=false, port-defined-argument-value{value=9, value-type=Dem_EventIdType}, port=Event_DTC_0x403121}
        {enable-take-address=true, indirect-api=false, port-defined-argument-value{value=20, value-type=Dem_EventIdType}, port=EvtInfo_DTC_0x404211}
        {enable-take-address=true, indirect-api=false, port-defined-argument-value{value=20, value-type=Dem_EventIdType}, port=Event_DTC_0x404211}
        {enable-take-address=true, indirect-api=false, port-defined-argument-value{value=19, value-type=Dem_EventIdType}, port=EvtInfo_DTC_0x404013}
        {enable-take-address=true, indirect-api=false, port-defined-argument-value{value=19, value-type=Dem_EventIdType}, port=Event_DTC_0x404013}
        {enable-take-address=true, indirect-api=false, port-defined-argument-value{value=10, value-type=Dem_EventIdType}, port=EvtInfo_DTC_0x403122}
        {enable-take-address=true, indirect-api=false, port-defined-argument-value{value=10, value-type=Dem_EventIdType}, port=Event_DTC_0x403122}
        {enable-take-address=true, indirect-api=false, port-defined-argument-value{value=2, value-type=Dem_EventIdType}, port=EvtInfo_DTC_0x403a13}
        {enable-take-address=true, indirect-api=false, port-defined-argument-value{value=2, value-type=Dem_EventIdType}, port=Event_DTC_0x403a13}
        enable-take-address=true, indirect-api=false, port=DemSatellite_0/CBReadData_UncompletedTestCounters_Driving_Cycles_Since_Last_Completed
        enable-take-address=true, indirect-api=false, port=DemSatellite_0/CBReadData_DID_0x10d_Valve_Voltage_RL
        enable-take-address=true, indirect-api=false, port=DemSatellite_0/CBReadData_DID_0x10a_Wheel_Voltage_RL
        enable-take-address=true, indirect-api=false, port=DemSatellite_0/CBReadData_DID_0x107_Voltage_ECU
        enable-take-address=true, indirect-api=false, port=DemSatellite_0/CBReadData_DID_0x10d_Valve_Voltage_RR
        enable-take-address=true, indirect-api=false, port=DemSatellite_0/CBReadData_DTCAgingCounter_Driving_Cycles_Since_Last_Failed
        enable-take-address=true, indirect-api=false, port=DemSatellite_0/CBReadData_DID_0x10d_Valve_Status_FR
        enable-take-address=true, indirect-api=false, port=DemSatellite_0/CBReadData_DID_0x10a_Wheel_Voltage_RR
        enable-take-address=true, indirect-api=false, port=DemSatellite_0/CBReadData_DID_0x10a_Wheel_Voltage_FR
        enable-take-address=true, indirect-api=false, port=DemSatellite_0/CBReadData_DID_0x10a_Wheel_Voltage_FL
        enable-take-address=true, indirect-api=false, port=DemSatellite_0/CBReadData_DID_0x10d_Valve_Status_RR
        enable-take-address=true, indirect-api=false, port=DemSatellite_0/CBReadData_DID_0x10a_Wheel_Speed_RL
        enable-take-address=true, indirect-api=false, port=DemSatellite_0/CBReadData_DID_0x10a_Wheel_Speed_RR
        enable-take-address=true, indirect-api=false, port=DemSatellite_0/CBReadData_DID_0x10a_Wheel_Speed_FL
        enable-take-address=true, indirect-api=false, port=DemSatellite_0/CBReadData_DID_0x10d_Valve_Status_FL
        enable-take-address=true, indirect-api=false, port=DemSatellite_0/CBReadData_DID_0x10a_Direction_of_rotation
        enable-take-address=true, indirect-api=false, port=DemSatellite_0/CBReadData_DID_0x10d_Valve_Voltage_FL
        enable-take-address=true, indirect-api=false, port=DemSatellite_0/CBReadData_DID_0x10a_Wheel_Speed_FR
        enable-take-address=true, indirect-api=false, port=DemSatellite_0/CBReadData_DID_0x10d_Valve_Voltage_FR
        enable-take-address=true, indirect-api=false, port=DemSatellite_0/CBReadData_OccurrenceCounter_Driving_Cycles_Since_Test_Failed
        enable-take-address=true, indirect-api=false, port=DemSatellite_0/CBReadData_DID_0x10d_Valve_Status_RL
        {enable-take-address=true, indirect-api=false, port-defined-argument-value{value=33, value-type=Dem_EventIdType}, port=EvtInfo_DTC_0x401003}
        {enable-take-address=true, indirect-api=false, port-defined-argument-value{value=32, value-type=Dem_EventIdType}, port=EvtInfo_DTC_0x401001}
        {enable-take-address=true, indirect-api=false, port-defined-argument-value{value=32, value-type=Dem_EventIdType}, port=Event_DTC_0x401001}
        {enable-take-address=true, indirect-api=false, port-defined-argument-value{value=33, value-type=Dem_EventIdType}, port=Event_DTC_0x401003}
        {enable-take-address=true, indirect-api=false, port-defined-argument-value{value=34, value-type=Dem_EventIdType}, port=EvtInfo_DTC_0x402001}
        {enable-take-address=true, indirect-api=false, port-defined-argument-value{value=34, value-type=Dem_EventIdType}, port=Event_DTC_0x402001}
        {enable-take-address=true, indirect-api=false, port-defined-argument-value{value=35, value-type=Dem_EventIdType}, port=EvtInfo_DTC_0x403001}
        {enable-take-address=true, indirect-api=false, port-defined-argument-value{value=35, value-type=Dem_EventIdType}, port=Event_DTC_0x403001}
      15 x runnable:
        Dem_SatelliteMainFunction
          21 x sync call, all with timeout=0:
            OpServerCallDem_SatelliteMainFunction_ReadData_CBReadData_UncompletedTestCounters_Driving_Cycles_Since_Last_Completed: operation=CBReadData_UncompletedTestCounters_Driving_Cycles_Since_Last_Completed.ReadData
            OpServerCallDem_SatelliteMainFunction_ReadData_CBReadData_DID_0x10d_Valve_Voltage_RL: operation=CBReadData_DID_0x10d_Valve_Voltage_RL.ReadData
            OpServerCallDem_SatelliteMainFunction_ReadData_CBReadData_DID_0x10a_Wheel_Voltage_RL: operation=CBReadData_DID_0x10a_Wheel_Voltage_RL.ReadData
            OpServerCallDem_SatelliteMainFunction_ReadData_CBReadData_DID_0x107_Voltage_ECU: operation=CBReadData_DID_0x107_Voltage_ECU.ReadData
            OpServerCallDem_SatelliteMainFunction_ReadData_CBReadData_DID_0x10d_Valve_Voltage_RR: operation=CBReadData_DID_0x10d_Valve_Voltage_RR.ReadData
            OpServerCallDem_SatelliteMainFunction_ReadData_CBReadData_DTCAgingCounter_Driving_Cycles_Since_Last_Failed: operation=CBReadData_DTCAgingCounter_Driving_Cycles_Since_Last_Failed.ReadData
            OpServerCallDem_SatelliteMainFunction_ReadData_CBReadData_DID_0x10d_Valve_Status_FR: operation=CBReadData_DID_0x10d_Valve_Status_FR.ReadData
            OpServerCallDem_SatelliteMainFunction_ReadData_CBReadData_DID_0x10a_Wheel_Voltage_RR: operation=CBReadData_DID_0x10a_Wheel_Voltage_RR.ReadData
            OpServerCallDem_SatelliteMainFunction_ReadData_CBReadData_DID_0x10a_Wheel_Voltage_FR: operation=CBReadData_DID_0x10a_Wheel_Voltage_FR.ReadData
            OpServerCallDem_SatelliteMainFunction_ReadData_CBReadData_DID_0x10a_Wheel_Voltage_FL: operation=CBReadData_DID_0x10a_Wheel_Voltage_FL.ReadData
            OpServerCallDem_SatelliteMainFunction_ReadData_CBReadData_DID_0x10d_Valve_Status_RR: operation=CBReadData_DID_0x10d_Valve_Status_RR.ReadData
            OpServerCallDem_SatelliteMainFunction_ReadData_CBReadData_DID_0x10a_Wheel_Speed_RL: operation=CBReadData_DID_0x10a_Wheel_Speed_RL.ReadData
            OpServerCallDem_SatelliteMainFunction_ReadData_CBReadData_DID_0x10a_Wheel_Speed_RR: operation=CBReadData_DID_0x10a_Wheel_Speed_RR.ReadData
            OpServerCallDem_SatelliteMainFunction_ReadData_CBReadData_DID_0x10a_Wheel_Speed_FL: operation=CBReadData_DID_0x10a_Wheel_Speed_FL.ReadData
            OpServerCallDem_SatelliteMainFunction_ReadData_CBReadData_DID_0x10d_Valve_Status_FL: operation=CBReadData_DID_0x10d_Valve_Status_FL.ReadData
            OpServerCallDem_SatelliteMainFunction_ReadData_CBReadData_DID_0x10a_Direction_of_rotation: operation=CBReadData_DID_0x10a_Direction_of_rotation.ReadData
            OpServerCallDem_SatelliteMainFunction_ReadData_CBReadData_DID_0x10d_Valve_Voltage_FL: operation=CBReadData_DID_0x10d_Valve_Voltage_FL.ReadData
            OpServerCallDem_SatelliteMainFunction_ReadData_CBReadData_DID_0x10a_Wheel_Speed_FR: operation=CBReadData_DID_0x10a_Wheel_Speed_FR.ReadData
            OpServerCallDem_SatelliteMainFunction_ReadData_CBReadData_DID_0x10d_Valve_Voltage_FR: operation=CBReadData_DID_0x10d_Valve_Voltage_FR.ReadData
            OpServerCallDem_SatelliteMainFunction_ReadData_CBReadData_OccurrenceCounter_Driving_Cycles_Since_Test_Failed: operation=CBReadData_OccurrenceCounter_Driving_Cycles_Since_Test_Failed.ReadData
            OpServerCallDem_SatelliteMainFunction_ReadData_CBReadData_DID_0x10d_Valve_Status_RL: operation=CBReadData_DID_0x10d_Valve_Status_RL.ReadData
        GetEventUdsStatus: can-be-invoked-concurrently=true, symbol=Dem_GetEventUdsStatus
        GetEventStatus: can-be-invoked-concurrently=true, symbol=Dem_GetEventUdsStatus
        GetEventFailed: can-be-invoked-concurrently=true, symbol=Dem_GetEventFailed
        GetEventTested: can-be-invoked-concurrently=true, symbol=Dem_GetEventTested
        GetDTCOfEvent: can-be-invoked-concurrently=true, symbol=Dem_GetDTCOfEvent
        GetFaultDetectionCounter: can-be-invoked-concurrently=true, symbol=Dem_GetFaultDetectionCounter
        GetEventFreezeFrameDataEx: can-be-invoked-concurrently=true, symbol=Dem_GetEventFreezeFrameDataEx
        GetEventExtendedDataRecordEx: can-be-invoked-concurrently=true, symbol=Dem_GetEventExtendedDataRecordEx
        GetEventEnableCondition: can-be-invoked-concurrently=true, symbol=Dem_GetEventEnableCondition
        GetDebouncingOfEvent: can-be-invoked-concurrently=true, symbol=Dem_GetDebouncingOfEvent
        GetMonitorStatus: can-be-invoked-concurrently=true, symbol=Dem_GetMonitorStatus
        SetEventStatus: can-be-invoked-concurrently=true, symbol=Dem_SetEventStatus
        ResetEventStatus: can-be-invoked-concurrently=true, symbol=Dem_ResetEventStatus
        ResetEventDebounceStatus: can-be-invoked-concurrently=true, symbol=Dem_ResetEventDebounceStatus
  swc implementation DemSatellite_0Implementation: programming-language=C, behavior=DemSatellite_0InternalBehavior
